VERSION ""

NS_ :

BS_:

BU_: MCU IPU MCU_B BMS ECC VCU EVCC MCU_F HDCU LBMS VCU5_0 VCU_BMS GW EOP Tester IDC

BO_ 384 EOP_1: 64 EOP
 SG_ EOP_1_CRC : 7|16@0+ (1,0) [0|65535] ""  MCU,VCU
 SG_ EOP_1_Counter : 23|8@0+ (1,0) [0|255] ""  MCU,VCU
 SG_ EOP_SpdAct : 29|12@0+ (1,0) [0|4000] "rpm"  MCU,VCU
 SG_ EOP_IdcAct : 55|8@0+ (0.1,0) [0|25] "A"  MCU,VCU
 SG_ EOP_IphAct : 33|10@0+ (0.1,0) [0|50] "A"  MCU,VCU
 SG_ EOP_UdcAct : 63|8@0+ (0.1,0) [0|25] "V"  MCU,VCU
 SG_ EOP_Status : 71|3@0+ (1,0) [0|4] ""  MCU,VCU
 SG_ EOP_duty : 79|7@0+ (1,0) [0|100] "%"  MCU,VCU
 SG_ EOP_ErrLevel : 68|3@0+ (1,0) [0|7] ""  MCU,VCU

BO_ 2015 Fun_Diag_Rx: 64 Tester
 SG_ Fun_Diag_Request : 7|512@0+ (1,0) [0|0] ""  MCU

BO_ 1790 NIDU_UDS_Diag_Tx: 64 MCU
 SG_ NIDU_UDS_Diag_Response : 7|64@0+ (1,0) [0|0] ""  Tester

BO_ 1662 NIDU_UDS_Diag_Rx: 64 Tester
 SG_ NIDU_UDS_Diag_Request : 7|64@0+ (1,0) [0|0] ""  MCU

BO_ 2028 NIDU_OBD_Diag_Tx: 64 MCU
 SG_ NIDU_OBD_Diag_Response : 7|64@0+ (1,0) [0|0] ""  Tester

BO_ 2020 NIDU_OBD_Diag_Rx: 64 Tester
 SG_ NIDU_OBD_Diag_Request : 7|64@0+ (1,0) [0|0] ""  MCU

BO_ 2683306023 DCU_1: 64 MCU
 SG_ DCU_1_CRC : 7|16@0+ (1,0) [0|65535] ""  VCU,GW,BMS
 SG_ DCU_1_Counter : 23|8@0+ (1,0) [0|255] ""  VCU,GW,BMS
 SG_ DCU_RotSpdAct : 31|16@0+ (1,-32767) [-32767|32766] "rpm"  VCU,GW
 SG_ DCU_IdcAct : 47|11@0+ (1,-1023) [-1023|1024] "A"  VCU,GW,BMS
 SG_ DCU_UdcAct : 52|10@0+ (1,0) [0|1023] "V"  VCU,GW,BMS
 SG_ DCU_ErrorLv3St : 58|1@0+ (1,0) [0|1] ""  VCU
 SG_ DCU_CCUEOPPowerSup : 57|2@0+ (1,0) [0|3] ""  VCU
 SG_ DCU_ModeSt : 79|4@0+ (1,0) [0|15] ""  VCU,BMS
 SG_ DCU_TorqMax : 75|10@0+ (1,0) [0|1023] "Nm"  VCU,GW
 SG_ DCU_TorqMin : 95|10@0+ (1,-1023) [-1023|0] "Nm"  VCU,GW
 SG_ DCU_SelfTorqMax : 101|10@0+ (1,0) [0|1023] "Nm"  VCU,GW
 SG_ DCU_SelfTorqMin : 106|10@0+ (1,-1023) [-1023|0] "Nm"  VCU,GW
 SG_ DCU_DstActive : 112|1@0+ (1,0) [0|1] ""  VCU,GW
 SG_ DCU_GateDrvSt : 127|2@0+ (1,0) [0|3] ""  VCU
 SG_ DCU_DiagErrCode : 125|6@0+ (1,0) [0|63] ""  VCU
 SG_ DCU_DMCInternalTorqSet : 134|11@0+ (1,-1023) [-1023|1024] "Nm"  Tester
 SG_ DCU_DMCInternalInit : 135|1@0+ (1,0) [0|1] ""  Tester
 SG_ DCU_DMCInternalInputQF : 107|1@0+ (1,0) [0|1] ""  Tester
 SG_ DCU_DMCOperationStToBCS : 139|3@0+ (1,0) [0|7] ""  VCU
 SG_ DCU_DMCoutputTorqToBCS : 136|16@0+ (1,-30000) [-30000|30000] "Nm"  VCU
 SG_ DCU_DMCVariantInfoToBCS : 175|6@0+ (1,0) [0|63] ""  VCU
 SG_ DCU_DMCVersionInfoToBCS : 167|8@0+ (1,0) [0|255] ""  VCU
 SG_ DCU_TorqAct : 169|13@0+ (0.2,-819) [-819|819] "Nm"  VCU
 SG_ DCU_EOP_SpdSet : 188|12@0+ (1,0) [0|4000] "rpm"  VCU
 SG_ DCU_Fault2 : 299|30@0+ (1,0) [0|1073741823] ""  VCU
 SG_ DCU_Fault3 : 265|30@0+ (1,0) [0|1073741823] ""  VCU
 SG_ DCU_Fault6 : 247|30@0+ (1,0) [0|1073741823] ""  VCU
 SG_ DCU_TrefFinal : 333|11@0+ (1,-1000) [-1000|1047] ""  VCU
 SG_ DCU_Iq : 338|15@0+ (0.1,-1500) [-1500|1776.7] ""  VCU
 SG_ DCU_Id : 355|15@0+ (0.1,-1500) [-1500|1776.7] ""  VCU
 SG_ DCU_iCurqRef : 372|15@0+ (0.1,-1500) [-1500|1776.7] ""  VCU
 SG_ DCU_iCurdRef : 389|15@0+ (0.1,-1500) [-1500|1776.7] ""  VCU
 SG_ DCU_1_FreshnessValue : 455|16@0+ (1,0) [0|255] ""  Tester
 SG_ DCU_1_MAC_Check : 471|48@0+ (1,0) [0|255] ""  Tester

BO_ 2683306024 DCU_2: 64 MCU
 SG_ DCU_Fault1 : 473|30@0+ (1,0) [0|1073741823] ""  VCU,GW
 SG_ DCU_2_CRC : 7|16@0+ (1,0) [0|65535] ""  VCU,GW
 SG_ DCU_2_Counter : 23|8@0+ (1,0) [0|255] ""  VCU,GW
 SG_ DCU_BoostChgPwrMax : 31|7@0+ (1,0) [0|120] "kW"  VCU,GW
 SG_ DCU_AHF_ActPwr : 24|10@0+ (20,0) [0|20460] "W"  VCU,GW
 SG_ DCU_RemoteDiagCode : 56|2@0+ (1,0) [0|3] ""  GW
 SG_ DCU_TypeSt : 70|4@0+ (1,0) [0|15] ""  VCU
 SG_ DCU_bDiagReq : 66|1@0+ (1,0) [0|1] ""  GW
 SG_ DCU_bReadyHV : 65|1@0+ (1,0) [0|1] ""  GW
 SG_ DCU_OffsetCalInd : 64|1@0+ (1,0) [0|1] ""  VCU
 SG_ DCU_DisChgPwrMax : 79|7@0+ (1,0) [0|120] "kW"  VCU
 SG_ DCU_InvtTemp : 72|8@0+ (1,-40) [-40|215] "degC"  VCU
 SG_ DCU_VoltageT30 : 80|6@0+ (0.5,0) [0|31.5] "V"  GW
 SG_ DCU_SysTempOvrInd : 90|1@0+ (1,0) [0|1] ""  GW
 SG_ DCU_RotTemp : 89|9@0+ (1,-40) [-40|471] "degC"  VCU
 SG_ DCU_CooltReq : 96|6@0+ (0.25,0) [0|15.5] "L/min"  VCU
 SG_ DCU_FaultLampInd : 106|1@0+ (1,0) [0|1] ""  VCU,GW
 SG_ DCU_StatTemp : 105|9@0+ (1,-40) [-40|470] "degC"  VCU
 SG_ DCU_TempCoolant : 112|8@0+ (1,-40) [-40|215] "degC"  VCU,GW
 SG_ DCU_ErrNoticeOperationFlag : 120|1@0+ (1,0) [0|1] ""  VCU,GW
 SG_ DCU_ErrNotice : 135|3@0+ (1,0) [0|7] ""  VCU,GW
 SG_ DCU_Err2NoticeFlag : 132|1@0+ (1,0) [0|1] ""  VCU,GW
 SG_ DCU_Fault5 : 138|30@0+ (1,0) [0|1073741823] ""  VCU,GW
 SG_ DCU_TEL_MotorNumOrder : 194|3@0+ (1,0) [0|7] ""  VCU,GW
 SG_ DCU_TEL_ECUTempOvrErr : 195|1@0+ (1,0) [0|1] ""  VCU,GW
 SG_ DCU_TEL_MotTempOvrErr : 196|1@0+ (1,0) [0|1] ""  VCU,GW
 SG_ DCU_TEL_MotorNumTotal : 199|3@0+ (1,0) [0|7] ""  VCU,GW
 SG_ DCU_TEL_InvtTemp : 207|8@0+ (1,-40) [-40|215] "deg"  VCU,GW
 SG_ DCU_TEL_RotSpdAct : 215|16@0+ (1,-20000) [-20000|45535] "rpm"  VCU,GW
 SG_ DCU_TEL_TorqAct : 231|16@0+ (0.1,-2000) [-2000|4553.5] "Nm"  VCU,GW
 SG_ DCU_TEL_StatTemp : 247|8@0+ (1,-40) [-40|215] "deg"  VCU,GW
 SG_ DCU_TEL_ModeSt : 293|3@0+ (1,0) [0|7] ""  VCU,GW
 SG_ DCU_TEL_CurrActAmend : 255|16@0+ (0.1,-1000) [-1000|1000] "A"  VCU,GW
 SG_ DCU_TEL_UdcAct : 181|14@0+ (0.1,0) [0|1000] "V"  VCU,GW
 SG_ DCU_TEL_BattCurr : 271|16@0+ (0.1,-1000) [-1000|1000] "A"  VCU,GW
 SG_ DCU_BoostCurrMax : 55|8@0+ (1,0) [0|255] "A"  VCU
 SG_ DCU_BuckCurrMax : 131|8@0+ (1,0) [0|255] "A"  VCU
 SG_ DCU_K2RlyAdhmode : 139|1@0+ (1,0) [0|1] ""  VCU,BMS
 SG_ DCU_IgnitionSt : 439|1@0+ (1,0) [0|1] ""  VCU
 SG_ DCU_TEL_OverSpdErr : 171|1@0+ (1,0) [0|1] ""  VCU
 SG_ DCU_TEL_OverCurrErr : 172|1@0+ (1,0) [0|1] ""  VCU
 SG_ Reserved1 : 440|1@0+ (1,0) [0|0] ""  VCU
 SG_ DCU_Fault4 : 455|30@0+ (1,0) [0|1073741823] ""  VCU

BO_ 408 BMC_1: 64 BMS
 SG_ BMC_1_CRC : 7|16@0+ (1,0) [0|65535] ""  MCU
 SG_ BMC_1_Counter : 23|8@0+ (1,0) [0|255] ""  MCU
 SG_ BMC_BattVolt : 54|10@0+ (1,0) [0|1000] "V"  MCU
 SG_ BMC_DCUBattSt : 56|1@0+ (1,0) [0|1] ""  MCU
 SG_ BMC_PwrDwnReq : 71|1@0+ (1,0) [0|1] ""  MCU
 SG_ BMC_BoostChgModeReq : 68|2@0+ (1,0) [0|3] ""  MCU

BO_ 2683306021 DCU_DEBUG_1: 32 MCU
 SG_ DCU_BSWVersion_Debug : 112|32@0+ (1,0) [0|4294967295] ""  Tester
 SG_ DCU_OffsetCalSt : 114|2@0+ (1,0) [0|3] ""  Tester
 SG_ DCU_OffsetAngleCal : 15|16@0+ (1,0) [0|65535] ""  Tester
 SG_ DCU_EOP_OilTempAct : 7|8@0+ (1,-40) [-40|180] "degC"  Tester
 SG_ DCU_Debug_1Bit_1 : 95|1@0+ (1,0) [0|1] "-"  Tester
 SG_ DCU_Ignition : 94|1@0+ (1,0) [0|1] ""  Tester
 SG_ DCU_OffsetAngle_Debug : 91|12@0+ (1,0) [0|4095] "-"  Tester
 SG_ DCU_StoreDataSt : 93|2@0+ (1,0) [0|3] ""  Tester
 SG_ DCU_SendDataSt : 115|1@0+ (1,0) [0|1] ""  Tester
 SG_ DCU_BootSV_Debug : 111|12@0+ (1,0) [0|4095] "-"  Tester
 SG_ DCU_Hwversion_Debug : 31|16@0+ (1,0) [0|65535] "-"  Tester
 SG_ DCU_Swversion_Debug : 47|16@0+ (1,0) [0|65535] "-"  Tester
 SG_ DCU_SwVerExt_Debug : 63|32@0+ (1,0) [0|4294967295] "-"  Tester

BO_ 2683306010 DCU_DEBUG_2: 32 MCU
 SG_ DCU_CapTemp_Debug : 23|8@0+ (1,-40) [-40|215] "degC"  Tester
 SG_ DCU_CtlBoardTemp_Debug : 15|8@0+ (1,-40) [-40|215] "degC"  Tester
 SG_ DCU_PWMFreq_Debug : 63|12@0+ (10,0) [0|40950] "Hz"  Tester
 SG_ DCU_IgbtNtcTempMax : 7|8@0+ (1,-40) [-40|215] "degC"  Tester
 SG_ DCU_Debug_1Bit_2 : 67|1@0+ (1,0) [0|1] "-"  Tester
 SG_ DCU_Debug_1Bit_3 : 66|1@0+ (1,0) [0|1] ""  Tester
 SG_ DCU_Debug_16Bit_2 : 31|16@0+ (1,0) [0|65535] ""  Tester
 SG_ DCU_Debug_16Bit_3 : 47|16@0+ (1,0) [0|65535] ""  Tester

BO_ 2683305995 DCU_DEBUG_3: 64 MCU
 SG_ DCU_FusaFaultInfo8_Debug : 461|32@0+ (1,0) [0|4294967295] ""  Tester
 SG_ DCU_FusaFaultInfo7_Debug : 429|32@0+ (1,0) [0|4294967295] ""  Tester
 SG_ DCU_TempCoolant : 421|8@0+ (1,-40) [-40|215] "degC"  Tester
 SG_ DCU_FusaTorqAct_Debug : 402|13@0+ (0.2,-819) [-819|819] ""  Tester
 SG_ DCU_FusaRotSpdAct_Debug : 386|16@0+ (1,-32767) [-32767|32766] ""  Tester
 SG_ DCU_FusaErrCode_Debug : 376|6@0+ (1,0) [0|63] ""  Tester
 SG_ DCU_FusastPWMEna_Debug : 377|1@0+ (1,0) [0|1] ""  Tester
 SG_ DCU_FusaQDisChargeReq_Debug : 378|1@0+ (1,0) [0|0] ""  Tester
 SG_ DCU_FusaModeSt_Debug : 382|4@0+ (1,0) [0|15] ""  Tester
 SG_ DCU_FusastSafePathReq_Debug : 369|3@0+ (1,0) [0|7] ""  Tester
 SG_ DCU_DataFaultHandle : 373|4@0+ (1,0) [0|15] ""  Tester
 SG_ DCU_stTorqLmtTsc : 240|22@0+ (1,0) [0|4194303] "-"  Tester
 SG_ DCU_TrqAntiJerk : 7|8@0+ (1,-127) [-127|128] "Nm"  Tester
 SG_ DCU_TrefFinal_Debug : 266|11@0+ (1,-1000) [-1000|1047] "Nm"  Tester
 SG_ DCU_Iq_Debug : 287|15@0+ (0.1,-1500) [-1500|1776.7] "A"  Tester
 SG_ DCU_Id_Debug : 288|15@0+ (0.1,-1500) [-1500|1776.7] "A"  Tester
 SG_ DCU_Debug_1Bit_4 : 239|1@0+ (1,0) [0|1] ""  Tester
 SG_ DCU_Debug_8Bit_4 : 15|8@0+ (1,0) [0|255] "-"  Tester
 SG_ DCU_Debug_16Bit_4 : 23|16@0+ (1,0) [0|65535] "-"  Tester
 SG_ DCU_Fault6_Debug : 39|32@0+ (1,0) [0|65535] ""  Tester
 SG_ DCU_Fault5_Debug : 71|32@0+ (1,0) [0|65535] "-"  Tester
 SG_ DCU_Fault4_Debug : 103|32@0+ (1,0) [0|65535] "-"  Tester
 SG_ DCU_Fault3_Debug : 135|32@0+ (1,0) [0|1048575] "-"  Tester
 SG_ DCU_Fault2_Debug : 167|32@0+ (1,0) [0|1048575] "-"  Tester
 SG_ DCU_Fault1_Debug : 199|32@0+ (1,0) [0|1048575] "-"  Tester
 SG_ DCU_TjMax : 231|8@0+ (1,-40) [-40|215] "degC"  Tester
 SG_ DCU_VoltUtilRatio : 238|7@0+ (0.01,0) [0|1.27] ""  Tester
 SG_ DCU_TorqueRatio : 247|7@0+ (0.01,0) [0|1.27] ""  Tester
 SG_ DCU_iCurqRef_Debug : 305|15@0+ (0.1,-1500) [-1500|1776.7] "A"  Tester
 SG_ DCU_iCurdRef_Debug : 322|15@0+ (0.1,-1500) [-1500|1776.7] "A"  Tester
 SG_ DCU_uVoltqRef : 339|15@0+ (0.1,-1500) [-1500|1776.7] "V"  Tester
 SG_ DCU_uVoltdRef : 356|15@0+ (0.1,-1500) [-1500|1776.7] "V"  Tester

BO_ 2683305999 DCU_DEBUG_6: 32 MCU
 SG_ DCU_Debug_IdcEst : 59|15@0+ (0.1,-1500) [-1500|1776.7] "A"  Tester
 SG_ DCU_Debug_TorqEstByPower : 42|15@0+ (0.1,-1500) [-1500|1776.7] "Nm"  Tester
 SG_ DCU_Debug_TorqEstByTable : 25|15@0+ (0.1,-1500) [-1500|1776.7] "Nm"  Tester
 SG_ DCU_Debug_Iq : 8|15@0+ (0.1,-1500) [-1500|1776.7] "A"  Tester
 SG_ DCU_Debug_Id : 7|15@0+ (0.1,-1500) [-1500|1776.7] "A"  Tester

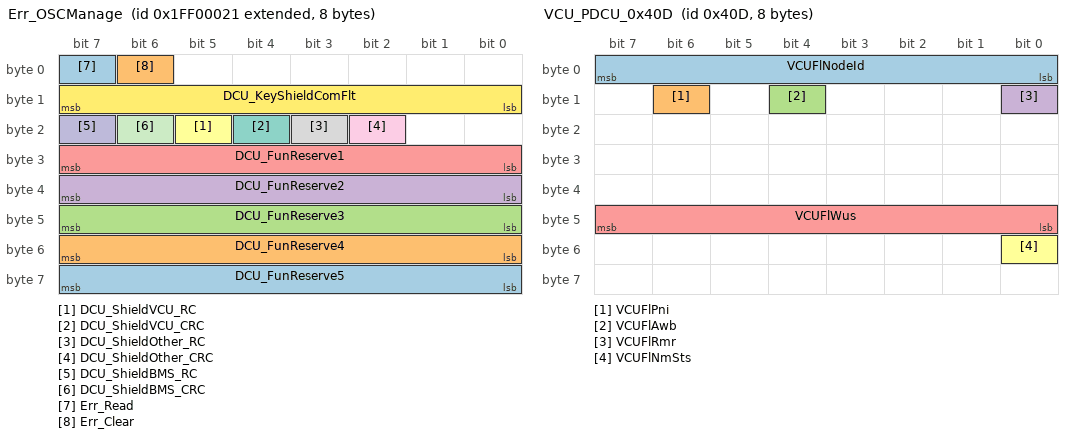
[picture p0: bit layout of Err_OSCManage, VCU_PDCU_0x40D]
BO_ 2683306017 Err_OSCManage: 8 Tester
 SG_ DCU_FunReserve5 : 63|8@0+ (1,0) [0|255] "-"  Tester
 SG_ DCU_FunReserve4 : 55|8@0+ (1,0) [0|255] "-"  Tester
 SG_ DCU_FunReserve3 : 47|8@0+ (1,0) [0|255] "-"  Tester
 SG_ DCU_FunReserve2 : 39|8@0+ (1,0) [0|255] "-"  Tester
 SG_ DCU_FunReserve1 : 31|8@0+ (1,0) [0|255] "-"  Tester
 SG_ DCU_ShieldVCU_RC : 21|1@0+ (1,0) [0|1] "-"  Tester
 SG_ DCU_ShieldVCU_CRC : 20|1@0+ (1,0) [0|1] "-"  Tester
 SG_ DCU_ShieldOther_RC : 19|1@0+ (1,0) [0|1] "-"  Tester
 SG_ DCU_ShieldOther_CRC : 18|1@0+ (1,0) [0|1] "-"  Tester
 SG_ DCU_ShieldBMS_RC : 23|1@0+ (1,0) [0|1] "-"  Tester
 SG_ DCU_ShieldBMS_CRC : 22|1@0+ (1,0) [0|1] "-"  Tester
 SG_ DCU_KeyShieldComFlt : 15|8@0+ (1,0) [0|255] "-"  Tester
 SG_ Err_Read : 7|1@0+ (1,0) [0|1] ""  MCU
 SG_ Err_Clear : 6|1@0+ (1,0) [0|0] ""  MCU

BO_ 2634022913 XCP_Frame_Tx: 8 MCU
 SG_ XCP_Data_Tx : 7|64@0+ (1,0) [0|0] ""  Tester

BO_ 2634022912 XCP_Frame_Rx: 8 Tester
 SG_ XCP_Data_Rx : 7|64@0+ (1,0) [0|0] ""  MCU

BO_ 2683306022 DCU_BigData: 64 MCU
 SG_ DCU_BigNO1_1Bit2 m1 : 504|1@0+ (1,0) [0|1] "-"  Tester
 SG_ DCU_BigNO1_1Bit1 m1 : 505|1@0+ (1,0) [0|1] "-"  Tester
 SG_ DCU_stL2TorqRep m1 : 488|1@0+ (1,0) [0|1] "-"  Tester
 SG_ DCU_stL2SpdRep m1 : 503|1@0+ (1,0) [0|1] "-"  Tester
 SG_ DCU_stL2DCVoltRep m1 : 502|1@0+ (1,0) [0|1] "-"  Tester
 SG_ DCU_BigNO1_8Bit1 m1 : 501|8@0+ (1,0) [0|255] "-"  Tester
 SG_ DCU_BigNO1_4Bit1 m1 : 509|4@0+ (1,0) [0|15] "-"  Tester
 SG_ DCU_stL2SignalRep m2 : 460|2@0+ (1,0) [0|3] ""  Tester
 SG_ DCU_stL2ShutOff m2 : 463|3@0+ (1,0) [0|7] ""  Tester
 SG_ DCU_stFbTopASC m2 : 458|1@0+ (1,0) [0|1] "-"  Tester
 SG_ DCU_stFbFSEnb m2 : 456|1@0+ (1,0) [0|1] "-"  Tester
 SG_ DCU_stFbBottomASC m2 : 457|1@0+ (1,0) [0|1] "-"  Tester
 SG_ DCU_McaWT_Duty m2 : 487|8@0+ (1,0) [0|255] ""  Tester
 SG_ DCU_McaVT_Duty m2 : 479|8@0+ (1,0) [0|255] ""  Tester
 SG_ DCU_McaUT_Duty m2 : 471|8@0+ (1,0) [0|255] ""  Tester
 SG_ DCU_ResInCosVal m2 : 503|8@0+ (80,-10200) [-10200|10200] ""  Tester
 SG_ DCU_FbVB_Duty m2 : 447|8@0+ (1,0) [0|255] ""  Tester
 SG_ DCU_TopDrvICInitflg m1 : 492|1@0+ (1,0) [0|1] "-"  Tester
 SG_ DCU_IsLmtL2 m1 : 432|10@0+ (1,0) [0|1023] ""  Tester
 SG_ DCU_iPhaCurWOfs m1 : 460|10@0+ (4,0) [0|4092] ""  Tester
 SG_ DCU_iPhaCurVOfs m1 : 466|10@0+ (4,0) [0|4092] ""  Tester
 SG_ DCU_iPhaCurUOfs m1 : 454|10@0+ (4,0) [0|4092] ""  Tester
 SG_ DCU_CapTempEst m1 : 472|8@0+ (1,-40) [-40|214] "degC"  Tester
 SG_ DCU_BomDrvICInitflg m1 : 491|1@0+ (1,0) [0|1] "-"  Tester
 SG_ DCU_uDCVoltL2 m1 : 427|11@0+ (1,0) [0|2047] ""  Tester
 SG_ DCU_FusastL2SPCflg m1 : 489|1@0+ (1,0) [0|1] ""  Tester
 SG_ DCU_FusastL3SPCflg m1 : 490|1@0+ (1,0) [0|1] ""  Tester
 SG_ DCU_FusaInModeSt m1 : 480|4@0+ (1,0) [0|15] ""  Tester
 SG_ DCU_uDrvLVBackupVolt m2 : 511|8@0+ (1,0) [0|255] ""  Tester
 SG_ DCU_Data1No M : 7|8@0+ (1,0) [0|205] ""  Tester
 SG_ DCU_Hwversion m1 : 15|16@0+ (1,0) [0|65535] ""  Tester
 SG_ DCU_Swversion m1 : 31|16@0+ (1,0) [0|65535] ""  Tester
 SG_ DCU_SwVerExt m1 : 47|32@0+ (1,0) [0|4294967295] ""  Tester
 SG_ DCU_OffsetAngle m1 : 79|12@0+ (1,0) [0|4095] ""  Tester
 SG_ DCU_BootSV m1 : 83|12@0+ (1,0) [0|4095] ""  Tester
 SG_ DCU_BSWVersion m1 : 103|32@0+ (1,0) [0|4294967295] ""  Tester
 SG_ DCU_HWConfig m1 : 135|32@0+ (1,0) [0|4294967295] ""  Tester
 SG_ DCU_SWConfig m1 : 167|32@0+ (1,0) [0|4294967295] ""  Tester
 SG_ DCU_MCAConfig m1 : 199|32@0+ (1,0) [0|4294967295] ""  Tester
 SG_ DCU_FHConfig m1 : 231|32@0+ (1,0) [0|4294967295] ""  Tester
 SG_ DCU_InvtPhaUTemp m1 : 263|8@0+ (1,-40) [-40|214] "degC"  Tester
 SG_ DCU_InvtPhaVTemp m1 : 271|8@0+ (1,-40) [-40|214] "degC"  Tester
 SG_ DCU_InvtPhaWTemp m1 : 279|8@0+ (1,-40) [-40|214] "degC"  Tester
 SG_ DCU_Stat1Temp m1 : 287|8@0+ (1,-40) [-40|214] "degC"  Tester
 SG_ DCU_Stat2Temp m1 : 295|8@0+ (1,-40) [-40|214] "degC"  Tester
 SG_ DCU_CtrlBoardTemp m1 : 303|8@0+ (1,-40) [-40|214] "degC"  Tester
 SG_ DCU_DrvBoardTemp m1 : 311|8@0+ (1,-40) [-40|214] "degC"  Tester
 SG_ DCU_CapTemp m1 : 319|8@0+ (1,-40) [-40|214] "degC"  Tester
 SG_ DCU_FusastSafePathReq m1 : 327|3@0+ (1,0) [0|7] ""  Tester
 SG_ DCU_FusaModeSt m1 : 324|4@0+ (1,0) [0|15] ""  Tester
 SG_ DCU_FusaQDisChargeReq m1 : 320|1@0+ (1,0) [0|1] ""  Tester
 SG_ DCU_FusastPWMEna m1 : 335|1@0+ (1,0) [0|1] ""  Tester
 SG_ DCU_FusaErrCode m1 : 334|6@0+ (1,0) [0|63] ""  Tester
 SG_ DCU_FusaRotSpdAct m1 : 328|16@0+ (1,-32767) [-32767|32766] ""  Tester
 SG_ DCU_FusaTorqAct m1 : 344|13@0+ (0.2,-819) [-819|819] ""  Tester
 SG_ DCU_FusaFaultInfo7 m1 : 363|32@0+ (1,0) [0|4294967295] ""  Tester
 SG_ DCU_FusaFaultInfo8 m1 : 395|32@0+ (1,0) [0|4294967295] ""  Tester
 SG_ DCU_FaultData_RC m2 : 15|8@0+ (1,0) [0|255] ""  Tester
 SG_ DCU_stHandleOff m2 : 23|1@0+ (1,0) [0|1] ""  Tester
 SG_ DCU_stPWMEna m2 : 22|1@0+ (1,0) [0|1] ""  Tester
 SG_ DCU_stMode m2 : 21|4@0+ (1,0) [0|15] ""  Tester
 SG_ DCU_FailCode m2 : 17|10@0+ (1,0) [0|1023] ""  Tester
 SG_ DCU_stASCProt m2 : 39|16@0+ (1,0) [0|65535] ""  Tester
 SG_ DCU_agRotorPosn m2 : 55|12@0+ (1,0) [0|4095] ""  Tester
 SG_ DCU_RelativeTime m2 : 193|18@0+ (1,0) [0|262143] "s"  Tester
 SG_ DCU_stFaultFlag100us m2 : 223|16@0+ (1,0) [0|65535] ""  Tester
 SG_ DCU_PWMFreq m2 : 239|16@0+ (1,0) [0|65535] "Hz"  Tester
 SG_ DCU_uDcVolt m2 : 255|10@0+ (1,0) [0|1023] "V"  Tester
 SG_ DCU_uLowVolt m2 : 261|8@0+ (0.1,0) [0|25.5] "V"  Tester
 SG_ DCU_iCurdFinalRef m2 : 59|12@0+ (1,-2048) [-2048|2047] "A"  Tester
 SG_ DCU_iCurqFinalRef m2 : 79|12@0+ (1,-2048) [-2048|2047] "A"  Tester
 SG_ DCU_iCurdFb m2 : 83|12@0+ (1,-2048) [-2048|2047] "A"  Tester
 SG_ DCU_iCurqFb m2 : 103|12@0+ (1,-2048) [-2048|2047] "A"  Tester
 SG_ DCU_iPhaCurU m2 : 107|12@0+ (1,-2048) [-2048|2047] "A"  Tester
 SG_ DCU_iPhaCurV m2 : 127|12@0+ (1,-2048) [-2048|2047] "A"  Tester
 SG_ DCU_iPhaCurW m2 : 131|12@0+ (1,-2048) [-2048|2047] "A"  Tester
 SG_ DCU_uVoltdFinalRef m2 : 151|12@0+ (1,-2048) [-2048|2047] "V"  Tester
 SG_ DCU_uVoltqFinalRef m2 : 155|12@0+ (1,-2048) [-2048|2047] "V"  Tester
 SG_ DCU_iDcCur m2 : 175|12@0+ (1,-2048) [-2048|2047] "A"  Tester
 SG_ DCU_ResFaultFlag m2 : 269|16@0+ (1,0) [0|65535] ""  Tester
 SG_ DCU_stTsc m2 : 285|16@0+ (1,0) [0|65535] ""  Tester
 SG_ DCU_OperatingCycle m2 : 179|18@0+ (1,0) [0|262143] ""  Tester
 SG_ DCU_Year m2 : 317|8@0+ (1,2000) [2000|2255] "Y"  Tester
 SG_ DCU_Month m2 : 325|4@0+ (1,0) [1|12] "M"  Tester
 SG_ DCU_Day m2 : 321|5@0+ (1,0) [1|31] "D"  Tester
 SG_ DCU_Hour m2 : 332|5@0+ (1,0) [0|23] "h"  Tester
 SG_ DCU_Minute m2 : 343|6@0+ (1,0) [0|59] "m"  Tester
 SG_ DCU_Second m2 : 337|6@0+ (1,0) [0|59] "s"  Tester
 SG_ DCU_stIgnition m2 : 355|1@0+ (1,0) [0|1] ""  Tester
 SG_ DCU_OverCurrCount m2 : 354|2@0+ (1,0) [0|3] ""  Tester
 SG_ DCU_stFS0B m2 : 352|1@0+ (1,0) [0|1] ""  Tester
 SG_ DCU_stDrvCtrlMode m2 : 359|4@0+ (1,0) [0|15] ""  Tester
 SG_ DCU_FbUT_Duty m2 : 415|8@0+ (1,0) [0|255] ""  Tester
 SG_ DCU_ResInSinVal m2 : 495|8@0+ (80,-10200) [-10200|10200] ""  Tester
 SG_ DCU_stIGBTFault m2 : 301|16@0+ (1,0) [0|65535] ""  Tester
 SG_ DCU_stBigDataTrigger m2 : 347|4@0+ (1,0) [0|15] ""  Tester
 SG_ DCU_RegUT_Duty m2 : 383|8@0+ (1,0) [0|255] ""  Tester
 SG_ DCU_RegVT_Duty m2 : 391|8@0+ (1,0) [0|255] ""  Tester
 SG_ DCU_RegWT_Duty m2 : 399|8@0+ (1,0) [0|255] ""  Tester
 SG_ DCU_tiTspwmExeTime m2 : 407|8@0+ (2,0) [0|510] ""  Tester
 SG_ DCU_FbVT_Duty m2 : 423|8@0+ (1,0) [0|255] ""  Tester
 SG_ DCU_FbWT_Duty m2 : 431|8@0+ (1,0) [0|255] ""  Tester
 SG_ DCU_FbUB_Duty m2 : 439|8@0+ (1,0) [0|255] ""  Tester
 SG_ DCU_FbWB_Duty m2 : 455|8@0+ (1,0) [0|255] ""  Tester
 SG_ DCU_stSBCFault m2 : 367|16@0+ (1,0) [0|65535] ""  Tester

BO_ 2683306093 IPS_Debug_3: 64 Tester
 SG_ IPS_FUSE_PASSWORD : 7|8@0+ (1,0) [0|255] ""  MCU
 SG_ IPS_FUSE_ENABLE5 : 47|8@0+ (1,0) [0|255] ""  MCU
 SG_ IPS_FUSE_ENABLE4 : 39|8@0+ (1,0) [0|255] ""  MCU
 SG_ IPS_FUSE_ENABLE3 : 31|8@0+ (1,0) [0|255] ""  MCU
 SG_ IPS_FUSE_ENABLE2 : 23|8@0+ (1,0) [0|255] ""  MCU
 SG_ IPS_FUSE_ENABLE1 : 15|8@0+ (1,0) [0|255] ""  MCU
 SG_ IPS_FUSE_ENABLE : 48|1@0+ (1,0) [0|1] ""  MCU

BO_ 2683306000 IPS_Debug_1: 64 Tester
 SG_ IPS_Password : 7|8@0+ (1,0) [0|255] "-"  MCU
 SG_ IPS_TEL_DCDCFaultLampInd2 : 8|1@0+ (1,0) [0|1] "-"  MCU
 SG_ IPS_TEL_DCDCTempOvrErr2 : 9|1@0+ (1,0) [0|1] "-"  MCU
 SG_ IPS_Disable_CC : 12|3@0+ (1,0) [0|7] ""  MCU
 SG_ IPS_Disable_CP : 15|3@0+ (1,0) [0|7] "-"  MCU
 SG_ IPS_Disable_RCChecksum : 16|1@0+ (1,0) [0|1] "-"  MCU
 SG_ IPS_DCDCSet : 17|1@0+ (1,0) [0|1] "-"  MCU
 SG_ IPS_OBCSet : 18|1@0+ (1,0) [0|1] ""  MCU
 SG_ IPS_OBCHvVoltLimSet : 19|1@0+ (1,0) [0|1] ""  MCU
 SG_ IPS_Disable_DCDCSelfChck : 20|1@0+ (1,0) [0|1] ""  MCU
 SG_ IPS_DCDCLvVoltSet : 31|10@0+ (0.1,0) [0|102.3] "V"  MCU
 SG_ IPS_OBCChgVoltReqManCal : 37|10@0+ (1,0) [0|1023] "V"  MCU
 SG_ IPS_OBCChgCurrReqManCal : 43|10@0+ (0.1,0) [0|102.3] "A"  MCU
 SG_ IPS_OBCDchgDcCurrLim : 49|10@0+ (0.1,0) [0|102.3] "A"  MCU

BO_ 2683306012 IPS_Debug_2: 64 MCU
 SG_ IPS_FUSA_Core1_DC_DisableFb : 77|1@0+ (1,0) [0|1] ""  Tester
 SG_ IPS_FUSA_OBCTemp3ADFb : 445|12@0+ (1,0) [0|4095] ""  Tester
 SG_ IPS_FUSA_OBCTemp2ADFb : 449|12@0+ (1,0) [0|4095] ""  Tester
 SG_ IPS_FUSA_OBCTemp1ADFb : 469|12@0+ (1,0) [0|4095] ""  Tester
 SG_ IPS_FUSA_LVCCVoltValueFb : 473|8@0+ (0.1,0) [0|25.5] "V"  Tester
 SG_ IPS_FUSA_LV40VVoltValueFb : 199|10@0+ (0.1,0) [0|102.3] ""  Tester
 SG_ IPS_FUSA_DCDCTemp2ADFb : 501|12@0+ (1,0) [0|4095] ""  Tester
 SG_ IPS_FUSA_DCDCTemp1ADFb : 481|12@0+ (1,0) [0|4095] ""  Tester
 SG_ IPS_FUSA_DCDCLvVsVoltValueFb : 421|9@0+ (0.1,0) [0|51.1] "V"  Tester
 SG_ IPS_FUSA_DCDCLvVsVoltADFb : 425|12@0+ (1,0) [0|4095] ""  Tester
 SG_ IPS_FUSA_DCDCLvVdVoltValueFb : 401|9@0+ (0.1,0) [0|51.1] "V"  Tester
 SG_ IPS_FUSA_DCDCLvVdVoltADFb : 397|12@0+ (1,0) [0|4095] ""  Tester
 SG_ IPS_FUSA_DCDCLvCur2ValueFb : 391|10@0+ (1,-511) [-511|512] "A"  Tester
 SG_ IPS_FUSA_DCDCLvCur2ADFb : 317|12@0+ (1,0) [0|4095] ""  Tester
 SG_ IPS_FUSA_DCDCLvCur1ValueFb : 297|10@0+ (1,-511) [-511|512] "A"  Tester
 SG_ IPS_FUSA_DCDCLvCur1ADFb : 293|12@0+ (1,0) [0|4095] ""  Tester
 SG_ IPS_FUSA_Core1_OBCSt : 98|3@0+ (1,0) [0|7] ""  Tester
 SG_ IPS_FUSA_Core1_MCUSBC_Byte6 : 383|8@0+ (1,0) [0|255] ""  Tester
 SG_ IPS_FUSA_Core1_MCUSBC_Byte5 : 375|8@0+ (1,0) [0|255] ""  Tester
 SG_ IPS_FUSA_Core1_MCUSBC_Byte4 : 367|8@0+ (1,0) [0|255] ""  Tester
 SG_ IPS_FUSA_Core1_MCUSBC_Byte3 : 359|8@0+ (1,0) [0|255] ""  Tester
 SG_ IPS_FUSA_Core1_MCUSBC_Byte2 : 351|8@0+ (1,0) [0|255] ""  Tester
 SG_ IPS_FUSA_Core1_MCUSBC_Byte1 : 343|8@0+ (1,0) [0|255] ""  Tester
 SG_ IPS_FUSA_Core1_MCUSBC_Byte0 : 335|8@0+ (1,0) [0|255] ""  Tester
 SG_ IPS_FUSA_Core1_LC_DisableFb : 76|1@0+ (1,0) [0|1] ""  Tester
 SG_ IPS_FUSA_Core1_LC_Ctrl_Req : 56|1@0+ (1,0) [0|1] ""  Tester
 SG_ IPS_FUSA_Core1_HIVLDCSt : 242|3@0+ (1,0) [0|7] ""  Tester
 SG_ IPS_FUSA_Core1_HIVLACSt : 74|3@0+ (1,0) [0|7] ""  Tester
 SG_ IPS_FUSA_Core1_DCSt : 205|3@0+ (1,0) [0|7] ""  Tester
 SG_ IPS_FUSA_Core1_DC_Ctrl_Req : 57|1@0+ (1,0) [0|1] ""  Tester
 SG_ IPS_FUSA_Core1_CCSt : 202|3@0+ (1,0) [0|7] ""  Tester
 SG_ IPS_FUSA_CC2ResValueFb : 287|10@0+ (10,0) [0|10230] "|?"  Tester
 SG_ IPS_DcdcVersion : 279|8@0+ (1,0) [0|255] ""  Tester
 SG_ IPS_LlcVersion : 271|8@0+ (1,0) [0|255] ""  Tester
 SG_ IPS_PfcVersion : 263|8@0+ (1,0) [0|255] ""  Tester
 SG_ IPS_ocm_AswVersion : 255|8@0+ (1,0) [0|255] ""  Tester
 SG_ IPS_DiagDtcSetSt : 8|1@0+ (1,0) [0|1] ""  Tester
 SG_ IPS_DiagClrErr : 9|1@0+ (1,0) [0|1] ""  Tester
 SG_ IPS_pwrObcChgCap : 7|14@0+ (0.01,0) [0|163.83] "KW"  Tester
 SG_ IPS_PfcPwrModeSt : 27|4@0+ (1,0) [0|15] ""  Tester
 SG_ IPS_tPfcTemp : 23|12@0+ (0.1,-50) [-50|359.5] "degC"  Tester
 SG_ IPS_LLcPwrModeSt : 43|4@0+ (1,0) [0|15] ""  Tester
 SG_ IPS_fCpFrq : 39|12@0+ (1,0) [0|4095] "Hz"  Tester
 SG_ IPS_DcdcPwrModeSt : 61|4@0+ (1,0) [0|15] ""  Tester
 SG_ IPS_reAcIsoRes : 55|10@0+ (1,0) [0|1023] "KOhm"  Tester
 SG_ IPS_smd_uDcdcLvVoltSet : 71|10@0+ (0.1,0) [0|102.3] "V"  Tester
 SG_ IPS_fmd_DcdcFaultStopEn : 92|1@0+ (1,0) [0|1] ""  Tester
 SG_ IPS_fmo_ObcFaultStopEn : 93|1@0+ (1,0) [0|1] ""  Tester
 SG_ IPS_smo_dDchgCpDucyc : 87|10@0+ (0.1,0) [0|100] "%"  Tester
 SG_ IPS_smo_IsoTestEn : 101|3@0+ (1,0) [0|7] ""  Tester
 SG_ IPS_fmd_FsDcdcPwrOffEn : 102|1@0+ (1,0) [0|1] ""  Tester
 SG_ IPS_smd_FsDcdcOvpSelfChckSt : 103|1@0+ (1,0) [0|1] ""  Tester
 SG_ IPS_smo_iObcDcCurrLim : 117|4@0+ (1,0) [0|15] ""  Tester
 SG_ IPS_smo_ObcModeSet : 111|10@0+ (0.1,0) [0|102.3] "A"  Tester
 SG_ IPS_smo_uObcDcVoltSet : 113|10@0+ (1,0) [0|1023] "V"  Tester
 SG_ IPS_RelaySts : 139|4@0+ (1,0) [0|15] ""  Tester
 SG_ IPS_DcdcRadTemp : 135|12@0+ (0.1,-50) [-50|359.5] "degC"  Tester
 SG_ IPS_PfcVbulk : 151|14@0+ (0.1,0) [0|1638.3] "V"  Tester
 SG_ IPS_iObcHvCurr : 153|10@0+ (0.1,0) [0|102.3] "A"  Tester
 SG_ IPS_fmo_ObcFaultReset : 171|1@0+ (1,0) [0|1] ""  Tester
 SG_ IPS_fmd_DcdcFaultReset : 172|1@0+ (1,0) [0|1] ""  Tester
 SG_ IPS_smo_Cp9vTiOut : 173|1@0+ (1,0) [0|1] ""  Tester
 SG_ IPS_smo_Cp12vTiOut : 174|1@0+ (1,0) [0|1] ""  Tester
 SG_ IPS_spd_NmReq : 91|4@0+ (1,0) [0|15] ""  Tester
 SG_ IPS_smd_iDcdcLvCurrLim : 170|9@0+ (1,0) [0|511] "A"  Tester
 SG_ IPS_spo_iObcCcCpAcCurrLim : 177|10@0+ (0.1,0) [0|102.3] "A"  Tester
 SG_ IPS_DcdcSRSts : 215|4@0+ (1,0) [0|15] ""  Tester
 SG_ IPS_LlcWorkFreq : 211|12@0+ (0.1,0) [0|409.5] ""  Tester
 SG_ IPS_DcdcBuckDuty : 231|10@0+ (0.1,0) [0|100] "%"  Tester
 SG_ IPS_uFsDcdcLvVolt : 237|10@0+ (0.1,0) [0|102.3] "V"  Tester

BO_ 2683306025 IPS_1: 64 MCU
 SG_ IPS_1_CRC : 7|16@0+ (1,0) [0|65535] ""  VCU,GW,BMS
 SG_ IPS_1_Counter : 23|8@0+ (1,0) [0|255] ""  VCU,GW,BMS
 SG_ IPS_DCDCDiagErrCode : 31|8@0+ (1,0) [0|255] ""  VCU,GW
 SG_ IPS_DCDCModeSt : 39|3@0+ (1,0) [0|7] ""  VCU,GW
 SG_ IPS_KL15State : 36|1@0+ (1,0) [0|1] ""  Tester
 SG_ IPS_DCDCVoltLvAct : 35|10@0+ (0.1,0) [0|102.3] "V"  VCU,GW
 SG_ IPS_DCDCCurrHvAct : 41|9@0+ (0.1,0) [0|51.1] "A"  GW,VCU,MCU_B
 SG_ IPS_DCDCCurrLvAct : 63|9@0+ (1,0) [0|511] "A"  GW,VCU
 SG_ IPS_SBCSafetyOutputSt : 75|1@0+ (1,0) [0|1] ""  VCU,GW
 SG_ IPS_DCDCVoltHvAct : 70|10@0+ (1,0) [0|1023] "V"  VCU,GW,MCU_B
 SG_ IPS_OBCDiagErrCode : 151|8@0+ (1,0) [0|255] ""  VCU,GW
 SG_ IPS_OBCCC_St : 159|3@0+ (1,0) [0|7] ""  GW,VCU,MCU_B,BMS
 SG_ IPS_OBCCC_Res : 156|10@0+ (10,0) [0|10230] "Ohm"  VCU,GW
 SG_ IPS_OBCDschDisable : 162|1@0+ (1,0) [0|1] ""  VCU,GW
 SG_ IPS_OBCModeSt : 175|4@0+ (1,0) [0|15] ""  VCU,GW
 SG_ IPS_DchgOverload : 161|1@0+ (1,0) [0|1] ""  VCU,GW
 SG_ IPS_OBCHvDcCurrAct : 171|11@0+ (0.1,-102.4) [-102.4|102.3] "A"  VCU,GW,BMS
 SG_ IPS_OBCHvDcVoltAct : 176|10@0+ (1,0) [0|1023] "V"  VCU,GW,BMS
 SG_ IPS_OBCCC_Cap : 198|3@0+ (1,0) [0|7] ""  GW,VCU,BMS
 SG_ IPS_OBCCpS2St : 200|1@0+ (1,0) [0|1] ""  VCU,GW
 SG_ IPS_OBCCpFreqSt : 160|1@0+ (1,0) [0|1] ""  VCU,GW
 SG_ IPS_OBCCPSt : 195|1@0+ (1,0) [0|1] ""  VCU,GW
 SG_ IPS_OBCCp_DutyCycle : 194|10@0+ (0.1,0) [0|100] ""  VCU,GW
 SG_ IPS_OBCCPVolt : 215|8@0+ (0.1,0) [0|12.7] "V"  VCU,GW
 SG_ IPS_OBCUacActL1 : 223|9@0+ (1,0) [0|511] "V"  VCU,GW
 SG_ IPS_OBCUacActL2 : 295|9@0+ (1,0) [0|511] "V"  VCU,GW
 SG_ IPS_OBCUacActL3 : 238|9@0+ (1,0) [0|511] "V"  VCU,GW
 SG_ IPS_OBCCurrActL1 : 254|9@0+ (0.1,0) [0|51.1] "A"  VCU,GW
 SG_ IPS_OBCCurrActL2 : 261|9@0+ (0.1,0) [0|51.1] "A"  VCU,GW
 SG_ IPS_OBCCurrActL3 : 268|9@0+ (0.1,0) [0|51.1] "A"  VCU,GW
 SG_ IPS_smo_ObcModeSt : 275|7@0+ (1,0) [0|127] ""  VCU
 SG_ IPS_smd_DcdcModeSt : 300|6@0+ (1,0) [0|63] ""  VCU
 SG_ IPS_WakeOriginSignal2 : 326|16@0+ (1,0) [0|65535] ""  VCU
 SG_ IPS_WakeOriginSignal1 : 310|16@0+ (1,0) [0|65535] ""  VCU
 SG_ IPS_OBCV2CSt : 242|3@0+ (1,0) [0|7] ""  VCU,GW
 SG_ IPS_V2CMicSwitSt : 245|3@0+ (1,0) [0|7] ""  VCU,GW
 SG_ Reserved1 : 447|8@0+ (1,0) [0|255] ""  VCU
 SG_ IPS_1_FreshnessValue : 455|16@0+ (1,0) [0|255] ""  Tester
 SG_ IPS_1_MAC_Check : 471|48@0+ (1,0) [0|255] ""  Tester

BO_ 2683306032 IPS_2: 64 MCU
 SG_ IPS_2_CRC : 7|16@0+ (1,0) [0|65535] ""  VCU,GW,MCU_B
 SG_ IPS_2_Counter : 23|8@0+ (1,0) [0|255] ""  VCU,GW,MCU_B
 SG_ IPS_SwVersion : 31|16@0+ (1,0) [0|65535] ""  VCU
 SG_ IPS_HwSt : 47|4@0+ (1,0) [0|15] ""  VCU,GW
 SG_ IPS_RemoteDiagCode : 43|2@0+ (1,0) [0|3] ""  GW,VCU
 SG_ IPS_TEL_DCDCFaultLampInd : 41|1@0+ (1,0) [0|1] ""  GW,VCU
 SG_ IPS_TEL_DCDCTempOvrErr : 40|1@0+ (1,0) [0|1] ""  GW,VCU
 SG_ IPS_TEL_DCDCModeSt : 55|2@0+ (1,0) [0|3] ""  GW,VCU
 SG_ IPS_TempAct : 63|8@0+ (1,-40) [-40|215] "degC"  VCU,GW,MCU_B
 SG_ IPS_DCDCFaultLampInd : 53|1@0+ (1,0) [0|1] ""  GW,VCU
 SG_ IPS_DCDCKL30Volt : 68|9@0+ (0.1,0) [0|51.1] ""  VCU
 SG_ IPS_DCDCFlowReq : 52|4@0+ (1,0) [0|15] "L/min"  VCU,GW
 SG_ IPS_HVDCHVilSt : 71|2@0+ (1,0) [0|3] ""  VCU,GW
 SG_ IPS_OBCChgPwrMax : 135|10@0+ (0.05,0) [0|51.15] "kW"  GW,VCU,BMS
 SG_ IPS_OBCFlowReq : 141|4@0+ (1,0) [0|15] "L/min"  VCU,GW
 SG_ IPS_OBCFaultLampInd : 137|1@0+ (1,0) [0|1] ""  GW,VCU
 SG_ IPS_ACHvilSt : 151|2@0+ (1,0) [0|3] ""  VCU,GW
 SG_ IPS_DCDCState1 : 87|8@0+ (1,0) [0|255] ""  VCU
 SG_ IPS_DCDCState2 : 95|8@0+ (1,0) [0|255] ""  VCU
 SG_ IPS_DCDCState3 : 103|8@0+ (1,0) [0|255] ""  VCU
 SG_ IPS_DCDCState4 : 111|8@0+ (1,0) [0|255] ""  VCU
 SG_ IPS_DCDCState5 : 119|8@0+ (1,0) [0|255] ""  VCU
 SG_ IPS_DCDCState6 : 127|8@0+ (1,0) [0|255] ""  VCU
 SG_ IPS_OBCState1 : 159|8@0+ (1,0) [0|255] ""  VCU
 SG_ IPS_OBCState2 : 167|8@0+ (1,0) [0|255] ""  VCU
 SG_ IPS_OBCState3 : 175|8@0+ (1,0) [0|255] ""  VCU
 SG_ IPS_OBCState4 : 183|8@0+ (1,0) [0|255] ""  VCU
 SG_ IPS_OBCState5 : 191|8@0+ (1,0) [0|255] ""  VCU
 SG_ IPS_ChgCurResp : 149|5@0+ (1,0) [0|31] ""  VCU,GW,BMS,IDC
 SG_ IPS_ChgCurRespAvail : 144|1@0+ (1,0) [0|1] ""  VCU,IDC
 SG_ IPS_DCDCFaultLampIndOperationFla : 199|1@0+ (1,0) [0|1] ""  VCU
 SG_ IPS_DCDCFaultLampIndFlag : 198|1@0+ (1,0) [0|1] ""  VCU
 SG_ IPS_OBCFaultLampIndOperationFlag : 197|1@0+ (1,0) [0|1] ""  VCU
 SG_ IPS_OBCState6 : 279|8@0+ (1,0) [0|255] ""  VCU
 SG_ IPS_OBCState7 : 207|8@0+ (1,0) [0|255] ""  VCU
 SG_ IPS_OBCState8 : 215|8@0+ (1,0) [0|255] ""  VCU
 SG_ IPS_OBCState9 : 223|8@0+ (1,0) [0|255] ""  VCU
 SG_ IPS_OBCState10 : 231|8@0+ (1,0) [0|255] ""  VCU
 SG_ IPS_OBCState11 : 239|8@0+ (1,0) [0|255] ""  VCU
 SG_ IPS_DCDCState7 : 247|8@0+ (1,0) [0|255] ""  VCU
 SG_ IPS_DCDCState8 : 255|8@0+ (1,0) [0|255] ""  VCU
 SG_ IPS_DCDCState9 : 263|8@0+ (1,0) [0|255] ""  VCU
 SG_ IPS_DCDCState10 : 271|8@0+ (1,0) [0|255] ""  VCU
 SG_ IPS_OBCAcIso_Res : 285|6@0+ (20,0) [0|1260] "Kohm"  VCU
 SG_ IPS_OBCState12 : 319|8@0+ (1,0) [0|255] ""  VCU
 SG_ IPS_OBCState13 : 327|8@0+ (1,0) [0|255] ""  VCU
 SG_ IPS_OBCState14 : 335|8@0+ (1,0) [0|255] ""  VCU
 SG_ IPS_DCDCState11 : 343|8@0+ (1,0) [0|255] ""  VCU
 SG_ IPS_DCDCState12 : 351|8@0+ (1,0) [0|255] ""  VCU
 SG_ IPS_DCDCState13 : 359|8@0+ (1,0) [0|255] ""  VCU
 SG_ IPS_OBCV2CRlySt : 299|3@0+ (1,0) [0|7] ""  VCU
 SG_ IPS_OBCV2CCurr : 292|9@0+ (0.1,0) [0|51.1] "A"  VCU,GW
 SG_ IPS_OBCV2LRlySt : 296|3@0+ (1,0) [0|7] ""  VCU,GW
 SG_ IPS_2_FreshnessValue : 455|16@0+ (1,0) [0|255] ""  Tester
 SG_ IPS_2_MAC_Check : 471|48@0+ (1,0) [0|255] ""  Tester

BO_ 1037 VCU_PDCU_0x40D: 8 VCU
 SG_ VCUFlNodeId : 7|8@0+ (1,0) [0|127] ""  IPU,BMS,MCU_F,LBMS,GW,MCU
 SG_ VCUFlPni : 14|1@0+ (1,0) [0|1] ""  IPU,BMS,MCU_F,LBMS,GW,MCU
 SG_ VCUFlAwb : 12|1@0+ (1,0) [0|1] ""  IPU,BMS,MCU_F,LBMS,GW,MCU
 SG_ VCUFlRmr : 8|1@0+ (1,0) [0|1] ""  IPU,BMS,MCU_F,LBMS,GW,MCU
 SG_ VCUFlWus : 47|8@0+ (1,0) [0|255] ""  IPU,BMS,MCU_F,LBMS,GW,MCU
 SG_ VCUFlNmSts : 48|1@0+ (1,0) [0|1] ""  IPU,BMS,MCU_F,LBMS,GW,MCU

BO_ 297 EPS_0x129: 32 GW
 SG_ EpsFltSts : 20|2@0+ (1,0) [0|3] ""  MCU
 SG_ EPSSteerWhlBackStsFb : 33|2@0+ (1,0) [0|3] ""  MCU

BO_ 390 PBM_0x186: 32 GW
 SG_ AbsFltLamp : 20|1@0+ (1,0) [0|1] ""  MCU
 SG_ EspTcsVdcFltLamp : 21|1@0+ (1,0) [0|1] ""  MCU
 SG_ EspTcsVdcActvLamp : 22|1@0+ (1,0) [0|1] ""  MCU
 SG_ HhcAvl : 39|1@0+ (1,0) [0|1] ""  MCU
 SG_ VdcActv : 42|1@0+ (1,0) [0|1] ""  MCU
 SG_ TcsActv : 43|1@0+ (1,0) [0|1] ""  MCU
 SG_ AbsActv : 44|1@0+ (1,0) [0|1] ""  MCU
 SG_ PBM_Fault_IND : 60|2@0+ (1,0) [0|2] ""  MCU
 SG_ EztAvl : 80|1@0+ (1,0) [0|1] ""  MCU
 SG_ EztStb : 81|1@0+ (1,0) [0|1] ""  MCU
 SG_ EztActv : 95|1@0+ (1,0) [0|1] ""  MCU

BO_ 405 AVAP_ADC_ICC_0x195: 48 GW
 SG_ ApaSts : 147|4@0+ (1,0) [0|15] ""  MCU
 SG_ RpaSts : 151|4@0+ (1,0) [0|15] ""  MCU

BO_ 422 PBM_0x1A6: 32 GW
 SG_ PbmBrakePedalApplid : 41|1@0+ (1,0) [0|1] ""  MCU
 SG_ PbmBrakePedalApplidVld : 43|2@0+ (1,0) [0|3] ""  MCU
 SG_ WhlBrkTotTorq : 55|16@0+ (2,0) [0|8188] "Nm"  MCU
 SG_ VALID_BOOSTER_CYLINDER_PRESSURE : 87|2@0+ (1,0) [0|3] ""  MCU
 SG_ PBM_MASTER_CYLINDER_PRESSURE : 83|12@0+ (0.1,0) [0|255] "bar"  MCU
 SG_ BOOSTER_CYLINDER_PRESSURE : 103|12@0+ (0.1,0) [0|255] "bar"  MCU
 SG_ PBM_OUTPUT_ROD_DRIVER : 107|12@0+ (0.015625,-5) [-5|47] "mm"  MCU
 SG_ PBM_OUTPUT_ROD_DRIVER_STATE : 121|2@0+ (1,0) [0|3] ""  MCU

BO_ 444 EPS_0x1BC: 16 GW
 SG_ EPS_CrtSts : 68|1@0+ (1,0) [0|1] ""  MCU

BO_ 523 PBM_0x20B: 16 GW
 SG_ NBS_20B_CheckSum : 7|8@0+ (1,0) [0|255] ""  MCU
 SG_ NBS_20B_AliveCounter : 11|4@0+ (1,0) [0|14] ""  MCU
 SG_ NBS_EBR_AVL_FLG : 19|2@0+ (1,0) [0|3] ""  MCU
 SG_ NBS_EBR_ACT_FLG : 21|2@0+ (1,0) [0|3] ""  MCU
 SG_ PBMLfcState : 23|2@0+ (1,0) [0|3] ""  MCU
 SG_ NBS_EBR_Tor_ACT : 31|16@0+ (1,0) [0|65535] "Nm"  MCU
 SG_ PBMRemDriEnaFlg : 46|1@0+ (1,0) [0|1] ""  MCU

BO_ 605 HDCU_VCU_0x25D: 8 VCU
 SG_ McuBrakeTorMax : 23|16@0+ (0.1,-400) [-400|400] "Nm"  MCU
 SG_ McuDriveTorMax : 39|16@0+ (0.1,-400) [-400|400] "Nm"  MCU

BO_ 607 VCU_PDCU_0x25F: 16 VCU
 SG_ McuAntislipEnaCmd : 42|1@0+ (1,0) [0|1] ""  MCU
 SG_ McuDriStyleFactor : 62|7@0+ (0.01,0) [0|1] ""  MCU
 SG_ McuLpEnterAntislipEnaCmd : 63|1@0+ (1,0) [0|1] ""  MCU
 SG_ MotorType : 108|3@0+ (1,0) [0|7] ""  MCU

BO_ 1532 PBM_0x5FC: 32 GW
 SG_ WCBStcsVariant : 39|16@0+ (1,0) [0|65535] ""  MCU

BO_ 892 BDCU_0x37C: 8 GW
 SG_ BDCU_KeyPressSts : 18|1@0+ (1,0) [0|1] ""  MCU

BO_ 915 AVAP_ADC_ICC_0x393: 64 GW
 SG_ ApaPasRdrDstFrntLe : 135|8@0+ (2,0) [0|500] "cm"  MCU
 SG_ ApaPasRdrDstFrntLeMin : 143|8@0+ (2,0) [0|500] "cm"  MCU
 SG_ ApaPasRdrDstFrntRiMin : 151|8@0+ (2,0) [0|500] "cm"  MCU
 SG_ ApaPasRdrDstFrntRi : 159|8@0+ (2,0) [0|500] "cm"  MCU
 SG_ ApaPasRdrDstReLe : 167|8@0+ (2,0) [0|500] "cm"  MCU
 SG_ ApaPasRdrDstReLeMin : 175|8@0+ (2,0) [0|500] "cm"  MCU
 SG_ ApaPasRdrDstrReRiMin : 183|8@0+ (2,0) [0|500] "cm"  MCU
 SG_ ApaPasRdrDstrReRi : 191|8@0+ (2,0) [0|500] "cm"  MCU
 SG_ ApaPasRdrDstrLeFrnt : 199|8@0+ (2,0) [0|500] "cm"  MCU
 SG_ ApaPasRdrDstrLeRe : 207|8@0+ (2,0) [0|500] "cm"  MCU
 SG_ ApaPasRdrDstrRiFrnt : 215|8@0+ (2,0) [0|500] "cm"  MCU
 SG_ ApaPasRdrDstRiRe : 223|8@0+ (2,0) [0|500] "cm"  MCU

BO_ 916 PAS_ADC_ICC_0x394: 8 GW
 SG_ PasSysSts : 3|4@0+ (1,0) [0|15] ""  MCU

BO_ 504 PKC_0x1F8: 8 GW
 SG_ PKC_RemDrvgReq : 55|4@0+ (1,0) [0|15] ""  MCU

BO_ 653 MPC_ADC_0x28D: 48 GW
 SG_ FRS_ObjFront1_HeadingAg : 5|9@0+ (1,-180) [-180|179] "deg"  MCU
 SG_ FRS_ObjFront2_HeadingAg : 12|9@0+ (1,-180) [-180|179] "deg"  MCU
 SG_ MPCObj1VX : 19|12@0+ (0.0625,-128) [-128|127.9375] "m/s"  MCU
 SG_ FRS_ObjFront3_HeadingAg : 39|9@0+ (1,-180) [-180|179] "deg"  MCU
 SG_ FRS_ObjFront4_HeadingAg : 46|9@0+ (1,-180) [-180|179] "deg"  MCU
 SG_ FRS_ObjFront5_HeadingAg : 53|9@0+ (1,-180) [-180|179] "deg"  MCU
 SG_ FRS_ObjFront1_Dx : 79|8@0+ (1,0) [0|255] "m"  MCU
 SG_ FRS_ObjFront1_Dy : 87|8@0+ (0.1,-12.7) [-12.7|12.8] "m"  MCU
 SG_ FRS_ObjFront1_Type : 90|3@0+ (1,0) [0|7] ""  MCU
 SG_ FRS_ObjFront1_Color : 93|3@0+ (1,0) [0|7] ""  MCU
 SG_ FRS_ObjFront2_Dx : 103|8@0+ (1,0) [0|255] "m"  MCU
 SG_ FRS_ObjFront2_Dy : 111|8@0+ (0.1,-12.7) [-12.7|12.8] "m"  MCU
 SG_ FRS_ObjFront2_Type : 114|3@0+ (1,0) [0|7] ""  MCU
 SG_ FRS_ObjFront2_Color : 117|3@0+ (1,0) [0|7] ""  MCU
 SG_ MPCObj2VX : 131|12@0+ (0.0625,-128) [-128|127.9375] "m/s"  MCU
 SG_ FRS_ObjFront3_Dx : 151|8@0+ (1,0) [0|255] "m"  MCU
 SG_ FRS_ObjFront3_Dy : 159|8@0+ (0.1,-12.7) [-12.7|12.8] "m"  MCU
 SG_ FRS_ObjFront3_Type : 162|3@0+ (1,0) [0|7] ""  MCU
 SG_ FRS_ObjFront3_Color : 165|3@0+ (1,0) [0|7] ""  MCU
 SG_ FRS_ObjFront6_HeadingAg : 172|9@0+ (1,-180) [-180|179] "deg"  MCU
 SG_ MPCObj3VX : 179|12@0+ (0.0625,-128) [-128|127.9375] "m/s"  MCU
 SG_ FRS_ObjFront4_Dx : 199|8@0+ (1,0) [0|255] "m"  MCU
 SG_ FRS_ObjFront4_Dy : 207|8@0+ (0.1,-12.7) [-12.7|12.8] "m"  MCU
 SG_ FRS_ObjFront4_Type : 210|3@0+ (1,0) [0|7] ""  MCU
 SG_ FRS_ObjFront4_Color : 213|3@0+ (1,0) [0|7] ""  MCU
 SG_ MPCObj4VX : 227|12@0+ (0.0625,-128) [-128|127.9375] "m/s"  MCU
 SG_ FRS_ObjFront5_Dx : 247|8@0+ (1,0) [0|255] "m"  MCU
 SG_ FRS_ObjFront5_Dy : 255|8@0+ (0.1,-12.7) [-12.7|12.8] "m"  MCU
 SG_ FRS_ObjFront5_Type : 258|3@0+ (1,0) [0|7] ""  MCU
 SG_ FRS_ObjFront5_Color : 261|3@0+ (1,0) [0|7] ""  MCU
 SG_ MPCOb5VX : 275|12@0+ (0.0625,-128) [-128|127.9375] "m/s"  MCU
 SG_ FRS_ObjFront6_Dx : 295|8@0+ (1,0) [0|255] "m"  MCU
 SG_ FRS_ObjFront6_Dy : 303|8@0+ (0.1,-12.7) [-12.7|12.8] "m"  MCU
 SG_ FRS_ObjFront6_Type : 306|3@0+ (1,0) [0|7] ""  MCU
 SG_ FRS_ObjFront6_Color : 309|3@0+ (1,0) [0|7] ""  MCU
 SG_ MPCAccFobjDrvAwayInfo : 310|1@0+ (1,0) [0|1] ""  MCU
 SG_ MPCObj6VX : 331|12@0+ (0.0625,-128) [-128|127.9375] "m/s"  MCU

BO_ 336 EPS_0x150: 16 GW
 SG_ SteerWhlAg : 23|16@0+ (0.1,-780) [-780|780] "°"  MCU
 SG_ SteerWhlAgVld : 34|2@0+ (1,0) [0|3] ""  MCU
 SG_ EPS_SteerWhlRotSpdDir : 77|2@0+ (1,0) [0|3] ""  MCU

BO_ 293 PBM_0x125: 64 GW
 SG_ TcsRednEngTqFlg_F : 24|1@0+ (1,0) [0|1] ""  MCU
 SG_ TcsRednEngTqFlg_R : 25|1@0+ (1,0) [0|1] ""  MCU
 SG_ EV_F_RegenTarTrqFlg : 26|1@0+ (1,0) [0|1] ""  MCU
 SG_ EV_R_RegenTarTrqFlg : 27|1@0+ (1,0) [0|1] ""  MCU
 SG_ DtcIncEngTqFlg_F : 40|1@0+ (1,0) [0|1] ""  MCU
 SG_ DtcIncEngTqFlg_R : 43|1@0+ (1,0) [0|1] ""  MCU
 SG_ EV_F_RegenTarTrq : 87|16@0+ (1,-32768) [-32768|32767] "N.m"  MCU
 SG_ EV_F_RegenTarTrqValid : 105|2@0+ (1,0) [0|3] ""  MCU
 SG_ EV_R_RegenTarTrq : 103|14@0+ (1,-6000) [-6000|6000] "N.m"  MCU
 SG_ VlcApaIncTqReq : 119|14@0+ (1,-6000) [-6000|6000] "N.m"  MCU
 SG_ EspCtrl3Chks : 135|8@0+ (1,0) [0|255] ""  MCU
 SG_ EspCtrl3Cntr : 139|4@0+ (1,0) [0|14] ""  MCU
 SG_ FrtMotMaxTarSpd : 150|15@0+ (1,0) [0|32767] "rpm"  MCU
 SG_ FrtdTCSCtrlModeReq : 162|3@0+ (1,0) [0|7] ""  MCU
 SG_ GearShiftInhb : 175|1@0+ (1,0) [0|1] ""  MCU
 SG_ WhTorqueEst_FL : 174|15@0+ (1,0) [0|32767] "N.m"  MCU
 SG_ N_FrntAxleDTCTrqReq : 247|14@0+ (1,-6000) [-6000|10000] "Nm"  MCU
 SG_ N_ReAxleFastReductionTrqReq : 279|14@0+ (1,-6000) [-6000|10000] "Nm"  MCU
 SG_ N_ReAxleSlowReductionTrqReq : 295|14@0+ (1,-6000) [-6000|10000] "Nm"  MCU
 SG_ N_ReAxleDTCTrqReq : 311|14@0+ (1,-6000) [-6000|10000] "Nm"  MCU
 SG_ Esp125FV : 327|16@0+ (1,0) [0|65535] ""  MCU
 SG_ Esp125MAC : 343|48@0+ (1,0) [0|281474976710655] ""  MCU
 SG_ WhTorqueEst_FR : 406|15@0+ (1,0) [0|32767] "N.m"  MCU
 SG_ WhTorqueEst_LR : 422|15@0+ (1,0) [0|32767] "N.m"  MCU

CM_ SG_ 384 EOP_1_CRC "E2E Profile 5 CRC,Refer to AUTOASR E2E Profile 5";
CM_ SG_ 384 EOP_1_Counter "E2E Profile 5 Counter,Refer to AUTOASR E2E Profile 5";
CM_ SG_ 384 EOP_SpdAct "Actual speed of oil pump";
CM_ SG_ 384 EOP_IdcAct "oil pump DC current";
CM_ SG_ 384 EOP_IphAct "oil pump phase current";
CM_ SG_ 384 EOP_UdcAct "actual voltage of oil pump";
CM_ SG_ 384 EOP_Status "EOP Status";
CM_ SG_ 384 EOP_duty "duty cycle of oil pump";
CM_ SG_ 384 EOP_ErrLevel "to inform DCU that the error level of the EOP";
CM_ BO_ 2015 "矩阵中诊断报文的DLC仅用于适配DBC文件的生成，ECU实际开发采用的DLC长度应满足UDS技术要求。矩阵中诊断报文的DLC仅用于适配DBC文件的生成，ECU实际开发采用的DLC长度应满足UDS技术要求。";
CM_ SG_ 2015 Fun_Diag_Request "Diagnostic function request";
CM_ SG_ 1790 NIDU_UDS_Diag_Response "NIDU diagnostic response For UDS";
CM_ SG_ 1662 NIDU_UDS_Diag_Request "NIDU diagnostic request For UDS";
CM_ SG_ 2028 NIDU_OBD_Diag_Response "NIDU diagnostic response For OBD";
CM_ SG_ 2020 NIDU_OBD_Diag_Request "NIDU diagnostic request For OBD";
CM_ SG_ 2683306023 DCU_1_CRC "E2E Profile 5 CRC,Refer to AUTOASR E2E Profile 5";
CM_ SG_ 2683306023 DCU_1_Counter "E2E Profile 5 Counter,Refer to AUTOASR E2E Profile 5";
CM_ SG_ 2683306023 DCU_RotSpdAct "actual rotation speed of drvie motor";
CM_ SG_ 2683306023 DCU_IdcAct "actual current at HV of DCU";
CM_ SG_ 2683306023 DCU_UdcAct "actual voltage at HV of DCU";
CM_ SG_ 2683306023 DCU_CCUEOPPowerSup "DCU request CCU give EOP power supply";
CM_ SG_ 2683306023 DCU_ModeSt "mode status of drive motor";
CM_ SG_ 2683306023 DCU_TorqMax "maximum positive Torque allowed (motor)";
CM_ SG_ 2683306023 DCU_TorqMin "maximum negative torque allowed (generator)";
CM_ SG_ 2683306023 DCU_SelfTorqMax "Actual value of maximum positive Torque without Idc max limit";
CM_ SG_ 2683306023 DCU_SelfTorqMin "Actual value maximum negative torque? without Idc mini limit";
CM_ SG_ 2683306023 DCU_DstActive "Surge Damping state active";
CM_ SG_ 2683306023 DCU_GateDrvSt "state of gate driver";
CM_ SG_ 2683306023 DCU_DiagErrCode "DCU diagnostics error code";
CM_ SG_ 2683306023 DCU_DMCInternalTorqSet "DMC torque targetControl output of DMC used as torque target for further processing in the power electronicsThis signal must be implemented in 4Quadrant coordinates";
CM_ SG_ 2683306023 DCU_DMCInternalInit "Init check for DMC SW part during DMC initialize phase set to 1 once DMC init successfully then set to 0";
CM_ SG_ 2683306023 DCU_DMCInternalInputQF "Qualify for all input signals form MCU to DMCIf any input signal invalid during calculation phase (Including all possilbility like signals invalid value  message error MCU status) once InputQF=false  If valid then InputQF=true";
CM_ SG_ 2683306023 DCU_DMCOperationStToBCS "Indicates the status of the DMC.";
CM_ SG_ 2683306023 DCU_DMCoutputTorqToBCS "DMC torque target.Control output of DMC used as torque target for further processing in the ESP/IPB for lamp usage and target torqueadjustment during dynamic mode.This signal must be implemented in 1Quadrant coordinates";
CM_ SG_ 2683306023 DCU_DMCVariantInfoToBCS "DMC VariantInfo including variant info, mainly used for handshake check";
CM_ SG_ 2683306023 DCU_DMCVersionInfoToBCS "DMC VersionInfo including variant info, mainly used for handshake check";
CM_ SG_ 2683306023 DCU_TorqAct "actual torque of drive motor";
CM_ SG_ 2683306023 DCU_EOP_SpdSet "requestable oil pump speed";
CM_ SG_ 2683306024 DCU_2_CRC "E2E Profile 5 CRC,Refer to AUTOASR E2E Profile 5";
CM_ SG_ 2683306024 DCU_2_Counter "E2E Profile 5 Counter,Refer to AUTOASR E2E Profile 5";
CM_ SG_ 2683306024 DCU_BoostChgPwrMax "Available Boost charging power about DCU";
CM_ SG_ 2683306024 DCU_AHF_ActPwr "DCU send calculated AHF powerto VCU";
CM_ SG_ 2683306024 DCU_RemoteDiagCode "The flag that ECU need to be remote diagnosed";
CM_ SG_ 2683306024 DCU_TypeSt "DCU type state for configuration";
CM_ SG_ 2683306024 DCU_bDiagReq "Diag request for e-machine Inverter Calibration";
CM_ SG_ 2683306024 DCU_bReadyHV "HV voltage operational";
CM_ SG_ 2683306024 DCU_OffsetCalInd "indication of óffset calibration successfull flag";
CM_ SG_ 2683306024 DCU_DisChgPwrMax "Available discharging power about DCU";
CM_ SG_ 2683306024 DCU_InvtTemp "Current temperature of inverter";
CM_ SG_ 2683306024 DCU_VoltageT30 "Current UT30 Voltage at inverter";
CM_ SG_ 2683306024 DCU_SysTempOvrInd "Indicator of overheat warning lamp, which is lighten if temperature of drive motor system is too high.";
CM_ SG_ 2683306024 DCU_RotTemp "Current temperature of rotor";
CM_ SG_ 2683306024 DCU_CooltReq "Requested DCU coolant massflow";
CM_ SG_ 2683306024 DCU_FaultLampInd "Warning indicator to lighten fault lamp (Malfunction Indication Lamp,MIL)";
CM_ SG_ 2683306024 DCU_StatTemp "Current temperature of stator";
CM_ SG_ 2683306024 DCU_TempCoolant "temperature of inverter cooling water";
CM_ SG_ 2683306024 DCU_ErrNoticeOperationFlag "Operation flag for DCU error notice";
CM_ SG_ 2683306024 DCU_ErrNotice "DCU error notice";
CM_ SG_ 2683306024 DCU_Err2NoticeFlag "Lever2 Error for DCU Popup?flag";
CM_ SG_ 2683306024 DCU_TEL_MotorNumOrder "The order number of motors in the vehicle (this value cannot be larger than the total number)";
CM_ SG_ 2683306024 DCU_TEL_ECUTempOvrErr "The  temperature  of ECU is too high";
CM_ SG_ 2683306024 DCU_TEL_MotTempOvrErr "The  temperature  of Motor is too high";
CM_ SG_ 2683306024 DCU_TEL_MotorNumTotal "The total number of motors in the vehicle";
CM_ SG_ 2683306024 DCU_TEL_InvtTemp "Current temperature of inverter";
CM_ SG_ 2683306024 DCU_TEL_RotSpdAct "actual rotation speed of drvie motor";
CM_ SG_ 2683306024 DCU_TEL_TorqAct "actual torque of drive motor";
CM_ SG_ 2683306024 DCU_TEL_StatTemp "Current temperature of stator";
CM_ SG_ 2683306024 DCU_TEL_ModeSt "Mode state for TEL ONLY";
CM_ SG_ 2683306024 DCU_TEL_CurrActAmend "actual current at HV of DCU（by amend）";
CM_ SG_ 2683306024 DCU_TEL_UdcAct "actual voltage at HV of DCU";
CM_ SG_ 2683306024 DCU_TEL_BattCurr "actual current of battery(BMS_BattCurr)";
CM_ SG_ 2683306024 DCU_BoostCurrMax "Available Boost max current  about DCU";
CM_ SG_ 2683306024 DCU_BuckCurrMax "Available Buck max current  about DCU";
CM_ SG_ 2683306024 DCU_K2RlyAdhmode "K2 Relay adhesion detection mode";
CM_ SG_ 2683306024 DCU_IgnitionSt "State of DCU Ignition";
CM_ SG_ 2683306024 DCU_TEL_OverSpdErr "The speed of motor is too high";
CM_ SG_ 2683306024 DCU_TEL_OverCurrErr "The current of motor is too high";
CM_ SG_ 408 BMC_1_CRC "E2E Profile 5 CRC,Refer to AUTOASR E2E Profile 5";
CM_ SG_ 408 BMC_1_Counter "E2E Profile 5 Counter,Refer to AUTOASR E2E Profile 5";
CM_ SG_ 408 BMC_BattVolt "actual voltage of battery pack (inside of main relay)";
CM_ SG_ 408 BMC_DCUBattSt "working state of battery system for DCU";
CM_ SG_ 408 BMC_PwrDwnReq "Emergency power-off warning. when the HV battery needs an emergency power-off, this signal is used to notify each HV node. The received node should reduce their power? to 0? as soon as possible.";
CM_ SG_ 408 BMC_BoostChgModeReq "Mode request of the boost Charge";
CM_ SG_ 2683306025 IPS_1_CRC "E2E Profile 5 CRC,Refer to AUTOASR E2E Profile 5";
CM_ SG_ 2683306025 IPS_1_Counter "E2E Profile 5 Counter,Refer to AUTOASR E2E Profile 5";
CM_ SG_ 2683306025 IPS_DCDCDiagErrCode "DCDC diagnostics error code";
CM_ SG_ 2683306025 IPS_DCDCModeSt "mode status of DCDC";
CM_ SG_ 2683306025 IPS_KL15State "IPS or DCDC Enable state";
CM_ SG_ 2683306025 IPS_DCDCVoltLvAct "actual LV voltage at DCDC";
CM_ SG_ 2683306025 IPS_DCDCCurrHvAct "HV Current? of DCDC";
CM_ SG_ 2683306025 IPS_DCDCCurrLvAct "LV Current? of DCDC";
CM_ SG_ 2683306025 IPS_SBCSafetyOutputSt "SBC Safety Output State";
CM_ SG_ 2683306025 IPS_DCDCVoltHvAct "actual HV voltage at DCDC";
CM_ SG_ 2683306025 IPS_OBCDiagErrCode "OBC diagnostics error code";
CM_ SG_ 2683306025 IPS_OBCCC_St "Status of slow charging cable connection (CC) including type of connected cable (charging/V2V, or V2L)";
CM_ SG_ 2683306025 IPS_OBCCC_Res "CC Resistance value in Ohm";
CM_ SG_ 2683306025 IPS_OBCDschDisable "Status of control pilot signal (CP) for discharging";
CM_ SG_ 2683306025 IPS_OBCModeSt "OBC mode state";
CM_ SG_ 2683306025 IPS_DchgOverload "Discharge Overload";
CM_ SG_ 2683306025 IPS_OBCHvDcCurrAct "OBC HVDC actual current (Positive current+：Charging mode output current from IPS to HVBAT, Negative current-: DisCharging mode input current from HVBAT)";
CM_ SG_ 2683306025 IPS_OBCHvDcVoltAct "OBC HVDC voltage";
CM_ SG_ 2683306025 IPS_OBCCC_Cap "AC charging capability of the charging cable detected by OBC";
CM_ SG_ 2683306025 IPS_OBCCpS2St "S2 swtich state";
CM_ SG_ 2683306025 IPS_OBCCpFreqSt "CP frequency is in the GB range";
CM_ SG_ 2683306025 IPS_OBCCPSt "Status of control pilot signal (CP) for charging";
CM_ SG_ 2683306025 IPS_OBCCp_DutyCycle "CP Duty";
CM_ SG_ 2683306025 IPS_OBCCPVolt "CP high level";
CM_ SG_ 2683306025 IPS_OBCUacActL1 "L1 phase voltage";
CM_ SG_ 2683306025 IPS_OBCUacActL2 "L2 phase voltage";
CM_ SG_ 2683306025 IPS_OBCUacActL3 "L3 phase voltage";
CM_ SG_ 2683306025 IPS_OBCCurrActL1 "L1 phase current";
CM_ SG_ 2683306025 IPS_OBCCurrActL2 "L2 phase current";
CM_ SG_ 2683306025 IPS_OBCCurrActL3 "L3 phase current";
CM_ SG_ 2683306025 IPS_smo_ObcModeSt "OBC basic StateMation";
CM_ SG_ 2683306025 IPS_smd_DcdcModeSt "DCDC basic StateMation";
CM_ SG_ 2683306025 IPS_WakeOriginSignal2 "Wake up OriginSignal2";
CM_ SG_ 2683306025 IPS_WakeOriginSignal1 "Wake up OriginSignal1";
CM_ SG_ 2683306025 IPS_OBCV2CSt "OBC V2C mode status";
CM_ SG_ 2683306025 IPS_V2CMicSwitSt "Micro switch state of V2C";
CM_ SG_ 2683306025 Reserved1 "Reserved";
CM_ SG_ 2683306032 IPS_2_CRC "E2E Profile 5 CRC,Refer to AUTOASR E2E Profile 5";
CM_ SG_ 2683306032 IPS_2_Counter "E2E Profile 5 Counter,Refer to AUTOASR E2E Profile 5";
CM_ SG_ 2683306032 IPS_SwVersion "software version of IPS OR DCDC, according to GAC Definition (see Diagnostic Tables)";
CM_ SG_ 2683306032 IPS_HwSt "tell it is that IPS or DCDC(because they are same ID)";
CM_ SG_ 2683306032 IPS_RemoteDiagCode "The flag that ECU need to be remote diagnosed";
CM_ SG_ 2683306032 IPS_TEL_DCDCFaultLampInd "Warning indicator to lighten fault lamp (Malfunction Indication Lamp, MIL), FOR TEL";
CM_ SG_ 2683306032 IPS_TEL_DCDCTempOvrErr "over temperature, DCDC not able to work, FOR TEL";
CM_ SG_ 2683306032 IPS_TEL_DCDCModeSt "mode status of DCDC for TEL";
CM_ SG_ 2683306032 IPS_TempAct " internal temperature of IPS or DCDC( if it's DCDC)";
CM_ SG_ 2683306032 IPS_DCDCKL30Volt "IPS or DCDC LV power supply voltage";
CM_ SG_ 2683306032 IPS_DCDCFlowReq "The DCDC required coolant flow speed? (L/min)";
CM_ SG_ 2683306032 IPS_HVDCHVilSt "IPS send DC side HVIL status measued by itself";
CM_ SG_ 2683306032 IPS_OBCChgPwrMax "Available OBC charging power depending on provided current and voltage from charging station, limitations from cable OBC efficiency and OBC derating.";
CM_ SG_ 2683306032 IPS_OBCFlowReq "The OBC required coolant flow speed? (L/min)";
CM_ SG_ 2683306032 IPS_ACHvilSt "IPS send AC side HVIL status measued by itself";
CM_ SG_ 2683306032 IPS_DCDCState1 "DCDC state information 1";
CM_ SG_ 2683306032 IPS_DCDCState2 "DCDC state information 2";
CM_ SG_ 2683306032 IPS_DCDCState3 "DCDC state information 3";
CM_ SG_ 2683306032 IPS_DCDCState4 "DCDC state information 4";
CM_ SG_ 2683306032 IPS_DCDCState5 "DCDC state information 5";
CM_ SG_ 2683306032 IPS_DCDCState6 "DCDC state information 6";
CM_ SG_ 2683306032 IPS_OBCState1 "OBC state information 1";
CM_ SG_ 2683306032 IPS_OBCState2 "OBC state information 2";
CM_ SG_ 2683306032 IPS_OBCState3 "OBC state information 3";
CM_ SG_ 2683306032 IPS_OBCState4 "OBC state information 4";
CM_ SG_ 2683306032 IPS_OBCState5 "OBC state information 5";
CM_ SG_ 2683306032 IPS_ChgCurResp "Charge current response of IPS for display";
CM_ SG_ 2683306032 IPS_ChgCurRespAvail "To indicate if Charge current of HV IPS is available";
CM_ SG_ 2683306032 IPS_DCDCFaultLampIndOperationFla "Operation flag for IPS_DCDCFaultLampInd";
CM_ SG_ 2683306032 IPS_DCDCFaultLampIndFlag "Popup?flag?for??DCDC?error?notice";
CM_ SG_ 2683306032 IPS_OBCFaultLampIndOperationFlag "Operation flag for  IPS_OBCFaultLampInd";
CM_ SG_ 2683306032 IPS_OBCState6 "OBC state information 6";
CM_ SG_ 2683306032 IPS_OBCState7 "OBC state information 7";
CM_ SG_ 2683306032 IPS_OBCState8 "OBC state information 8";
CM_ SG_ 2683306032 IPS_OBCState9 "OBC state information 9";
CM_ SG_ 2683306032 IPS_OBCState10 "OBC state information 10";
CM_ SG_ 2683306032 IPS_OBCState11 "OBC state information 11";
CM_ SG_ 2683306032 IPS_DCDCState7 "DCDC state information 7";
CM_ SG_ 2683306032 IPS_DCDCState8 "DCDC state information 8";
CM_ SG_ 2683306032 IPS_DCDCState9 "DCDC state information 9";
CM_ SG_ 2683306032 IPS_DCDCState10 "DCDC state information 10";
CM_ SG_ 2683306032 IPS_OBCAcIso_Res "Ac Line Iso Resistance Value";
CM_ SG_ 2683306032 IPS_OBCState12 "OBC state information 12";
CM_ SG_ 2683306032 IPS_OBCState13 "OBC state information 13";
CM_ SG_ 2683306032 IPS_OBCState14 "OBC state information 14";
CM_ SG_ 2683306032 IPS_DCDCState11 "DCDC state information 11";
CM_ SG_ 2683306032 IPS_DCDCState12 "DCDC state information 12";
CM_ SG_ 2683306032 IPS_DCDCState13 "DCDC state information 13";
CM_ SG_ 2683306032 IPS_OBCV2CRlySt "Actual state of OBC V2C relay";
CM_ SG_ 2683306032 IPS_OBCV2CCurr "OBC V2C  current";
CM_ SG_ 2683306032 IPS_OBCV2LRlySt "Actual state of OBC V2L relay";
CM_ BO_ 1037 "NMsignal";
CM_ SG_ 1037 VCUFlNodeId "Node Id=0D";
CM_ SG_ 1037 VCUFlPni "Partial Network Information Bit";
CM_ SG_ 1037 VCUFlAwb "Active Wakeup Bit";
CM_ SG_ 1037 VCUFlRmr "Repeat Message Request Bit";
CM_ SG_ 1037 VCUFlWus "Wake Up Source of VCU";
CM_ SG_ 1037 VCUFlNmSts "VCU Nework Management State";
CM_ SG_ 297 EpsFltSts "EPS故障灯状态";
CM_ SG_ 297 EPSSteerWhlBackStsFb "回正状态反馈";
CM_ BO_ 390 "功能状态位（仪表点灯）相关";
CM_ SG_ 390 AbsFltLamp "ABS故障灯";
CM_ SG_ 390 EspTcsVdcFltLamp "ESP/TCS/VDC故障灯";
CM_ SG_ 390 EspTcsVdcActvLamp "TCS/VDC工作指示灯";
CM_ SG_ 390 HhcAvl "HHC功能可用状态";
CM_ SG_ 390 VdcActv "VDC功能激活状态";
CM_ SG_ 390 TcsActv "TCS功能激活状态";
CM_ SG_ 390 AbsActv "ABS功能激活状态";
CM_ SG_ 390 PBM_Fault_IND "制动系统故障显示（PBM故障状态）";
CM_ SG_ 390 EztAvl "EZT功能可用状态";
CM_ SG_ 390 EztStb "EZT功能待机状态（低速智能辅助转向功能）";
CM_ SG_ 390 EztActv "EZT功能激活状态";
CM_ BO_ 405 "CBUS和IBUS都发送，GW只收CBUS";
CM_ SG_ 405 ApaSts "APA功能状态";
CM_ SG_ 405 RpaSts "RPA功能状态";
CM_ BO_ 422 "增压缸等+踏板（自身传感器）相关";
CM_ SG_ 422 PbmBrakePedalApplid "制动踏板是否踩下状态位";
CM_ SG_ 422 PbmBrakePedalApplidVld "制动踏板是否踩下状态位有效性";
CM_ SG_ 422 WhlBrkTotTorq "轮边制动力矩和";
CM_ SG_ 422 VALID_BOOSTER_CYLINDER_PRESSURE "PBM增压缸压力有效性";
CM_ SG_ 422 PBM_MASTER_CYLINDER_PRESSURE "PBM主缸压力";
CM_ SG_ 422 BOOSTER_CYLINDER_PRESSURE "PBM增压缸压力";
CM_ SG_ 422 PBM_OUTPUT_ROD_DRIVER "驾驶员推杆行程";
CM_ SG_ 422 PBM_OUTPUT_ROD_DRIVER_STATE "驾驶员推杆行程状态位";
CM_ SG_ 444 EPS_CrtSts "EPS 当前状态";
CM_ SG_ 523 NBS_20B_CheckSum "PBM报文校验和（Profile：1ADataID 0x005F）";
CM_ SG_ 523 NBS_20B_AliveCounter "PBM报文计数器";
CM_ SG_ 523 NBS_EBR_AVL_FLG "针对NBS电制动补偿系统是否可用标志位";
CM_ SG_ 523 NBS_EBR_ACT_FLG "NBS外部制动激活标志位";
CM_ SG_ 523 PBMLfcState "PBM_LFC功能状态";
CM_ SG_ 523 NBS_EBR_Tor_ACT "NBS实际执行的外部制动力";
CM_ SG_ 523 PBMRemDriEnaFlg "PBM遥控驾驶使能标志位";
CM_ SG_ 605 McuBrakeTorMax "整车允许驱动电机最大发电转矩";
CM_ SG_ 605 McuDriveTorMax "整车允许驱动电机最大电动转矩";
CM_ SG_ 607 McuAntislipEnaCmd "防溜车功能使能命令";
CM_ SG_ 607 McuDriStyleFactor "驾驶风格因子";
CM_ SG_ 607 McuLpEnterAntislipEnaCmd "低转速阈值进入防溜坡使能命令";
CM_ SG_ 607 MotorType "电机类型";
CM_ BO_ 1532 "版本号&故障码信息相关";
CM_ SG_ 1532 WCBStcsVariant "TCS软件版本号";
CM_ SG_ 892 BDCU_KeyPressSts "智能钥匙按键状态";
CM_ BO_ 915 "CBUS和IBUS都发送，GW只收CBUS";
CM_ SG_ 915 ApaPasRdrDstFrntLe "前方左边长距离雷达探测障碍物距离值";
CM_ SG_ 915 ApaPasRdrDstFrntLeMin "前方左中长距离雷达探测障碍物距离值";
CM_ SG_ 915 ApaPasRdrDstFrntRiMin "前方右中长距离雷达探测障碍物距离值";
CM_ SG_ 915 ApaPasRdrDstFrntRi "前方右边长距离雷达探测障碍物距离值";
CM_ SG_ 915 ApaPasRdrDstReLe "后方左边长距离雷达探测障碍物距离值";
CM_ SG_ 915 ApaPasRdrDstReLeMin "后方左中长距离雷达探测障碍物距离值";
CM_ SG_ 915 ApaPasRdrDstrReRiMin "后方右中长距离雷达探测障碍物距离值";
CM_ SG_ 915 ApaPasRdrDstrReRi "后方右边长距离雷达探测障碍物距离值";
CM_ SG_ 915 ApaPasRdrDstrLeFrnt "左侧前方长距离雷达探测障碍物距离值";
CM_ SG_ 915 ApaPasRdrDstrLeRe "左侧后方长距离雷达探测障碍物距离值";
CM_ SG_ 915 ApaPasRdrDstrRiFrnt "右侧前方长距离雷达探测障碍物距离值";
CM_ SG_ 915 ApaPasRdrDstRiRe "右侧后方长距离雷达探测障碍物距离值";
CM_ BO_ 916 "高配AVAP在ADASBUS发，GW转发给BDCU，BDCU转发至BodyBUS1；低配PAS发，BDCU接收转发给GW，GW再路由至其他网段。
舱泊一体配置由ICC（ACANFD）发送
C66TB-MO5中，CBUS和IBUS都发送，GW只收CBUS";
CM_ SG_ 916 PasSysSts "泊车雷达系统状态";
CM_ SG_ 504 PKC_RemDrvgReq "遥控驾驶请求";
CM_ BO_ 653 "CBUS和IBUS都发送，GW只收CBUS";
CM_ SG_ 653 FRS_ObjFront1_HeadingAg "目标1航向角";
CM_ SG_ 653 FRS_ObjFront2_HeadingAg "目标2航向角";
CM_ SG_ 653 MPCObj1VX "X向相对速度";
CM_ SG_ 653 FRS_ObjFront3_HeadingAg "目标3航向角";
CM_ SG_ 653 FRS_ObjFront4_HeadingAg "目标4航向角";
CM_ SG_ 653 FRS_ObjFront5_HeadingAg "目标5航向角";
CM_ SG_ 653 FRS_ObjFront1_Dx "目标1 Dx";
CM_ SG_ 653 FRS_ObjFront1_Dy "目标1 Dy";
CM_ SG_ 653 FRS_ObjFront1_Type "目标1类型";
CM_ SG_ 653 FRS_ObjFront1_Color "目标1颜色";
CM_ SG_ 653 FRS_ObjFront2_Dx "目标2 Dx";
CM_ SG_ 653 FRS_ObjFront2_Dy "目标2 Dy";
CM_ SG_ 653 FRS_ObjFront2_Type "目标2类型";
CM_ SG_ 653 FRS_ObjFront2_Color "目标2颜色";
CM_ SG_ 653 MPCObj2VX "X向相对速度";
CM_ SG_ 653 FRS_ObjFront3_Dx "目标3 Dx";
CM_ SG_ 653 FRS_ObjFront3_Dy "目标3 Dy";
CM_ SG_ 653 FRS_ObjFront3_Type "目标3类型";
CM_ SG_ 653 FRS_ObjFront3_Color "目标3颜色";
CM_ SG_ 653 FRS_ObjFront6_HeadingAg "目标6航向角";
CM_ SG_ 653 MPCObj3VX "X向相对速度";
CM_ SG_ 653 FRS_ObjFront4_Dx "目标4 Dx";
CM_ SG_ 653 FRS_ObjFront4_Dy "目标4 Dy";
CM_ SG_ 653 FRS_ObjFront4_Type "目标4类型";
CM_ SG_ 653 FRS_ObjFront4_Color "目标4颜色";
CM_ SG_ 653 MPCObj4VX "X向相对速度";
CM_ SG_ 653 FRS_ObjFront5_Dx "目标5 Dx";
CM_ SG_ 653 FRS_ObjFront5_Dy "目标5 Dy";
CM_ SG_ 653 FRS_ObjFront5_Type "目标5类型";
CM_ SG_ 653 FRS_ObjFront5_Color "目标5颜色";
CM_ SG_ 653 MPCOb5VX "X向相对速度";
CM_ SG_ 653 FRS_ObjFront6_Dx "目标6 Dx";
CM_ SG_ 653 FRS_ObjFront6_Dy "目标6 Dy";
CM_ SG_ 653 FRS_ObjFront6_Type "目标6类型";
CM_ SG_ 653 FRS_ObjFront6_Color "目标6颜色";
CM_ SG_ 653 MPCAccFobjDrvAwayInfo "前车驶离提示";
CM_ SG_ 653 MPCObj6VX "X向相对速度";
CM_ SG_ 336 SteerWhlAg "方向盘转角信号(逆时针为正，顺时针为负)";
CM_ SG_ 336 SteerWhlAgVld "方向盘转角信号有效位";
CM_ SG_ 336 EPS_SteerWhlRotSpdDir "方向盘转速方向（左+、右-）";
CM_ BO_ 293 "基础功能及智驾扭矩相关";
CM_ SG_ 293 TcsRednEngTqFlg_F "前动力总成TCS发送的降扭请求标志位（轮端）。";
CM_ SG_ 293 TcsRednEngTqFlg_R "后动力总成TCS发送的降扭请求标志位（轮端）。";
CM_ SG_ 293 EV_F_RegenTarTrqFlg "前动力总成目标制动再生扭矩请求标志位";
CM_ SG_ 293 EV_R_RegenTarTrqFlg "后动力总成目标制动再生扭矩请求标志位";
CM_ SG_ 293 DtcIncEngTqFlg_F "前动力总成增扭矩请求标志位，DTC是否介入（轮端）。";
CM_ SG_ 293 DtcIncEngTqFlg_R "后动力总成增扭矩请求标志位，DTC是否介入（轮端）。";
CM_ SG_ 293 EV_F_RegenTarTrq "前动力总成目标制动再生扭矩";
CM_ SG_ 293 EV_F_RegenTarTrqValid "前动力总成目标制动再生扭矩请求有效";
CM_ SG_ 293 EV_R_RegenTarTrq "后动力总成目标制动再生扭矩";
CM_ SG_ 293 VlcApaIncTqReq "VLC APA增扭矩请求值（轮端）";
CM_ SG_ 293 EspCtrl3Chks "PBM报文校验和(Profile:1A;DataID:0x000C)";
CM_ SG_ 293 EspCtrl3Cntr "PBM报文计数器";
CM_ SG_ 293 FrtMotMaxTarSpd "前轴目标控制转速";
CM_ SG_ 293 FrtdTCSCtrlModeReq "前轴dTCS控制模式";
CM_ SG_ 293 GearShiftInhb "在TCS作用时某些工况会发禁止换挡。";
CM_ SG_ 293 WhTorqueEst_FL "TCS左前轮估算制动力矩";
CM_ SG_ 293 N_FrntAxleDTCTrqReq "前轴升扭矩请求（折算到轮端）";
CM_ SG_ 293 N_ReAxleFastReductionTrqReq "后轴快扭降扭干预（折算到轮端）";
CM_ SG_ 293 N_ReAxleSlowReductionTrqReq "后轴慢扭降扭干预（折算到轮端）";
CM_ SG_ 293 N_ReAxleDTCTrqReq "后轴升扭矩请求（折算到轮端）";
CM_ SG_ 293 Esp125FV "SecOC，预留";
CM_ SG_ 293 Esp125MAC "SecOC，预留";
CM_ SG_ 293 WhTorqueEst_FR "TCS右前轮估算制动力矩";
CM_ SG_ 293 WhTorqueEst_LR "TCS左后轮估算制动力矩";
BA_DEF_ BO_  "GenMsgSendType" ENUM  "cyclic","Event","IfActive","POE","PA","FixedPeriodic","Event","EnabledPeriodic","NotUsed","NotUsed","EventPeriodic","NotUsed","NotUsed","NoMsgSendType";
BA_DEF_ SG_  "EventCommandSignal" ENUM  "No","Yes";
BA_DEF_ SG_  "GatewayedSignals" ENUM  "No","Yes";
BA_DEF_ SG_  "GenSigInactiveValue" HEX 0 0;
BA_DEF_ SG_  "GenSigInvalidValue" HEX 0 0;
BA_DEF_ SG_  "GenSigSendType" ENUM  "Trigger","Passive","Cyclic","OnWrite","OnWriteWithRepetition","OnChange","OnChangeWithRepetition","IfActive","IfActiveWithRepetition","NoSigSendType";
BA_DEF_ SG_  "GenSigTimeoutValue" HEX 0 0;
BA_DEF_ SG_  "Remark" STRING ;
BA_DEF_ BO_  "NmMessage" ENUM  "No","Yes";
BA_DEF_ BO_  "DiagState" ENUM  "No","Yes";
BA_DEF_ BO_  "DiagResponse" ENUM  "No","Yes";
BA_DEF_ BO_  "GenMsgCycleTime" INT 0 0;
BA_DEF_ SG_  "GenSigStartValue" INT 0 0;
BA_DEF_ BO_  "GenMsgCycleTimeFast" INT 0 0;
BA_DEF_ BO_  "GenMsgNrOfRepetition" INT 0 0;
BA_DEF_  "DBName" STRING ;
BA_DEF_ BO_  "CANFD_BRS" ENUM  "0","1";
BA_DEF_ BO_  "VFrameFormat" ENUM  "StandardCAN","ExtendedCAN","reserved","reserved","reserved","reserved","reserved","reserved","reserved","reserved","reserved","reserved","reserved","reserved","StandardCAN_FD","ExtendedCAN_FD";
BA_DEF_  "BusBaudateData" INT 0 10000;
BA_DEF_  "BusBaudateOther" INT 0 10000;
BA_DEF_ BO_  "GenMsgILSupport" ENUM  "No","Yes";
BA_DEF_  "NmBaseAddress" HEX 1024 1087;
BA_DEF_  "BusType" STRING ;
BA_DEF_ SG_  "sigDespEng" STRING ;
BA_DEF_ SG_  "sigSecLevel" STRING ;
BA_DEF_ SG_  "sigConfig" STRING ;
BA_DEF_ SG_  "sigExplanation" STRING ;
BA_DEF_ SG_  "SystemSignalLongSymbol" STRING ;
BA_DEF_DEF_  "GenMsgSendType" "cyclic";
BA_DEF_DEF_  "EventCommandSignal" "";
BA_DEF_DEF_  "GatewayedSignals" "";
BA_DEF_DEF_  "GenSigInactiveValue" 0;
BA_DEF_DEF_  "GenSigInvalidValue" 0;
BA_DEF_DEF_  "GenSigSendType" "";
BA_DEF_DEF_  "GenSigTimeoutValue" 0;
BA_DEF_DEF_  "Remark" "";
BA_DEF_DEF_  "NmMessage" "No";
BA_DEF_DEF_  "DiagState" "No";
BA_DEF_DEF_  "DiagResponse" "No";
BA_DEF_DEF_  "GenMsgCycleTime" 0;
BA_DEF_DEF_  "GenSigStartValue" 0;
BA_DEF_DEF_  "GenMsgCycleTimeFast" 0;
BA_DEF_DEF_  "GenMsgNrOfRepetition" 0;
BA_DEF_DEF_  "DBName" "";
BA_DEF_DEF_  "CANFD_BRS" "1";
BA_DEF_DEF_  "VFrameFormat" "StandardCAN";
BA_DEF_DEF_  "BusBaudateData" 2;
BA_DEF_DEF_  "BusBaudateOther" 500;
BA_DEF_DEF_  "GenMsgILSupport" "Yes";
BA_DEF_DEF_  "NmBaseAddress" 1024;
BA_DEF_DEF_  "BusType" "CAN FD";
BA_DEF_DEF_  "sigDespEng" "";
BA_DEF_DEF_  "sigSecLevel" "QM";
BA_DEF_DEF_  "sigConfig" "";
BA_DEF_DEF_  "sigExplanation" "";
BA_DEF_DEF_  "SystemSignalLongSymbol" "";
BA_ "DBName" "NIDUCCU_CANFD2";
BA_ "GenMsgCycleTime" BO_ 384 100;
BA_ "VFrameFormat" BO_ 384 14;
BA_ "GenMsgSendType" BO_ 2015 1;
BA_ "DiagResponse" BO_ 2015 1;
BA_ "DiagState" BO_ 2015 1;
BA_ "VFrameFormat" BO_ 2015 14;
BA_ "GenMsgSendType" BO_ 1790 1;
BA_ "VFrameFormat" BO_ 1790 14;
BA_ "GenMsgSendType" BO_ 1662 1;
BA_ "VFrameFormat" BO_ 1662 14;
BA_ "GenMsgSendType" BO_ 2028 1;
BA_ "VFrameFormat" BO_ 2028 14;
BA_ "GenMsgSendType" BO_ 2020 1;
BA_ "VFrameFormat" BO_ 2020 14;
BA_ "GenMsgCycleTime" BO_ 2683306023 10;
BA_ "VFrameFormat" BO_ 2683306023 15;
BA_ "GenMsgCycleTime" BO_ 2683306024 100;
BA_ "VFrameFormat" BO_ 2683306024 15;
BA_ "GenMsgCycleTime" BO_ 408 10;
BA_ "VFrameFormat" BO_ 408 14;
BA_ "GenMsgCycleTime" BO_ 2683306021 1000;
BA_ "VFrameFormat" BO_ 2683306021 15;
BA_ "GenMsgCycleTime" BO_ 2683306010 100;
BA_ "VFrameFormat" BO_ 2683306010 15;
BA_ "GenMsgCycleTime" BO_ 2683305995 10;
BA_ "VFrameFormat" BO_ 2683305995 15;
BA_ "GenMsgCycleTime" BO_ 2683305999 10;
BA_ "VFrameFormat" BO_ 2683305999 15;
BA_ "GenMsgCycleTime" BO_ 2683306017 100;
BA_ "VFrameFormat" BO_ 2683306017 15;
BA_ "GenMsgSendType" BO_ 2634022913 1;
BA_ "VFrameFormat" BO_ 2634022913 1;
BA_ "GenMsgSendType" BO_ 2634022912 1;
BA_ "VFrameFormat" BO_ 2634022912 1;
BA_ "GenMsgCycleTime" BO_ 2683306022 1000;
BA_ "GenMsgCycleTimeFast" BO_ 2683306022 40;
BA_ "GenMsgSendType" BO_ 2683306022 4;
BA_ "VFrameFormat" BO_ 2683306022 15;
BA_ "GenMsgCycleTime" BO_ 2683306093 200;
BA_ "VFrameFormat" BO_ 2683306093 15;
BA_ "GenMsgCycleTime" BO_ 2683306000 200;
BA_ "VFrameFormat" BO_ 2683306000 15;
BA_ "GenMsgCycleTime" BO_ 2683306012 200;
BA_ "VFrameFormat" BO_ 2683306012 15;
BA_ "GenMsgCycleTime" BO_ 2683306025 20;
BA_ "VFrameFormat" BO_ 2683306025 15;
BA_ "GenMsgCycleTime" BO_ 2683306032 100;
BA_ "VFrameFormat" BO_ 2683306032 15;
BA_ "CANFD_BRS" BO_ 1037 0;
BA_ "GenMsgCycleTime" BO_ 1037 500;
BA_ "NmMessage" BO_ 1037 1;
BA_ "GenMsgCycleTime" BO_ 297 10;
BA_ "VFrameFormat" BO_ 297 14;
BA_ "GenMsgCycleTime" BO_ 390 20;
BA_ "VFrameFormat" BO_ 390 14;
BA_ "GenMsgCycleTime" BO_ 405 20;
BA_ "VFrameFormat" BO_ 405 14;
BA_ "GenMsgCycleTime" BO_ 422 20;
BA_ "VFrameFormat" BO_ 422 14;
BA_ "GenMsgCycleTime" BO_ 444 20;
BA_ "VFrameFormat" BO_ 444 14;
BA_ "GenMsgCycleTime" BO_ 523 20;
BA_ "VFrameFormat" BO_ 523 14;
BA_ "GenMsgCycleTime" BO_ 605 100;
BA_ "VFrameFormat" BO_ 605 14;
BA_ "GenMsgCycleTime" BO_ 607 100;
BA_ "VFrameFormat" BO_ 607 14;
BA_ "GenMsgCycleTime" BO_ 1532 1000;
BA_ "VFrameFormat" BO_ 1532 14;
BA_ "GenMsgCycleTime" BO_ 892 100;
BA_ "VFrameFormat" BO_ 892 14;
BA_ "GenMsgCycleTime" BO_ 915 100;
BA_ "VFrameFormat" BO_ 915 14;
BA_ "GenMsgCycleTime" BO_ 916 100;
BA_ "VFrameFormat" BO_ 916 14;
BA_ "GenMsgCycleTime" BO_ 504 20;
BA_ "VFrameFormat" BO_ 504 14;
BA_ "GenMsgCycleTime" BO_ 653 50;
BA_ "VFrameFormat" BO_ 653 14;
BA_ "GenMsgCycleTime" BO_ 336 10;
BA_ "VFrameFormat" BO_ 336 14;
BA_ "GenMsgCycleTime" BO_ 293 10;
BA_ "VFrameFormat" BO_ 293 14;
BA_ "EventCommandSignal" SG_ 384 EOP_1_CRC 0;
BA_ "GatewayedSignals" SG_ 384 EOP_1_CRC 0;
BA_ "GenSigSendType" SG_ 384 EOP_1_CRC 1;
BA_ "EventCommandSignal" SG_ 384 EOP_1_Counter 0;
BA_ "GatewayedSignals" SG_ 384 EOP_1_Counter 0;
BA_ "GenSigSendType" SG_ 384 EOP_1_Counter 1;
BA_ "EventCommandSignal" SG_ 384 EOP_SpdAct 0;
BA_ "GatewayedSignals" SG_ 384 EOP_SpdAct 0;
BA_ "GenSigSendType" SG_ 384 EOP_SpdAct 1;
BA_ "EventCommandSignal" SG_ 384 EOP_IdcAct 0;
BA_ "GatewayedSignals" SG_ 384 EOP_IdcAct 0;
BA_ "GenSigSendType" SG_ 384 EOP_IdcAct 1;
BA_ "EventCommandSignal" SG_ 384 EOP_IphAct 0;
BA_ "GatewayedSignals" SG_ 384 EOP_IphAct 0;
BA_ "GenSigSendType" SG_ 384 EOP_IphAct 1;
BA_ "EventCommandSignal" SG_ 384 EOP_UdcAct 0;
BA_ "GatewayedSignals" SG_ 384 EOP_UdcAct 0;
BA_ "GenSigSendType" SG_ 384 EOP_UdcAct 1;
BA_ "EventCommandSignal" SG_ 384 EOP_Status 0;
BA_ "GatewayedSignals" SG_ 384 EOP_Status 0;
BA_ "GenSigSendType" SG_ 384 EOP_Status 1;
BA_ "EventCommandSignal" SG_ 384 EOP_duty 0;
BA_ "GatewayedSignals" SG_ 384 EOP_duty 0;
BA_ "GenSigSendType" SG_ 384 EOP_duty 1;
BA_ "EventCommandSignal" SG_ 384 EOP_ErrLevel 0;
BA_ "GatewayedSignals" SG_ 384 EOP_ErrLevel 0;
BA_ "GenSigSendType" SG_ 384 EOP_ErrLevel 1;
BA_ "EventCommandSignal" SG_ 1790 NIDU_UDS_Diag_Response 1;
BA_ "GatewayedSignals" SG_ 1790 NIDU_UDS_Diag_Response 0;
BA_ "GenSigSendType" SG_ 1790 NIDU_UDS_Diag_Response 0;
BA_ "EventCommandSignal" SG_ 1662 NIDU_UDS_Diag_Request 1;
BA_ "GatewayedSignals" SG_ 1662 NIDU_UDS_Diag_Request 0;
BA_ "GenSigSendType" SG_ 1662 NIDU_UDS_Diag_Request 0;
BA_ "EventCommandSignal" SG_ 2028 NIDU_OBD_Diag_Response 1;
BA_ "GatewayedSignals" SG_ 2028 NIDU_OBD_Diag_Response 0;
BA_ "GenSigSendType" SG_ 2028 NIDU_OBD_Diag_Response 0;
BA_ "EventCommandSignal" SG_ 2020 NIDU_OBD_Diag_Request 1;
BA_ "GatewayedSignals" SG_ 2020 NIDU_OBD_Diag_Request 0;
BA_ "GenSigSendType" SG_ 2020 NIDU_OBD_Diag_Request 0;
BA_ "GenSigSendType" SG_ 2683306023 DCU_1_CRC 1;
BA_ "GatewayedSignals" SG_ 2683306023 DCU_1_CRC 0;
BA_ "EventCommandSignal" SG_ 2683306023 DCU_1_CRC 0;
BA_ "GenSigSendType" SG_ 2683306023 DCU_1_Counter 1;
BA_ "GatewayedSignals" SG_ 2683306023 DCU_1_Counter 0;
BA_ "EventCommandSignal" SG_ 2683306023 DCU_1_Counter 0;
BA_ "GenSigStartValue" SG_ 2683306023 DCU_RotSpdAct 32767;
BA_ "GenSigSendType" SG_ 2683306023 DCU_RotSpdAct 1;
BA_ "GenSigInvalidValue" SG_ 2683306023 DCU_RotSpdAct 65535;
BA_ "GatewayedSignals" SG_ 2683306023 DCU_RotSpdAct 0;
BA_ "EventCommandSignal" SG_ 2683306023 DCU_RotSpdAct 0;
BA_ "GenSigStartValue" SG_ 2683306023 DCU_IdcAct 1023;
BA_ "GenSigSendType" SG_ 2683306023 DCU_IdcAct 1;
BA_ "GatewayedSignals" SG_ 2683306023 DCU_IdcAct 0;
BA_ "EventCommandSignal" SG_ 2683306023 DCU_IdcAct 0;
BA_ "GenSigSendType" SG_ 2683306023 DCU_UdcAct 1;
BA_ "GatewayedSignals" SG_ 2683306023 DCU_UdcAct 0;
BA_ "EventCommandSignal" SG_ 2683306023 DCU_UdcAct 0;
BA_ "GenSigSendType" SG_ 2683306023 DCU_ErrorLv3St 1;
BA_ "GatewayedSignals" SG_ 2683306023 DCU_ErrorLv3St 0;
BA_ "EventCommandSignal" SG_ 2683306023 DCU_ErrorLv3St 0;
BA_ "GenSigStartValue" SG_ 2683306023 DCU_CCUEOPPowerSup 1;
BA_ "GenSigSendType" SG_ 2683306023 DCU_CCUEOPPowerSup 1;
BA_ "GatewayedSignals" SG_ 2683306023 DCU_CCUEOPPowerSup 0;
BA_ "EventCommandSignal" SG_ 2683306023 DCU_CCUEOPPowerSup 0;
BA_ "GenSigStartValue" SG_ 2683306023 DCU_ModeSt 1;
BA_ "GenSigSendType" SG_ 2683306023 DCU_ModeSt 1;
BA_ "GatewayedSignals" SG_ 2683306023 DCU_ModeSt 0;
BA_ "EventCommandSignal" SG_ 2683306023 DCU_ModeSt 0;
BA_ "GenSigSendType" SG_ 2683306023 DCU_TorqMax 1;
BA_ "GatewayedSignals" SG_ 2683306023 DCU_TorqMax 0;
BA_ "EventCommandSignal" SG_ 2683306023 DCU_TorqMax 0;
BA_ "GenSigStartValue" SG_ 2683306023 DCU_TorqMin 1023;
BA_ "GenSigSendType" SG_ 2683306023 DCU_TorqMin 1;
BA_ "GatewayedSignals" SG_ 2683306023 DCU_TorqMin 0;
BA_ "EventCommandSignal" SG_ 2683306023 DCU_TorqMin 0;
BA_ "GenSigSendType" SG_ 2683306023 DCU_SelfTorqMax 1;
BA_ "GatewayedSignals" SG_ 2683306023 DCU_SelfTorqMax 0;
BA_ "EventCommandSignal" SG_ 2683306023 DCU_SelfTorqMax 0;
BA_ "GenSigStartValue" SG_ 2683306023 DCU_SelfTorqMin 1023;
BA_ "GenSigSendType" SG_ 2683306023 DCU_SelfTorqMin 1;
BA_ "GatewayedSignals" SG_ 2683306023 DCU_SelfTorqMin 0;
BA_ "EventCommandSignal" SG_ 2683306023 DCU_SelfTorqMin 0;
BA_ "GenSigSendType" SG_ 2683306023 DCU_DstActive 1;
BA_ "GatewayedSignals" SG_ 2683306023 DCU_DstActive 0;
BA_ "EventCommandSignal" SG_ 2683306023 DCU_DstActive 0;
BA_ "GenSigSendType" SG_ 2683306023 DCU_GateDrvSt 1;
BA_ "GatewayedSignals" SG_ 2683306023 DCU_GateDrvSt 0;
BA_ "EventCommandSignal" SG_ 2683306023 DCU_GateDrvSt 0;
BA_ "GenSigSendType" SG_ 2683306023 DCU_DiagErrCode 1;
BA_ "GatewayedSignals" SG_ 2683306023 DCU_DiagErrCode 0;
BA_ "EventCommandSignal" SG_ 2683306023 DCU_DiagErrCode 0;
BA_ "GenSigStartValue" SG_ 2683306023 DCU_DMCInternalTorqSet 1023;
BA_ "GenSigSendType" SG_ 2683306023 DCU_DMCInternalTorqSet 1;
BA_ "GatewayedSignals" SG_ 2683306023 DCU_DMCInternalTorqSet 0;
BA_ "EventCommandSignal" SG_ 2683306023 DCU_DMCInternalTorqSet 0;
BA_ "GenSigStartValue" SG_ 2683306023 DCU_DMCInternalInit 1;
BA_ "GenSigSendType" SG_ 2683306023 DCU_DMCInternalInit 1;
BA_ "GatewayedSignals" SG_ 2683306023 DCU_DMCInternalInit 0;
BA_ "EventCommandSignal" SG_ 2683306023 DCU_DMCInternalInit 0;
BA_ "GenSigSendType" SG_ 2683306023 DCU_DMCInternalInputQF 1;
BA_ "GatewayedSignals" SG_ 2683306023 DCU_DMCInternalInputQF 0;
BA_ "EventCommandSignal" SG_ 2683306023 DCU_DMCInternalInputQF 0;
BA_ "GenSigStartValue" SG_ 2683306023 DCU_DMCOperationStToBCS 2;
BA_ "GenSigSendType" SG_ 2683306023 DCU_DMCOperationStToBCS 1;
BA_ "GatewayedSignals" SG_ 2683306023 DCU_DMCOperationStToBCS 0;
BA_ "EventCommandSignal" SG_ 2683306023 DCU_DMCOperationStToBCS 0;
BA_ "GenSigStartValue" SG_ 2683306023 DCU_DMCoutputTorqToBCS 50000;
BA_ "GenSigSendType" SG_ 2683306023 DCU_DMCoutputTorqToBCS 1;
BA_ "GatewayedSignals" SG_ 2683306023 DCU_DMCoutputTorqToBCS 0;
BA_ "EventCommandSignal" SG_ 2683306023 DCU_DMCoutputTorqToBCS 0;
BA_ "GenSigSendType" SG_ 2683306023 DCU_DMCVariantInfoToBCS 1;
BA_ "GatewayedSignals" SG_ 2683306023 DCU_DMCVariantInfoToBCS 0;
BA_ "EventCommandSignal" SG_ 2683306023 DCU_DMCVariantInfoToBCS 0;
BA_ "GenSigSendType" SG_ 2683306023 DCU_DMCVersionInfoToBCS 1;
BA_ "GatewayedSignals" SG_ 2683306023 DCU_DMCVersionInfoToBCS 0;
BA_ "EventCommandSignal" SG_ 2683306023 DCU_DMCVersionInfoToBCS 0;
BA_ "GenSigStartValue" SG_ 2683306023 DCU_TorqAct 4095;
BA_ "GenSigSendType" SG_ 2683306023 DCU_TorqAct 1;
BA_ "GatewayedSignals" SG_ 2683306023 DCU_TorqAct 0;
BA_ "EventCommandSignal" SG_ 2683306023 DCU_TorqAct 0;
BA_ "GenSigSendType" SG_ 2683306023 DCU_EOP_SpdSet 1;
BA_ "GatewayedSignals" SG_ 2683306023 DCU_EOP_SpdSet 0;
BA_ "EventCommandSignal" SG_ 2683306023 DCU_EOP_SpdSet 0;
BA_ "GenSigSendType" SG_ 2683306023 DCU_Fault2 1;
BA_ "GatewayedSignals" SG_ 2683306023 DCU_Fault2 0;
BA_ "EventCommandSignal" SG_ 2683306023 DCU_Fault2 0;
BA_ "GenSigSendType" SG_ 2683306023 DCU_Fault3 1;
BA_ "GatewayedSignals" SG_ 2683306023 DCU_Fault3 0;
BA_ "EventCommandSignal" SG_ 2683306023 DCU_Fault3 0;
BA_ "GenSigSendType" SG_ 2683306023 DCU_Fault6 1;
BA_ "GatewayedSignals" SG_ 2683306023 DCU_Fault6 0;
BA_ "EventCommandSignal" SG_ 2683306023 DCU_Fault6 0;
BA_ "GenSigStartValue" SG_ 2683306023 DCU_TrefFinal 2000;
BA_ "GenSigSendType" SG_ 2683306023 DCU_TrefFinal 1;
BA_ "GatewayedSignals" SG_ 2683306023 DCU_TrefFinal 0;
BA_ "EventCommandSignal" SG_ 2683306023 DCU_TrefFinal 0;
BA_ "GenSigSendType" SG_ 2683306023 DCU_Iq 1;
BA_ "GatewayedSignals" SG_ 2683306023 DCU_Iq 0;
BA_ "EventCommandSignal" SG_ 2683306023 DCU_Iq 0;
BA_ "GenSigSendType" SG_ 2683306023 DCU_Id 1;
BA_ "GatewayedSignals" SG_ 2683306023 DCU_Id 0;
BA_ "EventCommandSignal" SG_ 2683306023 DCU_Id 0;
BA_ "GenSigSendType" SG_ 2683306023 DCU_iCurqRef 1;
BA_ "GatewayedSignals" SG_ 2683306023 DCU_iCurqRef 0;
BA_ "EventCommandSignal" SG_ 2683306023 DCU_iCurqRef 0;
BA_ "GenSigSendType" SG_ 2683306023 DCU_iCurdRef 1;
BA_ "GatewayedSignals" SG_ 2683306023 DCU_iCurdRef 0;
BA_ "EventCommandSignal" SG_ 2683306023 DCU_iCurdRef 0;
BA_ "GenSigSendType" SG_ 2683306023 DCU_1_FreshnessValue 1;
BA_ "GatewayedSignals" SG_ 2683306023 DCU_1_FreshnessValue 0;
BA_ "EventCommandSignal" SG_ 2683306023 DCU_1_FreshnessValue 0;
BA_ "GenSigSendType" SG_ 2683306023 DCU_1_MAC_Check 1;
BA_ "GatewayedSignals" SG_ 2683306023 DCU_1_MAC_Check 0;
BA_ "EventCommandSignal" SG_ 2683306023 DCU_1_MAC_Check 0;
BA_ "GenSigSendType" SG_ 2683306024 DCU_Fault1 1;
BA_ "GatewayedSignals" SG_ 2683306024 DCU_Fault1 0;
BA_ "EventCommandSignal" SG_ 2683306024 DCU_Fault1 0;
BA_ "GenSigSendType" SG_ 2683306024 DCU_2_CRC 1;
BA_ "GatewayedSignals" SG_ 2683306024 DCU_2_CRC 0;
BA_ "EventCommandSignal" SG_ 2683306024 DCU_2_CRC 0;
BA_ "GenSigSendType" SG_ 2683306024 DCU_2_Counter 1;
BA_ "GatewayedSignals" SG_ 2683306024 DCU_2_Counter 0;
BA_ "EventCommandSignal" SG_ 2683306024 DCU_2_Counter 0;
BA_ "GenSigSendType" SG_ 2683306024 DCU_BoostChgPwrMax 1;
BA_ "GatewayedSignals" SG_ 2683306024 DCU_BoostChgPwrMax 0;
BA_ "EventCommandSignal" SG_ 2683306024 DCU_BoostChgPwrMax 0;
BA_ "GenSigSendType" SG_ 2683306024 DCU_AHF_ActPwr 1;
BA_ "GatewayedSignals" SG_ 2683306024 DCU_AHF_ActPwr 0;
BA_ "EventCommandSignal" SG_ 2683306024 DCU_AHF_ActPwr 0;
BA_ "GenSigSendType" SG_ 2683306024 DCU_RemoteDiagCode 1;
BA_ "GatewayedSignals" SG_ 2683306024 DCU_RemoteDiagCode 0;
BA_ "EventCommandSignal" SG_ 2683306024 DCU_RemoteDiagCode 0;
BA_ "GenSigSendType" SG_ 2683306024 DCU_TypeSt 1;
BA_ "GatewayedSignals" SG_ 2683306024 DCU_TypeSt 0;
BA_ "EventCommandSignal" SG_ 2683306024 DCU_TypeSt 0;
BA_ "GenSigSendType" SG_ 2683306024 DCU_bDiagReq 1;
BA_ "GatewayedSignals" SG_ 2683306024 DCU_bDiagReq 0;
BA_ "EventCommandSignal" SG_ 2683306024 DCU_bDiagReq 0;
BA_ "GenSigSendType" SG_ 2683306024 DCU_bReadyHV 1;
BA_ "GatewayedSignals" SG_ 2683306024 DCU_bReadyHV 0;
BA_ "EventCommandSignal" SG_ 2683306024 DCU_bReadyHV 0;
BA_ "GenSigSendType" SG_ 2683306024 DCU_OffsetCalInd 1;
BA_ "GatewayedSignals" SG_ 2683306024 DCU_OffsetCalInd 0;
BA_ "EventCommandSignal" SG_ 2683306024 DCU_OffsetCalInd 0;
BA_ "GenSigSendType" SG_ 2683306024 DCU_DisChgPwrMax 1;
BA_ "GatewayedSignals" SG_ 2683306024 DCU_DisChgPwrMax 0;
BA_ "EventCommandSignal" SG_ 2683306024 DCU_DisChgPwrMax 0;
BA_ "GenSigStartValue" SG_ 2683306024 DCU_InvtTemp 40;
BA_ "GenSigSendType" SG_ 2683306024 DCU_InvtTemp 1;
BA_ "GatewayedSignals" SG_ 2683306024 DCU_InvtTemp 0;
BA_ "EventCommandSignal" SG_ 2683306024 DCU_InvtTemp 0;
BA_ "GenSigSendType" SG_ 2683306024 DCU_VoltageT30 1;
BA_ "GatewayedSignals" SG_ 2683306024 DCU_VoltageT30 0;
BA_ "EventCommandSignal" SG_ 2683306024 DCU_VoltageT30 0;
BA_ "GenSigSendType" SG_ 2683306024 DCU_SysTempOvrInd 1;
BA_ "GatewayedSignals" SG_ 2683306024 DCU_SysTempOvrInd 0;
BA_ "EventCommandSignal" SG_ 2683306024 DCU_SysTempOvrInd 0;
BA_ "GenSigStartValue" SG_ 2683306024 DCU_RotTemp 40;
BA_ "GenSigSendType" SG_ 2683306024 DCU_RotTemp 1;
BA_ "GatewayedSignals" SG_ 2683306024 DCU_RotTemp 0;
BA_ "EventCommandSignal" SG_ 2683306024 DCU_RotTemp 0;
BA_ "GenSigSendType" SG_ 2683306024 DCU_CooltReq 1;
BA_ "GatewayedSignals" SG_ 2683306024 DCU_CooltReq 0;
BA_ "EventCommandSignal" SG_ 2683306024 DCU_CooltReq 0;
BA_ "GenSigSendType" SG_ 2683306024 DCU_FaultLampInd 1;
BA_ "GatewayedSignals" SG_ 2683306024 DCU_FaultLampInd 0;
BA_ "EventCommandSignal" SG_ 2683306024 DCU_FaultLampInd 0;
BA_ "GenSigStartValue" SG_ 2683306024 DCU_StatTemp 40;
BA_ "GenSigSendType" SG_ 2683306024 DCU_StatTemp 1;
BA_ "GenSigInvalidValue" SG_ 2683306024 DCU_StatTemp 511;
BA_ "GatewayedSignals" SG_ 2683306024 DCU_StatTemp 0;
BA_ "EventCommandSignal" SG_ 2683306024 DCU_StatTemp 0;
BA_ "GenSigStartValue" SG_ 2683306024 DCU_TempCoolant 40;
BA_ "GenSigSendType" SG_ 2683306024 DCU_TempCoolant 1;
BA_ "GatewayedSignals" SG_ 2683306024 DCU_TempCoolant 0;
BA_ "EventCommandSignal" SG_ 2683306024 DCU_TempCoolant 0;
BA_ "GenSigSendType" SG_ 2683306024 DCU_ErrNoticeOperationFlag 1;
BA_ "GatewayedSignals" SG_ 2683306024 DCU_ErrNoticeOperationFlag 0;
BA_ "EventCommandSignal" SG_ 2683306024 DCU_ErrNoticeOperationFlag 0;
BA_ "GenSigSendType" SG_ 2683306024 DCU_ErrNotice 1;
BA_ "GatewayedSignals" SG_ 2683306024 DCU_ErrNotice 0;
BA_ "EventCommandSignal" SG_ 2683306024 DCU_ErrNotice 0;
BA_ "GenSigSendType" SG_ 2683306024 DCU_Err2NoticeFlag 1;
BA_ "GatewayedSignals" SG_ 2683306024 DCU_Err2NoticeFlag 0;
BA_ "EventCommandSignal" SG_ 2683306024 DCU_Err2NoticeFlag 0;
BA_ "GenSigSendType" SG_ 2683306024 DCU_Fault5 1;
BA_ "GatewayedSignals" SG_ 2683306024 DCU_Fault5 0;
BA_ "EventCommandSignal" SG_ 2683306024 DCU_Fault5 0;
BA_ "GenSigSendType" SG_ 2683306024 DCU_TEL_MotorNumOrder 1;
BA_ "GatewayedSignals" SG_ 2683306024 DCU_TEL_MotorNumOrder 0;
BA_ "EventCommandSignal" SG_ 2683306024 DCU_TEL_MotorNumOrder 0;
BA_ "GenSigSendType" SG_ 2683306024 DCU_TEL_ECUTempOvrErr 1;
BA_ "GatewayedSignals" SG_ 2683306024 DCU_TEL_ECUTempOvrErr 0;
BA_ "EventCommandSignal" SG_ 2683306024 DCU_TEL_ECUTempOvrErr 0;
BA_ "GenSigSendType" SG_ 2683306024 DCU_TEL_MotTempOvrErr 1;
BA_ "GatewayedSignals" SG_ 2683306024 DCU_TEL_MotTempOvrErr 0;
BA_ "EventCommandSignal" SG_ 2683306024 DCU_TEL_MotTempOvrErr 0;
BA_ "GenSigSendType" SG_ 2683306024 DCU_TEL_MotorNumTotal 1;
BA_ "GatewayedSignals" SG_ 2683306024 DCU_TEL_MotorNumTotal 0;
BA_ "EventCommandSignal" SG_ 2683306024 DCU_TEL_MotorNumTotal 0;
BA_ "GenSigStartValue" SG_ 2683306024 DCU_TEL_InvtTemp 40;
BA_ "GenSigSendType" SG_ 2683306024 DCU_TEL_InvtTemp 1;
BA_ "GenSigInvalidValue" SG_ 2683306024 DCU_TEL_InvtTemp 255;
BA_ "GatewayedSignals" SG_ 2683306024 DCU_TEL_InvtTemp 0;
BA_ "EventCommandSignal" SG_ 2683306024 DCU_TEL_InvtTemp 0;
BA_ "GenSigSendType" SG_ 2683306024 DCU_TEL_RotSpdAct 1;
BA_ "GenSigInvalidValue" SG_ 2683306024 DCU_TEL_RotSpdAct 65535;
BA_ "GatewayedSignals" SG_ 2683306024 DCU_TEL_RotSpdAct 0;
BA_ "EventCommandSignal" SG_ 2683306024 DCU_TEL_RotSpdAct 0;
BA_ "GenSigSendType" SG_ 2683306024 DCU_TEL_TorqAct 1;
BA_ "GenSigInvalidValue" SG_ 2683306024 DCU_TEL_TorqAct 65535;
BA_ "GatewayedSignals" SG_ 2683306024 DCU_TEL_TorqAct 0;
BA_ "EventCommandSignal" SG_ 2683306024 DCU_TEL_TorqAct 0;
BA_ "GenSigStartValue" SG_ 2683306024 DCU_TEL_StatTemp 40;
BA_ "GenSigSendType" SG_ 2683306024 DCU_TEL_StatTemp 1;
BA_ "GenSigInvalidValue" SG_ 2683306024 DCU_TEL_StatTemp 255;
BA_ "GatewayedSignals" SG_ 2683306024 DCU_TEL_StatTemp 0;
BA_ "EventCommandSignal" SG_ 2683306024 DCU_TEL_StatTemp 0;
BA_ "GenSigSendType" SG_ 2683306024 DCU_TEL_ModeSt 1;
BA_ "GatewayedSignals" SG_ 2683306024 DCU_TEL_ModeSt 0;
BA_ "EventCommandSignal" SG_ 2683306024 DCU_TEL_ModeSt 0;
BA_ "GenSigSendType" SG_ 2683306024 DCU_TEL_CurrActAmend 1;
BA_ "GatewayedSignals" SG_ 2683306024 DCU_TEL_CurrActAmend 0;
BA_ "EventCommandSignal" SG_ 2683306024 DCU_TEL_CurrActAmend 0;
BA_ "GenSigSendType" SG_ 2683306024 DCU_TEL_UdcAct 1;
BA_ "GatewayedSignals" SG_ 2683306024 DCU_TEL_UdcAct 0;
BA_ "EventCommandSignal" SG_ 2683306024 DCU_TEL_UdcAct 0;
BA_ "GenSigSendType" SG_ 2683306024 DCU_TEL_BattCurr 1;
BA_ "GatewayedSignals" SG_ 2683306024 DCU_TEL_BattCurr 0;
BA_ "EventCommandSignal" SG_ 2683306024 DCU_TEL_BattCurr 0;
BA_ "GenSigSendType" SG_ 2683306024 DCU_BoostCurrMax 1;
BA_ "GatewayedSignals" SG_ 2683306024 DCU_BoostCurrMax 0;
BA_ "EventCommandSignal" SG_ 2683306024 DCU_BoostCurrMax 0;
BA_ "GenSigSendType" SG_ 2683306024 DCU_BuckCurrMax 1;
BA_ "GatewayedSignals" SG_ 2683306024 DCU_BuckCurrMax 0;
BA_ "EventCommandSignal" SG_ 2683306024 DCU_BuckCurrMax 0;
BA_ "GenSigSendType" SG_ 2683306024 DCU_K2RlyAdhmode 1;
BA_ "GatewayedSignals" SG_ 2683306024 DCU_K2RlyAdhmode 0;
BA_ "EventCommandSignal" SG_ 2683306024 DCU_K2RlyAdhmode 0;
BA_ "GenSigSendType" SG_ 2683306024 DCU_IgnitionSt 1;
BA_ "GatewayedSignals" SG_ 2683306024 DCU_IgnitionSt 0;
BA_ "EventCommandSignal" SG_ 2683306024 DCU_IgnitionSt 0;
BA_ "GenSigSendType" SG_ 2683306024 DCU_TEL_OverSpdErr 1;
BA_ "GatewayedSignals" SG_ 2683306024 DCU_TEL_OverSpdErr 0;
BA_ "EventCommandSignal" SG_ 2683306024 DCU_TEL_OverSpdErr 0;
BA_ "GenSigSendType" SG_ 2683306024 DCU_TEL_OverCurrErr 1;
BA_ "GatewayedSignals" SG_ 2683306024 DCU_TEL_OverCurrErr 0;
BA_ "EventCommandSignal" SG_ 2683306024 DCU_TEL_OverCurrErr 0;
BA_ "GenSigSendType" SG_ 2683306024 Reserved1 1;
BA_ "GatewayedSignals" SG_ 2683306024 Reserved1 0;
BA_ "EventCommandSignal" SG_ 2683306024 Reserved1 0;
BA_ "GenSigSendType" SG_ 2683306024 DCU_Fault4 1;
BA_ "GatewayedSignals" SG_ 2683306024 DCU_Fault4 0;
BA_ "EventCommandSignal" SG_ 2683306024 DCU_Fault4 0;
BA_ "EventCommandSignal" SG_ 408 BMC_1_CRC 0;
BA_ "GatewayedSignals" SG_ 408 BMC_1_CRC 0;
BA_ "GenSigSendType" SG_ 408 BMC_1_CRC 1;
BA_ "EventCommandSignal" SG_ 408 BMC_1_Counter 0;
BA_ "GatewayedSignals" SG_ 408 BMC_1_Counter 0;
BA_ "GenSigSendType" SG_ 408 BMC_1_Counter 1;
BA_ "EventCommandSignal" SG_ 408 BMC_BattVolt 0;
BA_ "GatewayedSignals" SG_ 408 BMC_BattVolt 0;
BA_ "GenSigSendType" SG_ 408 BMC_BattVolt 1;
BA_ "EventCommandSignal" SG_ 408 BMC_DCUBattSt 0;
BA_ "GatewayedSignals" SG_ 408 BMC_DCUBattSt 0;
BA_ "GenSigSendType" SG_ 408 BMC_DCUBattSt 1;
BA_ "EventCommandSignal" SG_ 408 BMC_PwrDwnReq 0;
BA_ "GatewayedSignals" SG_ 408 BMC_PwrDwnReq 0;
BA_ "GenSigSendType" SG_ 408 BMC_PwrDwnReq 1;
BA_ "EventCommandSignal" SG_ 408 BMC_BoostChgModeReq 0;
BA_ "GatewayedSignals" SG_ 408 BMC_BoostChgModeReq 0;
BA_ "GenSigSendType" SG_ 408 BMC_BoostChgModeReq 1;
BA_ "EventCommandSignal" SG_ 2683306022 DCU_stL2SignalRep 1;
BA_ "GatewayedSignals" SG_ 2683306022 DCU_stL2SignalRep 0;
BA_ "GenSigSendType" SG_ 2683306022 DCU_stL2SignalRep 0;
BA_ "EventCommandSignal" SG_ 2683306022 DCU_stL2ShutOff 1;
BA_ "GatewayedSignals" SG_ 2683306022 DCU_stL2ShutOff 0;
BA_ "GenSigSendType" SG_ 2683306022 DCU_stL2ShutOff 0;
BA_ "GenSigSendType" SG_ 2683306022 DCU_McaWT_Duty 0;
BA_ "GatewayedSignals" SG_ 2683306022 DCU_McaWT_Duty 0;
BA_ "EventCommandSignal" SG_ 2683306022 DCU_McaWT_Duty 1;
BA_ "GenSigSendType" SG_ 2683306022 DCU_McaVT_Duty 0;
BA_ "GatewayedSignals" SG_ 2683306022 DCU_McaVT_Duty 0;
BA_ "EventCommandSignal" SG_ 2683306022 DCU_McaVT_Duty 1;
BA_ "GenSigSendType" SG_ 2683306022 DCU_McaUT_Duty 0;
BA_ "GatewayedSignals" SG_ 2683306022 DCU_McaUT_Duty 0;
BA_ "EventCommandSignal" SG_ 2683306022 DCU_McaUT_Duty 1;
BA_ "GenSigSendType" SG_ 2683306022 DCU_ResInCosVal 0;
BA_ "GatewayedSignals" SG_ 2683306022 DCU_ResInCosVal 0;
BA_ "EventCommandSignal" SG_ 2683306022 DCU_ResInCosVal 1;
BA_ "EventCommandSignal" SG_ 2683306022 DCU_FbVB_Duty 1;
BA_ "GatewayedSignals" SG_ 2683306022 DCU_FbVB_Duty 0;
BA_ "GenSigSendType" SG_ 2683306022 DCU_FbVB_Duty 0;
BA_ "EventCommandSignal" SG_ 2683306022 DCU_IsLmtL2 1;
BA_ "GatewayedSignals" SG_ 2683306022 DCU_IsLmtL2 0;
BA_ "GenSigSendType" SG_ 2683306022 DCU_IsLmtL2 0;
BA_ "EventCommandSignal" SG_ 2683306022 DCU_iPhaCurWOfs 1;
BA_ "GatewayedSignals" SG_ 2683306022 DCU_iPhaCurWOfs 0;
BA_ "GenSigSendType" SG_ 2683306022 DCU_iPhaCurWOfs 0;
BA_ "EventCommandSignal" SG_ 2683306022 DCU_iPhaCurVOfs 1;
BA_ "GatewayedSignals" SG_ 2683306022 DCU_iPhaCurVOfs 0;
BA_ "GenSigSendType" SG_ 2683306022 DCU_iPhaCurVOfs 0;
BA_ "EventCommandSignal" SG_ 2683306022 DCU_iPhaCurUOfs 1;
BA_ "GatewayedSignals" SG_ 2683306022 DCU_iPhaCurUOfs 0;
BA_ "GenSigSendType" SG_ 2683306022 DCU_iPhaCurUOfs 0;
BA_ "EventCommandSignal" SG_ 2683306022 DCU_CapTempEst 0;
BA_ "GatewayedSignals" SG_ 2683306022 DCU_CapTempEst 0;
BA_ "GenSigInvalidValue" SG_ 2683306022 DCU_CapTempEst 255;
BA_ "GenSigSendType" SG_ 2683306022 DCU_CapTempEst 1;
BA_ "EventCommandSignal" SG_ 2683306022 DCU_FusaInModeSt 0;
BA_ "GatewayedSignals" SG_ 2683306022 DCU_FusaInModeSt 0;
BA_ "GenSigSendType" SG_ 2683306022 DCU_FusaInModeSt 1;
BA_ "GenSigSendType" SG_ 2683306022 DCU_uDrvLVBackupVolt 0;
BA_ "GatewayedSignals" SG_ 2683306022 DCU_uDrvLVBackupVolt 0;
BA_ "EventCommandSignal" SG_ 2683306022 DCU_uDrvLVBackupVolt 1;
BA_ "EventCommandSignal" SG_ 2683306022 DCU_Data1No 0;
BA_ "GatewayedSignals" SG_ 2683306022 DCU_Data1No 0;
BA_ "GenSigSendType" SG_ 2683306022 DCU_Data1No 1;
BA_ "GenSigStartValue" SG_ 2683306022 DCU_Data1No 1;
BA_ "EventCommandSignal" SG_ 2683306022 DCU_Hwversion 1;
BA_ "GatewayedSignals" SG_ 2683306022 DCU_Hwversion 0;
BA_ "GenSigSendType" SG_ 2683306022 DCU_Hwversion 0;
BA_ "EventCommandSignal" SG_ 2683306022 DCU_Swversion 1;
BA_ "GatewayedSignals" SG_ 2683306022 DCU_Swversion 0;
BA_ "GenSigSendType" SG_ 2683306022 DCU_Swversion 0;
BA_ "EventCommandSignal" SG_ 2683306022 DCU_SwVerExt 1;
BA_ "GatewayedSignals" SG_ 2683306022 DCU_SwVerExt 0;
BA_ "GenSigSendType" SG_ 2683306022 DCU_SwVerExt 0;
BA_ "EventCommandSignal" SG_ 2683306022 DCU_OffsetAngle 1;
BA_ "GatewayedSignals" SG_ 2683306022 DCU_OffsetAngle 0;
BA_ "GenSigSendType" SG_ 2683306022 DCU_OffsetAngle 0;
BA_ "EventCommandSignal" SG_ 2683306022 DCU_BootSV 1;
BA_ "GatewayedSignals" SG_ 2683306022 DCU_BootSV 0;
BA_ "GenSigSendType" SG_ 2683306022 DCU_BootSV 0;
BA_ "EventCommandSignal" SG_ 2683306022 DCU_BSWVersion 1;
BA_ "GatewayedSignals" SG_ 2683306022 DCU_BSWVersion 0;
BA_ "GenSigSendType" SG_ 2683306022 DCU_BSWVersion 0;
BA_ "EventCommandSignal" SG_ 2683306022 DCU_HWConfig 0;
BA_ "GatewayedSignals" SG_ 2683306022 DCU_HWConfig 0;
BA_ "GenSigSendType" SG_ 2683306022 DCU_HWConfig 1;
BA_ "EventCommandSignal" SG_ 2683306022 DCU_SWConfig 0;
BA_ "GatewayedSignals" SG_ 2683306022 DCU_SWConfig 0;
BA_ "GenSigSendType" SG_ 2683306022 DCU_SWConfig 1;
BA_ "EventCommandSignal" SG_ 2683306022 DCU_MCAConfig 0;
BA_ "GatewayedSignals" SG_ 2683306022 DCU_MCAConfig 0;
BA_ "GenSigSendType" SG_ 2683306022 DCU_MCAConfig 1;
BA_ "EventCommandSignal" SG_ 2683306022 DCU_FHConfig 0;
BA_ "GatewayedSignals" SG_ 2683306022 DCU_FHConfig 0;
BA_ "GenSigSendType" SG_ 2683306022 DCU_FHConfig 1;
BA_ "EventCommandSignal" SG_ 2683306022 DCU_InvtPhaUTemp 0;
BA_ "GatewayedSignals" SG_ 2683306022 DCU_InvtPhaUTemp 0;
BA_ "GenSigInvalidValue" SG_ 2683306022 DCU_InvtPhaUTemp 255;
BA_ "GenSigSendType" SG_ 2683306022 DCU_InvtPhaUTemp 1;
BA_ "EventCommandSignal" SG_ 2683306022 DCU_InvtPhaVTemp 0;
BA_ "GatewayedSignals" SG_ 2683306022 DCU_InvtPhaVTemp 0;
BA_ "GenSigInvalidValue" SG_ 2683306022 DCU_InvtPhaVTemp 255;
BA_ "GenSigSendType" SG_ 2683306022 DCU_InvtPhaVTemp 1;
BA_ "EventCommandSignal" SG_ 2683306022 DCU_InvtPhaWTemp 0;
BA_ "GatewayedSignals" SG_ 2683306022 DCU_InvtPhaWTemp 0;
BA_ "GenSigInvalidValue" SG_ 2683306022 DCU_InvtPhaWTemp 255;
BA_ "GenSigSendType" SG_ 2683306022 DCU_InvtPhaWTemp 1;
BA_ "EventCommandSignal" SG_ 2683306022 DCU_Stat1Temp 0;
BA_ "GatewayedSignals" SG_ 2683306022 DCU_Stat1Temp 0;
BA_ "GenSigInvalidValue" SG_ 2683306022 DCU_Stat1Temp 255;
BA_ "GenSigSendType" SG_ 2683306022 DCU_Stat1Temp 1;
BA_ "EventCommandSignal" SG_ 2683306022 DCU_Stat2Temp 0;
BA_ "GatewayedSignals" SG_ 2683306022 DCU_Stat2Temp 0;
BA_ "GenSigInvalidValue" SG_ 2683306022 DCU_Stat2Temp 255;
BA_ "GenSigSendType" SG_ 2683306022 DCU_Stat2Temp 1;
BA_ "EventCommandSignal" SG_ 2683306022 DCU_CtrlBoardTemp 0;
BA_ "GatewayedSignals" SG_ 2683306022 DCU_CtrlBoardTemp 0;
BA_ "GenSigInvalidValue" SG_ 2683306022 DCU_CtrlBoardTemp 255;
BA_ "GenSigSendType" SG_ 2683306022 DCU_CtrlBoardTemp 1;
BA_ "EventCommandSignal" SG_ 2683306022 DCU_DrvBoardTemp 0;
BA_ "GatewayedSignals" SG_ 2683306022 DCU_DrvBoardTemp 0;
BA_ "GenSigInvalidValue" SG_ 2683306022 DCU_DrvBoardTemp 255;
BA_ "GenSigSendType" SG_ 2683306022 DCU_DrvBoardTemp 1;
BA_ "EventCommandSignal" SG_ 2683306022 DCU_CapTemp 0;
BA_ "GatewayedSignals" SG_ 2683306022 DCU_CapTemp 0;
BA_ "GenSigInvalidValue" SG_ 2683306022 DCU_CapTemp 255;
BA_ "GenSigSendType" SG_ 2683306022 DCU_CapTemp 1;
BA_ "EventCommandSignal" SG_ 2683306022 DCU_FusastSafePathReq 0;
BA_ "GatewayedSignals" SG_ 2683306022 DCU_FusastSafePathReq 0;
BA_ "GenSigSendType" SG_ 2683306022 DCU_FusastSafePathReq 1;
BA_ "EventCommandSignal" SG_ 2683306022 DCU_FusaModeSt 0;
BA_ "GatewayedSignals" SG_ 2683306022 DCU_FusaModeSt 0;
BA_ "GenSigSendType" SG_ 2683306022 DCU_FusaModeSt 1;
BA_ "EventCommandSignal" SG_ 2683306022 DCU_FusaQDisChargeReq 0;
BA_ "GatewayedSignals" SG_ 2683306022 DCU_FusaQDisChargeReq 0;
BA_ "GenSigSendType" SG_ 2683306022 DCU_FusaQDisChargeReq 1;
BA_ "EventCommandSignal" SG_ 2683306022 DCU_FusastPWMEna 0;
BA_ "GatewayedSignals" SG_ 2683306022 DCU_FusastPWMEna 0;
BA_ "GenSigSendType" SG_ 2683306022 DCU_FusastPWMEna 1;
BA_ "EventCommandSignal" SG_ 2683306022 DCU_FusaErrCode 0;
BA_ "GatewayedSignals" SG_ 2683306022 DCU_FusaErrCode 0;
BA_ "GenSigSendType" SG_ 2683306022 DCU_FusaErrCode 1;
BA_ "EventCommandSignal" SG_ 2683306022 DCU_FusaRotSpdAct 0;
BA_ "GatewayedSignals" SG_ 2683306022 DCU_FusaRotSpdAct 0;
BA_ "GenSigSendType" SG_ 2683306022 DCU_FusaRotSpdAct 1;
BA_ "EventCommandSignal" SG_ 2683306022 DCU_FusaTorqAct 0;
BA_ "GatewayedSignals" SG_ 2683306022 DCU_FusaTorqAct 0;
BA_ "GenSigSendType" SG_ 2683306022 DCU_FusaTorqAct 1;
BA_ "EventCommandSignal" SG_ 2683306022 DCU_FusaFaultInfo7 0;
BA_ "GatewayedSignals" SG_ 2683306022 DCU_FusaFaultInfo7 0;
BA_ "GenSigSendType" SG_ 2683306022 DCU_FusaFaultInfo7 1;
BA_ "EventCommandSignal" SG_ 2683306022 DCU_FusaFaultInfo8 0;
BA_ "GatewayedSignals" SG_ 2683306022 DCU_FusaFaultInfo8 0;
BA_ "GenSigSendType" SG_ 2683306022 DCU_FusaFaultInfo8 1;
BA_ "EventCommandSignal" SG_ 2683306022 DCU_FaultData_RC 1;
BA_ "GatewayedSignals" SG_ 2683306022 DCU_FaultData_RC 0;
BA_ "GenSigSendType" SG_ 2683306022 DCU_FaultData_RC 0;
BA_ "EventCommandSignal" SG_ 2683306022 DCU_stHandleOff 1;
BA_ "GatewayedSignals" SG_ 2683306022 DCU_stHandleOff 0;
BA_ "GenSigSendType" SG_ 2683306022 DCU_stHandleOff 0;
BA_ "EventCommandSignal" SG_ 2683306022 DCU_stPWMEna 1;
BA_ "GatewayedSignals" SG_ 2683306022 DCU_stPWMEna 0;
BA_ "GenSigSendType" SG_ 2683306022 DCU_stPWMEna 0;
BA_ "EventCommandSignal" SG_ 2683306022 DCU_stMode 1;
BA_ "GatewayedSignals" SG_ 2683306022 DCU_stMode 0;
BA_ "GenSigSendType" SG_ 2683306022 DCU_stMode 0;
BA_ "GenSigStartValue" SG_ 2683306022 DCU_stMode 1;
BA_ "EventCommandSignal" SG_ 2683306022 DCU_FailCode 1;
BA_ "GatewayedSignals" SG_ 2683306022 DCU_FailCode 0;
BA_ "GenSigSendType" SG_ 2683306022 DCU_FailCode 0;
BA_ "EventCommandSignal" SG_ 2683306022 DCU_stASCProt 1;
BA_ "GatewayedSignals" SG_ 2683306022 DCU_stASCProt 0;
BA_ "GenSigSendType" SG_ 2683306022 DCU_stASCProt 0;
BA_ "EventCommandSignal" SG_ 2683306022 DCU_agRotorPosn 1;
BA_ "GatewayedSignals" SG_ 2683306022 DCU_agRotorPosn 0;
BA_ "GenSigSendType" SG_ 2683306022 DCU_agRotorPosn 0;
BA_ "EventCommandSignal" SG_ 2683306022 DCU_RelativeTime 1;
BA_ "GatewayedSignals" SG_ 2683306022 DCU_RelativeTime 0;
BA_ "GenSigSendType" SG_ 2683306022 DCU_RelativeTime 0;
BA_ "EventCommandSignal" SG_ 2683306022 DCU_stFaultFlag100us 1;
BA_ "GatewayedSignals" SG_ 2683306022 DCU_stFaultFlag100us 0;
BA_ "GenSigSendType" SG_ 2683306022 DCU_stFaultFlag100us 0;
BA_ "EventCommandSignal" SG_ 2683306022 DCU_PWMFreq 1;
BA_ "GatewayedSignals" SG_ 2683306022 DCU_PWMFreq 0;
BA_ "GenSigSendType" SG_ 2683306022 DCU_PWMFreq 0;
BA_ "GenSigStartValue" SG_ 2683306022 DCU_PWMFreq 10000;
BA_ "EventCommandSignal" SG_ 2683306022 DCU_uDcVolt 1;
BA_ "GatewayedSignals" SG_ 2683306022 DCU_uDcVolt 0;
BA_ "GenSigSendType" SG_ 2683306022 DCU_uDcVolt 0;
BA_ "EventCommandSignal" SG_ 2683306022 DCU_uLowVolt 1;
BA_ "GatewayedSignals" SG_ 2683306022 DCU_uLowVolt 0;
BA_ "GenSigSendType" SG_ 2683306022 DCU_uLowVolt 0;
BA_ "EventCommandSignal" SG_ 2683306022 DCU_iCurdFinalRef 1;
BA_ "GatewayedSignals" SG_ 2683306022 DCU_iCurdFinalRef 0;
BA_ "GenSigSendType" SG_ 2683306022 DCU_iCurdFinalRef 0;
BA_ "EventCommandSignal" SG_ 2683306022 DCU_iCurqFinalRef 1;
BA_ "GatewayedSignals" SG_ 2683306022 DCU_iCurqFinalRef 0;
BA_ "GenSigSendType" SG_ 2683306022 DCU_iCurqFinalRef 0;
BA_ "EventCommandSignal" SG_ 2683306022 DCU_iCurdFb 1;
BA_ "GatewayedSignals" SG_ 2683306022 DCU_iCurdFb 0;
BA_ "GenSigSendType" SG_ 2683306022 DCU_iCurdFb 0;
BA_ "EventCommandSignal" SG_ 2683306022 DCU_iCurqFb 1;
BA_ "GatewayedSignals" SG_ 2683306022 DCU_iCurqFb 0;
BA_ "GenSigSendType" SG_ 2683306022 DCU_iCurqFb 0;
BA_ "EventCommandSignal" SG_ 2683306022 DCU_iPhaCurU 1;
BA_ "GatewayedSignals" SG_ 2683306022 DCU_iPhaCurU 0;
BA_ "GenSigSendType" SG_ 2683306022 DCU_iPhaCurU 0;
BA_ "EventCommandSignal" SG_ 2683306022 DCU_iPhaCurV 1;
BA_ "GatewayedSignals" SG_ 2683306022 DCU_iPhaCurV 0;
BA_ "GenSigSendType" SG_ 2683306022 DCU_iPhaCurV 0;
BA_ "EventCommandSignal" SG_ 2683306022 DCU_iPhaCurW 1;
BA_ "GatewayedSignals" SG_ 2683306022 DCU_iPhaCurW 0;
BA_ "GenSigSendType" SG_ 2683306022 DCU_iPhaCurW 0;
BA_ "EventCommandSignal" SG_ 2683306022 DCU_uVoltdFinalRef 1;
BA_ "GatewayedSignals" SG_ 2683306022 DCU_uVoltdFinalRef 0;
BA_ "GenSigSendType" SG_ 2683306022 DCU_uVoltdFinalRef 0;
BA_ "EventCommandSignal" SG_ 2683306022 DCU_uVoltqFinalRef 1;
BA_ "GatewayedSignals" SG_ 2683306022 DCU_uVoltqFinalRef 0;
BA_ "GenSigSendType" SG_ 2683306022 DCU_uVoltqFinalRef 0;
BA_ "EventCommandSignal" SG_ 2683306022 DCU_iDcCur 1;
BA_ "GatewayedSignals" SG_ 2683306022 DCU_iDcCur 0;
BA_ "GenSigSendType" SG_ 2683306022 DCU_iDcCur 0;
BA_ "EventCommandSignal" SG_ 2683306022 DCU_ResFaultFlag 1;
BA_ "GatewayedSignals" SG_ 2683306022 DCU_ResFaultFlag 0;
BA_ "GenSigSendType" SG_ 2683306022 DCU_ResFaultFlag 0;
BA_ "EventCommandSignal" SG_ 2683306022 DCU_stTsc 1;
BA_ "GatewayedSignals" SG_ 2683306022 DCU_stTsc 0;
BA_ "GenSigSendType" SG_ 2683306022 DCU_stTsc 0;
BA_ "EventCommandSignal" SG_ 2683306022 DCU_OperatingCycle 1;
BA_ "GatewayedSignals" SG_ 2683306022 DCU_OperatingCycle 0;
BA_ "GenSigSendType" SG_ 2683306022 DCU_OperatingCycle 0;
BA_ "EventCommandSignal" SG_ 2683306022 DCU_Year 1;
BA_ "GatewayedSignals" SG_ 2683306022 DCU_Year 0;
BA_ "GenSigSendType" SG_ 2683306022 DCU_Year 0;
BA_ "GenSigStartValue" SG_ 2683306022 DCU_Year 15;
BA_ "EventCommandSignal" SG_ 2683306022 DCU_Month 1;
BA_ "GatewayedSignals" SG_ 2683306022 DCU_Month 0;
BA_ "GenSigSendType" SG_ 2683306022 DCU_Month 0;
BA_ "GenSigStartValue" SG_ 2683306022 DCU_Month 1;
BA_ "EventCommandSignal" SG_ 2683306022 DCU_Day 1;
BA_ "GatewayedSignals" SG_ 2683306022 DCU_Day 0;
BA_ "GenSigSendType" SG_ 2683306022 DCU_Day 0;
BA_ "GenSigStartValue" SG_ 2683306022 DCU_Day 1;
BA_ "EventCommandSignal" SG_ 2683306022 DCU_Hour 1;
BA_ "GatewayedSignals" SG_ 2683306022 DCU_Hour 0;
BA_ "GenSigSendType" SG_ 2683306022 DCU_Hour 0;
BA_ "EventCommandSignal" SG_ 2683306022 DCU_Minute 1;
BA_ "GatewayedSignals" SG_ 2683306022 DCU_Minute 0;
BA_ "GenSigSendType" SG_ 2683306022 DCU_Minute 0;
BA_ "EventCommandSignal" SG_ 2683306022 DCU_Second 1;
BA_ "GatewayedSignals" SG_ 2683306022 DCU_Second 0;
BA_ "GenSigSendType" SG_ 2683306022 DCU_Second 0;
BA_ "EventCommandSignal" SG_ 2683306022 DCU_stIgnition 1;
BA_ "GatewayedSignals" SG_ 2683306022 DCU_stIgnition 0;
BA_ "GenSigSendType" SG_ 2683306022 DCU_stIgnition 0;
BA_ "EventCommandSignal" SG_ 2683306022 DCU_OverCurrCount 1;
BA_ "GatewayedSignals" SG_ 2683306022 DCU_OverCurrCount 0;
BA_ "GenSigSendType" SG_ 2683306022 DCU_OverCurrCount 0;
BA_ "EventCommandSignal" SG_ 2683306022 DCU_stFS0B 1;
BA_ "GatewayedSignals" SG_ 2683306022 DCU_stFS0B 0;
BA_ "GenSigSendType" SG_ 2683306022 DCU_stFS0B 0;
BA_ "EventCommandSignal" SG_ 2683306022 DCU_stDrvCtrlMode 1;
BA_ "GatewayedSignals" SG_ 2683306022 DCU_stDrvCtrlMode 0;
BA_ "GenSigSendType" SG_ 2683306022 DCU_stDrvCtrlMode 0;
BA_ "EventCommandSignal" SG_ 2683306022 DCU_FbUT_Duty 1;
BA_ "GatewayedSignals" SG_ 2683306022 DCU_FbUT_Duty 0;
BA_ "GenSigSendType" SG_ 2683306022 DCU_FbUT_Duty 0;
BA_ "EventCommandSignal" SG_ 2683306022 DCU_ResInSinVal 1;
BA_ "GatewayedSignals" SG_ 2683306022 DCU_ResInSinVal 0;
BA_ "GenSigSendType" SG_ 2683306022 DCU_ResInSinVal 0;
BA_ "EventCommandSignal" SG_ 2683306022 DCU_stIGBTFault 1;
BA_ "GatewayedSignals" SG_ 2683306022 DCU_stIGBTFault 0;
BA_ "GenSigSendType" SG_ 2683306022 DCU_stIGBTFault 0;
BA_ "EventCommandSignal" SG_ 2683306022 DCU_stBigDataTrigger 1;
BA_ "GatewayedSignals" SG_ 2683306022 DCU_stBigDataTrigger 0;
BA_ "GenSigSendType" SG_ 2683306022 DCU_stBigDataTrigger 0;
BA_ "EventCommandSignal" SG_ 2683306022 DCU_RegUT_Duty 1;
BA_ "GatewayedSignals" SG_ 2683306022 DCU_RegUT_Duty 0;
BA_ "GenSigSendType" SG_ 2683306022 DCU_RegUT_Duty 0;
BA_ "EventCommandSignal" SG_ 2683306022 DCU_RegVT_Duty 1;
BA_ "GatewayedSignals" SG_ 2683306022 DCU_RegVT_Duty 0;
BA_ "GenSigSendType" SG_ 2683306022 DCU_RegVT_Duty 0;
BA_ "EventCommandSignal" SG_ 2683306022 DCU_RegWT_Duty 1;
BA_ "GatewayedSignals" SG_ 2683306022 DCU_RegWT_Duty 0;
BA_ "GenSigSendType" SG_ 2683306022 DCU_RegWT_Duty 0;
BA_ "EventCommandSignal" SG_ 2683306022 DCU_tiTspwmExeTime 1;
BA_ "GatewayedSignals" SG_ 2683306022 DCU_tiTspwmExeTime 0;
BA_ "GenSigSendType" SG_ 2683306022 DCU_tiTspwmExeTime 0;
BA_ "EventCommandSignal" SG_ 2683306022 DCU_FbVT_Duty 1;
BA_ "GatewayedSignals" SG_ 2683306022 DCU_FbVT_Duty 0;
BA_ "GenSigSendType" SG_ 2683306022 DCU_FbVT_Duty 0;
BA_ "EventCommandSignal" SG_ 2683306022 DCU_FbWT_Duty 1;
BA_ "GatewayedSignals" SG_ 2683306022 DCU_FbWT_Duty 0;
BA_ "GenSigSendType" SG_ 2683306022 DCU_FbWT_Duty 0;
BA_ "EventCommandSignal" SG_ 2683306022 DCU_FbUB_Duty 1;
BA_ "GatewayedSignals" SG_ 2683306022 DCU_FbUB_Duty 0;
BA_ "GenSigSendType" SG_ 2683306022 DCU_FbUB_Duty 0;
BA_ "EventCommandSignal" SG_ 2683306022 DCU_FbWB_Duty 1;
BA_ "GatewayedSignals" SG_ 2683306022 DCU_FbWB_Duty 0;
BA_ "GenSigSendType" SG_ 2683306022 DCU_FbWB_Duty 0;
BA_ "EventCommandSignal" SG_ 2683306022 DCU_stSBCFault 1;
BA_ "GatewayedSignals" SG_ 2683306022 DCU_stSBCFault 0;
BA_ "GenSigSendType" SG_ 2683306022 DCU_stSBCFault 0;
BA_ "GenSigStartValue" SG_ 2683306012 IPS_FUSA_DCDCLvCur2ValueFb 511;
BA_ "GenSigStartValue" SG_ 2683306012 IPS_FUSA_DCDCLvCur1ValueFb 511;
BA_ "GenSigSendType" SG_ 2683306025 IPS_1_CRC 1;
BA_ "GatewayedSignals" SG_ 2683306025 IPS_1_CRC 0;
BA_ "EventCommandSignal" SG_ 2683306025 IPS_1_CRC 0;
BA_ "GenSigSendType" SG_ 2683306025 IPS_1_Counter 1;
BA_ "GatewayedSignals" SG_ 2683306025 IPS_1_Counter 0;
BA_ "EventCommandSignal" SG_ 2683306025 IPS_1_Counter 0;
BA_ "GenSigSendType" SG_ 2683306025 IPS_DCDCDiagErrCode 1;
BA_ "GatewayedSignals" SG_ 2683306025 IPS_DCDCDiagErrCode 0;
BA_ "EventCommandSignal" SG_ 2683306025 IPS_DCDCDiagErrCode 0;
BA_ "GenSigSendType" SG_ 2683306025 IPS_DCDCModeSt 1;
BA_ "GatewayedSignals" SG_ 2683306025 IPS_DCDCModeSt 0;
BA_ "EventCommandSignal" SG_ 2683306025 IPS_DCDCModeSt 0;
BA_ "GenSigSendType" SG_ 2683306025 IPS_KL15State 1;
BA_ "GatewayedSignals" SG_ 2683306025 IPS_KL15State 0;
BA_ "EventCommandSignal" SG_ 2683306025 IPS_KL15State 0;
BA_ "GenSigSendType" SG_ 2683306025 IPS_DCDCVoltLvAct 1;
BA_ "GatewayedSignals" SG_ 2683306025 IPS_DCDCVoltLvAct 0;
BA_ "EventCommandSignal" SG_ 2683306025 IPS_DCDCVoltLvAct 0;
BA_ "GenSigSendType" SG_ 2683306025 IPS_DCDCCurrHvAct 1;
BA_ "GatewayedSignals" SG_ 2683306025 IPS_DCDCCurrHvAct 0;
BA_ "EventCommandSignal" SG_ 2683306025 IPS_DCDCCurrHvAct 0;
BA_ "GenSigSendType" SG_ 2683306025 IPS_DCDCCurrLvAct 1;
BA_ "GatewayedSignals" SG_ 2683306025 IPS_DCDCCurrLvAct 0;
BA_ "EventCommandSignal" SG_ 2683306025 IPS_DCDCCurrLvAct 0;
BA_ "GenSigSendType" SG_ 2683306025 IPS_SBCSafetyOutputSt 1;
BA_ "GatewayedSignals" SG_ 2683306025 IPS_SBCSafetyOutputSt 0;
BA_ "EventCommandSignal" SG_ 2683306025 IPS_SBCSafetyOutputSt 0;
BA_ "GenSigSendType" SG_ 2683306025 IPS_DCDCVoltHvAct 1;
BA_ "GatewayedSignals" SG_ 2683306025 IPS_DCDCVoltHvAct 0;
BA_ "EventCommandSignal" SG_ 2683306025 IPS_DCDCVoltHvAct 0;
BA_ "GenSigSendType" SG_ 2683306025 IPS_OBCDiagErrCode 1;
BA_ "GatewayedSignals" SG_ 2683306025 IPS_OBCDiagErrCode 0;
BA_ "EventCommandSignal" SG_ 2683306025 IPS_OBCDiagErrCode 0;
BA_ "GenSigSendType" SG_ 2683306025 IPS_OBCCC_St 1;
BA_ "GatewayedSignals" SG_ 2683306025 IPS_OBCCC_St 0;
BA_ "EventCommandSignal" SG_ 2683306025 IPS_OBCCC_St 0;
BA_ "GenSigSendType" SG_ 2683306025 IPS_OBCCC_Res 1;
BA_ "GatewayedSignals" SG_ 2683306025 IPS_OBCCC_Res 0;
BA_ "EventCommandSignal" SG_ 2683306025 IPS_OBCCC_Res 0;
BA_ "GenSigSendType" SG_ 2683306025 IPS_OBCDschDisable 1;
BA_ "GatewayedSignals" SG_ 2683306025 IPS_OBCDschDisable 0;
BA_ "EventCommandSignal" SG_ 2683306025 IPS_OBCDschDisable 0;
BA_ "GenSigSendType" SG_ 2683306025 IPS_OBCModeSt 1;
BA_ "GatewayedSignals" SG_ 2683306025 IPS_OBCModeSt 0;
BA_ "EventCommandSignal" SG_ 2683306025 IPS_OBCModeSt 0;
BA_ "GenSigSendType" SG_ 2683306025 IPS_DchgOverload 1;
BA_ "GatewayedSignals" SG_ 2683306025 IPS_DchgOverload 0;
BA_ "EventCommandSignal" SG_ 2683306025 IPS_DchgOverload 0;
BA_ "GenSigStartValue" SG_ 2683306025 IPS_OBCHvDcCurrAct 1024;
BA_ "GenSigSendType" SG_ 2683306025 IPS_OBCHvDcCurrAct 1;
BA_ "GatewayedSignals" SG_ 2683306025 IPS_OBCHvDcCurrAct 0;
BA_ "EventCommandSignal" SG_ 2683306025 IPS_OBCHvDcCurrAct 0;
BA_ "GenSigSendType" SG_ 2683306025 IPS_OBCHvDcVoltAct 1;
BA_ "GatewayedSignals" SG_ 2683306025 IPS_OBCHvDcVoltAct 0;
BA_ "EventCommandSignal" SG_ 2683306025 IPS_OBCHvDcVoltAct 0;
BA_ "GenSigSendType" SG_ 2683306025 IPS_OBCCC_Cap 1;
BA_ "GatewayedSignals" SG_ 2683306025 IPS_OBCCC_Cap 0;
BA_ "EventCommandSignal" SG_ 2683306025 IPS_OBCCC_Cap 0;
BA_ "GenSigSendType" SG_ 2683306025 IPS_OBCCpS2St 1;
BA_ "GatewayedSignals" SG_ 2683306025 IPS_OBCCpS2St 0;
BA_ "EventCommandSignal" SG_ 2683306025 IPS_OBCCpS2St 0;
BA_ "GenSigSendType" SG_ 2683306025 IPS_OBCCpFreqSt 1;
BA_ "GatewayedSignals" SG_ 2683306025 IPS_OBCCpFreqSt 0;
BA_ "EventCommandSignal" SG_ 2683306025 IPS_OBCCpFreqSt 0;
BA_ "GenSigSendType" SG_ 2683306025 IPS_OBCCPSt 1;
BA_ "GatewayedSignals" SG_ 2683306025 IPS_OBCCPSt 0;
BA_ "EventCommandSignal" SG_ 2683306025 IPS_OBCCPSt 0;
BA_ "GenSigSendType" SG_ 2683306025 IPS_OBCCp_DutyCycle 1;
BA_ "GatewayedSignals" SG_ 2683306025 IPS_OBCCp_DutyCycle 0;
BA_ "EventCommandSignal" SG_ 2683306025 IPS_OBCCp_DutyCycle 0;
BA_ "GenSigSendType" SG_ 2683306025 IPS_OBCCPVolt 1;
BA_ "GatewayedSignals" SG_ 2683306025 IPS_OBCCPVolt 0;
BA_ "EventCommandSignal" SG_ 2683306025 IPS_OBCCPVolt 0;
BA_ "GenSigSendType" SG_ 2683306025 IPS_OBCUacActL1 1;
BA_ "GatewayedSignals" SG_ 2683306025 IPS_OBCUacActL1 0;
BA_ "EventCommandSignal" SG_ 2683306025 IPS_OBCUacActL1 0;
BA_ "GenSigSendType" SG_ 2683306025 IPS_OBCUacActL2 1;
BA_ "GatewayedSignals" SG_ 2683306025 IPS_OBCUacActL2 0;
BA_ "EventCommandSignal" SG_ 2683306025 IPS_OBCUacActL2 0;
BA_ "GenSigSendType" SG_ 2683306025 IPS_OBCUacActL3 1;
BA_ "GatewayedSignals" SG_ 2683306025 IPS_OBCUacActL3 0;
BA_ "EventCommandSignal" SG_ 2683306025 IPS_OBCUacActL3 0;
BA_ "GenSigSendType" SG_ 2683306025 IPS_OBCCurrActL1 1;
BA_ "GatewayedSignals" SG_ 2683306025 IPS_OBCCurrActL1 0;
BA_ "EventCommandSignal" SG_ 2683306025 IPS_OBCCurrActL1 0;
BA_ "GenSigSendType" SG_ 2683306025 IPS_OBCCurrActL2 1;
BA_ "GatewayedSignals" SG_ 2683306025 IPS_OBCCurrActL2 0;
BA_ "EventCommandSignal" SG_ 2683306025 IPS_OBCCurrActL2 0;
BA_ "GenSigSendType" SG_ 2683306025 IPS_OBCCurrActL3 1;
BA_ "GatewayedSignals" SG_ 2683306025 IPS_OBCCurrActL3 0;
BA_ "EventCommandSignal" SG_ 2683306025 IPS_OBCCurrActL3 0;
BA_ "GenSigSendType" SG_ 2683306025 IPS_smo_ObcModeSt 1;
BA_ "GatewayedSignals" SG_ 2683306025 IPS_smo_ObcModeSt 0;
BA_ "EventCommandSignal" SG_ 2683306025 IPS_smo_ObcModeSt 0;
BA_ "GenSigSendType" SG_ 2683306025 IPS_smd_DcdcModeSt 1;
BA_ "GatewayedSignals" SG_ 2683306025 IPS_smd_DcdcModeSt 0;
BA_ "EventCommandSignal" SG_ 2683306025 IPS_smd_DcdcModeSt 0;
BA_ "GenSigSendType" SG_ 2683306025 IPS_WakeOriginSignal2 1;
BA_ "GatewayedSignals" SG_ 2683306025 IPS_WakeOriginSignal2 0;
BA_ "EventCommandSignal" SG_ 2683306025 IPS_WakeOriginSignal2 0;
BA_ "GenSigSendType" SG_ 2683306025 IPS_WakeOriginSignal1 1;
BA_ "GatewayedSignals" SG_ 2683306025 IPS_WakeOriginSignal1 0;
BA_ "EventCommandSignal" SG_ 2683306025 IPS_WakeOriginSignal1 0;
BA_ "GenSigSendType" SG_ 2683306025 IPS_OBCV2CSt 1;
BA_ "GatewayedSignals" SG_ 2683306025 IPS_OBCV2CSt 0;
BA_ "EventCommandSignal" SG_ 2683306025 IPS_OBCV2CSt 0;
BA_ "GenSigSendType" SG_ 2683306025 IPS_V2CMicSwitSt 1;
BA_ "GatewayedSignals" SG_ 2683306025 IPS_V2CMicSwitSt 0;
BA_ "EventCommandSignal" SG_ 2683306025 IPS_V2CMicSwitSt 0;
BA_ "GenSigSendType" SG_ 2683306025 Reserved1 1;
BA_ "GatewayedSignals" SG_ 2683306025 Reserved1 0;
BA_ "EventCommandSignal" SG_ 2683306025 Reserved1 0;
BA_ "GenSigSendType" SG_ 2683306025 IPS_1_FreshnessValue 1;
BA_ "GatewayedSignals" SG_ 2683306025 IPS_1_FreshnessValue 0;
BA_ "EventCommandSignal" SG_ 2683306025 IPS_1_FreshnessValue 0;
BA_ "GenSigSendType" SG_ 2683306025 IPS_1_MAC_Check 1;
BA_ "GatewayedSignals" SG_ 2683306025 IPS_1_MAC_Check 0;
BA_ "EventCommandSignal" SG_ 2683306025 IPS_1_MAC_Check 0;
BA_ "GenSigSendType" SG_ 2683306032 IPS_2_CRC 1;
BA_ "GatewayedSignals" SG_ 2683306032 IPS_2_CRC 0;
BA_ "EventCommandSignal" SG_ 2683306032 IPS_2_CRC 0;
BA_ "GenSigSendType" SG_ 2683306032 IPS_2_Counter 1;
BA_ "GatewayedSignals" SG_ 2683306032 IPS_2_Counter 0;
BA_ "EventCommandSignal" SG_ 2683306032 IPS_2_Counter 0;
BA_ "GenSigSendType" SG_ 2683306032 IPS_SwVersion 1;
BA_ "GatewayedSignals" SG_ 2683306032 IPS_SwVersion 0;
BA_ "EventCommandSignal" SG_ 2683306032 IPS_SwVersion 0;
BA_ "GenSigSendType" SG_ 2683306032 IPS_HwSt 1;
BA_ "GatewayedSignals" SG_ 2683306032 IPS_HwSt 0;
BA_ "EventCommandSignal" SG_ 2683306032 IPS_HwSt 0;
BA_ "GenSigSendType" SG_ 2683306032 IPS_RemoteDiagCode 1;
BA_ "GatewayedSignals" SG_ 2683306032 IPS_RemoteDiagCode 0;
BA_ "EventCommandSignal" SG_ 2683306032 IPS_RemoteDiagCode 0;
BA_ "GenSigSendType" SG_ 2683306032 IPS_TEL_DCDCFaultLampInd 1;
BA_ "GatewayedSignals" SG_ 2683306032 IPS_TEL_DCDCFaultLampInd 0;
BA_ "EventCommandSignal" SG_ 2683306032 IPS_TEL_DCDCFaultLampInd 0;
BA_ "GenSigSendType" SG_ 2683306032 IPS_TEL_DCDCTempOvrErr 1;
BA_ "GatewayedSignals" SG_ 2683306032 IPS_TEL_DCDCTempOvrErr 0;
BA_ "EventCommandSignal" SG_ 2683306032 IPS_TEL_DCDCTempOvrErr 0;
BA_ "GenSigSendType" SG_ 2683306032 IPS_TEL_DCDCModeSt 1;
BA_ "GatewayedSignals" SG_ 2683306032 IPS_TEL_DCDCModeSt 0;
BA_ "EventCommandSignal" SG_ 2683306032 IPS_TEL_DCDCModeSt 0;
BA_ "GenSigSendType" SG_ 2683306032 IPS_TempAct 1;
BA_ "GatewayedSignals" SG_ 2683306032 IPS_TempAct 0;
BA_ "EventCommandSignal" SG_ 2683306032 IPS_TempAct 0;
BA_ "GenSigSendType" SG_ 2683306032 IPS_DCDCFaultLampInd 1;
BA_ "GatewayedSignals" SG_ 2683306032 IPS_DCDCFaultLampInd 0;
BA_ "EventCommandSignal" SG_ 2683306032 IPS_DCDCFaultLampInd 0;
BA_ "GenSigSendType" SG_ 2683306032 IPS_DCDCKL30Volt 1;
BA_ "GatewayedSignals" SG_ 2683306032 IPS_DCDCKL30Volt 0;
BA_ "EventCommandSignal" SG_ 2683306032 IPS_DCDCKL30Volt 0;
BA_ "GenSigSendType" SG_ 2683306032 IPS_DCDCFlowReq 1;
BA_ "GatewayedSignals" SG_ 2683306032 IPS_DCDCFlowReq 0;
BA_ "EventCommandSignal" SG_ 2683306032 IPS_DCDCFlowReq 0;
BA_ "GenSigSendType" SG_ 2683306032 IPS_HVDCHVilSt 1;
BA_ "GatewayedSignals" SG_ 2683306032 IPS_HVDCHVilSt 0;
BA_ "EventCommandSignal" SG_ 2683306032 IPS_HVDCHVilSt 0;
BA_ "GenSigSendType" SG_ 2683306032 IPS_OBCChgPwrMax 1;
BA_ "GatewayedSignals" SG_ 2683306032 IPS_OBCChgPwrMax 0;
BA_ "EventCommandSignal" SG_ 2683306032 IPS_OBCChgPwrMax 0;
BA_ "GenSigSendType" SG_ 2683306032 IPS_OBCFlowReq 1;
BA_ "GatewayedSignals" SG_ 2683306032 IPS_OBCFlowReq 0;
BA_ "EventCommandSignal" SG_ 2683306032 IPS_OBCFlowReq 0;
BA_ "GenSigSendType" SG_ 2683306032 IPS_OBCFaultLampInd 1;
BA_ "GatewayedSignals" SG_ 2683306032 IPS_OBCFaultLampInd 0;
BA_ "EventCommandSignal" SG_ 2683306032 IPS_OBCFaultLampInd 0;
BA_ "GenSigSendType" SG_ 2683306032 IPS_ACHvilSt 1;
BA_ "GatewayedSignals" SG_ 2683306032 IPS_ACHvilSt 0;
BA_ "EventCommandSignal" SG_ 2683306032 IPS_ACHvilSt 0;
BA_ "GenSigSendType" SG_ 2683306032 IPS_DCDCState1 1;
BA_ "GatewayedSignals" SG_ 2683306032 IPS_DCDCState1 0;
BA_ "EventCommandSignal" SG_ 2683306032 IPS_DCDCState1 0;
BA_ "GenSigSendType" SG_ 2683306032 IPS_DCDCState2 1;
BA_ "GatewayedSignals" SG_ 2683306032 IPS_DCDCState2 0;
BA_ "EventCommandSignal" SG_ 2683306032 IPS_DCDCState2 0;
BA_ "GenSigSendType" SG_ 2683306032 IPS_DCDCState3 1;
BA_ "GatewayedSignals" SG_ 2683306032 IPS_DCDCState3 0;
BA_ "EventCommandSignal" SG_ 2683306032 IPS_DCDCState3 0;
BA_ "GenSigSendType" SG_ 2683306032 IPS_DCDCState4 1;
BA_ "GatewayedSignals" SG_ 2683306032 IPS_DCDCState4 0;
BA_ "EventCommandSignal" SG_ 2683306032 IPS_DCDCState4 0;
BA_ "GenSigSendType" SG_ 2683306032 IPS_DCDCState5 1;
BA_ "GatewayedSignals" SG_ 2683306032 IPS_DCDCState5 0;
BA_ "EventCommandSignal" SG_ 2683306032 IPS_DCDCState5 0;
BA_ "GenSigSendType" SG_ 2683306032 IPS_DCDCState6 1;
BA_ "GatewayedSignals" SG_ 2683306032 IPS_DCDCState6 0;
BA_ "EventCommandSignal" SG_ 2683306032 IPS_DCDCState6 0;
BA_ "GenSigSendType" SG_ 2683306032 IPS_OBCState1 1;
BA_ "GatewayedSignals" SG_ 2683306032 IPS_OBCState1 0;
BA_ "EventCommandSignal" SG_ 2683306032 IPS_OBCState1 0;
BA_ "GenSigSendType" SG_ 2683306032 IPS_OBCState2 1;
BA_ "GatewayedSignals" SG_ 2683306032 IPS_OBCState2 0;
BA_ "EventCommandSignal" SG_ 2683306032 IPS_OBCState2 0;
BA_ "GenSigSendType" SG_ 2683306032 IPS_OBCState3 1;
BA_ "GatewayedSignals" SG_ 2683306032 IPS_OBCState3 0;
BA_ "EventCommandSignal" SG_ 2683306032 IPS_OBCState3 0;
BA_ "GenSigSendType" SG_ 2683306032 IPS_OBCState4 1;
BA_ "GatewayedSignals" SG_ 2683306032 IPS_OBCState4 0;
BA_ "EventCommandSignal" SG_ 2683306032 IPS_OBCState4 0;
BA_ "GenSigSendType" SG_ 2683306032 IPS_OBCState5 1;
BA_ "GatewayedSignals" SG_ 2683306032 IPS_OBCState5 0;
BA_ "EventCommandSignal" SG_ 2683306032 IPS_OBCState5 0;
BA_ "GenSigSendType" SG_ 2683306032 IPS_ChgCurResp 1;
BA_ "GatewayedSignals" SG_ 2683306032 IPS_ChgCurResp 0;
BA_ "EventCommandSignal" SG_ 2683306032 IPS_ChgCurResp 0;
BA_ "GenSigSendType" SG_ 2683306032 IPS_ChgCurRespAvail 1;
BA_ "GatewayedSignals" SG_ 2683306032 IPS_ChgCurRespAvail 0;
BA_ "EventCommandSignal" SG_ 2683306032 IPS_ChgCurRespAvail 0;
BA_ "GenSigSendType" SG_ 2683306032 IPS_DCDCFaultLampIndOperationFla 1;
BA_ "GatewayedSignals" SG_ 2683306032 IPS_DCDCFaultLampIndOperationFla 0;
BA_ "EventCommandSignal" SG_ 2683306032 IPS_DCDCFaultLampIndOperationFla 0;
BA_ "SystemSignalLongSymbol" SG_ 2683306032 IPS_DCDCFaultLampIndOperationFla "IPS_DCDCFaultLampIndOperationFlag";
BA_ "GenSigSendType" SG_ 2683306032 IPS_DCDCFaultLampIndFlag 1;
BA_ "GatewayedSignals" SG_ 2683306032 IPS_DCDCFaultLampIndFlag 0;
BA_ "EventCommandSignal" SG_ 2683306032 IPS_DCDCFaultLampIndFlag 0;
BA_ "GenSigSendType" SG_ 2683306032 IPS_OBCFaultLampIndOperationFlag 1;
BA_ "GatewayedSignals" SG_ 2683306032 IPS_OBCFaultLampIndOperationFlag 0;
BA_ "EventCommandSignal" SG_ 2683306032 IPS_OBCFaultLampIndOperationFlag 0;
BA_ "GenSigSendType" SG_ 2683306032 IPS_OBCState6 1;
BA_ "GatewayedSignals" SG_ 2683306032 IPS_OBCState6 0;
BA_ "EventCommandSignal" SG_ 2683306032 IPS_OBCState6 0;
BA_ "GenSigSendType" SG_ 2683306032 IPS_OBCState7 1;
BA_ "GatewayedSignals" SG_ 2683306032 IPS_OBCState7 0;
BA_ "EventCommandSignal" SG_ 2683306032 IPS_OBCState7 0;
BA_ "GenSigSendType" SG_ 2683306032 IPS_OBCState8 1;
BA_ "GatewayedSignals" SG_ 2683306032 IPS_OBCState8 0;
BA_ "EventCommandSignal" SG_ 2683306032 IPS_OBCState8 0;
BA_ "GenSigSendType" SG_ 2683306032 IPS_OBCState9 1;
BA_ "GatewayedSignals" SG_ 2683306032 IPS_OBCState9 0;
BA_ "EventCommandSignal" SG_ 2683306032 IPS_OBCState9 0;
BA_ "GenSigSendType" SG_ 2683306032 IPS_OBCState10 1;
BA_ "GatewayedSignals" SG_ 2683306032 IPS_OBCState10 0;
BA_ "EventCommandSignal" SG_ 2683306032 IPS_OBCState10 0;
BA_ "GenSigSendType" SG_ 2683306032 IPS_OBCState11 1;
BA_ "GatewayedSignals" SG_ 2683306032 IPS_OBCState11 0;
BA_ "EventCommandSignal" SG_ 2683306032 IPS_OBCState11 0;
BA_ "GenSigSendType" SG_ 2683306032 IPS_DCDCState7 1;
BA_ "GatewayedSignals" SG_ 2683306032 IPS_DCDCState7 0;
BA_ "EventCommandSignal" SG_ 2683306032 IPS_DCDCState7 0;
BA_ "GenSigSendType" SG_ 2683306032 IPS_DCDCState8 1;
BA_ "GatewayedSignals" SG_ 2683306032 IPS_DCDCState8 0;
BA_ "EventCommandSignal" SG_ 2683306032 IPS_DCDCState8 0;
BA_ "GenSigSendType" SG_ 2683306032 IPS_DCDCState9 1;
BA_ "GatewayedSignals" SG_ 2683306032 IPS_DCDCState9 0;
BA_ "EventCommandSignal" SG_ 2683306032 IPS_DCDCState9 0;
BA_ "GenSigSendType" SG_ 2683306032 IPS_DCDCState10 1;
BA_ "GatewayedSignals" SG_ 2683306032 IPS_DCDCState10 0;
BA_ "EventCommandSignal" SG_ 2683306032 IPS_DCDCState10 0;
BA_ "GenSigStartValue" SG_ 2683306032 IPS_OBCAcIso_Res 63;
BA_ "GenSigSendType" SG_ 2683306032 IPS_OBCAcIso_Res 1;
BA_ "GatewayedSignals" SG_ 2683306032 IPS_OBCAcIso_Res 0;
BA_ "EventCommandSignal" SG_ 2683306032 IPS_OBCAcIso_Res 0;
BA_ "GenSigSendType" SG_ 2683306032 IPS_OBCState12 1;
BA_ "GatewayedSignals" SG_ 2683306032 IPS_OBCState12 0;
BA_ "EventCommandSignal" SG_ 2683306032 IPS_OBCState12 0;
BA_ "GenSigSendType" SG_ 2683306032 IPS_OBCState13 1;
BA_ "GatewayedSignals" SG_ 2683306032 IPS_OBCState13 0;
BA_ "EventCommandSignal" SG_ 2683306032 IPS_OBCState13 0;
BA_ "GenSigSendType" SG_ 2683306032 IPS_OBCState14 1;
BA_ "GatewayedSignals" SG_ 2683306032 IPS_OBCState14 0;
BA_ "EventCommandSignal" SG_ 2683306032 IPS_OBCState14 0;
BA_ "GenSigSendType" SG_ 2683306032 IPS_DCDCState11 1;
BA_ "GatewayedSignals" SG_ 2683306032 IPS_DCDCState11 0;
BA_ "EventCommandSignal" SG_ 2683306032 IPS_DCDCState11 0;
BA_ "GenSigSendType" SG_ 2683306032 IPS_DCDCState12 1;
BA_ "GatewayedSignals" SG_ 2683306032 IPS_DCDCState12 0;
BA_ "EventCommandSignal" SG_ 2683306032 IPS_DCDCState12 0;
BA_ "GenSigSendType" SG_ 2683306032 IPS_DCDCState13 1;
BA_ "GatewayedSignals" SG_ 2683306032 IPS_DCDCState13 0;
BA_ "EventCommandSignal" SG_ 2683306032 IPS_DCDCState13 0;
BA_ "GenSigSendType" SG_ 2683306032 IPS_OBCV2CRlySt 1;
BA_ "GatewayedSignals" SG_ 2683306032 IPS_OBCV2CRlySt 0;
BA_ "EventCommandSignal" SG_ 2683306032 IPS_OBCV2CRlySt 0;
BA_ "GenSigSendType" SG_ 2683306032 IPS_OBCV2CCurr 1;
BA_ "GatewayedSignals" SG_ 2683306032 IPS_OBCV2CCurr 0;
BA_ "EventCommandSignal" SG_ 2683306032 IPS_OBCV2CCurr 0;
BA_ "GenSigSendType" SG_ 2683306032 IPS_OBCV2LRlySt 1;
BA_ "GatewayedSignals" SG_ 2683306032 IPS_OBCV2LRlySt 0;
BA_ "EventCommandSignal" SG_ 2683306032 IPS_OBCV2LRlySt 0;
BA_ "GenSigSendType" SG_ 2683306032 IPS_2_FreshnessValue 1;
BA_ "GatewayedSignals" SG_ 2683306032 IPS_2_FreshnessValue 0;
BA_ "EventCommandSignal" SG_ 2683306032 IPS_2_FreshnessValue 0;
BA_ "GenSigSendType" SG_ 2683306032 IPS_2_MAC_Check 1;
BA_ "GatewayedSignals" SG_ 2683306032 IPS_2_MAC_Check 0;
BA_ "EventCommandSignal" SG_ 2683306032 IPS_2_MAC_Check 0;
BA_ "sigSecLevel" SG_ 1037 VCUFlNodeId "";
BA_ "sigSecLevel" SG_ 1037 VCUFlPni "";
BA_ "GenSigStartValue" SG_ 1037 VCUFlPni 1;
BA_ "sigSecLevel" SG_ 1037 VCUFlAwb "";
BA_ "sigSecLevel" SG_ 1037 VCUFlRmr "";
BA_ "sigSecLevel" SG_ 1037 VCUFlWus "";
BA_ "sigSecLevel" SG_ 1037 VCUFlNmSts "";
BA_ "sigSecLevel" SG_ 297 EpsFltSts "";
BA_ "sigDespEng" SG_ 297 EpsFltSts "EPS fault status.";
BA_ "sigSecLevel" SG_ 297 EPSSteerWhlBackStsFb "";
BA_ "sigSecLevel" SG_ 390 AbsFltLamp "";
BA_ "sigDespEng" SG_ 390 AbsFltLamp "ABS fault lamp. Signal indicates to light up ABS fault lamp.Anti-lock Braking System。";
BA_ "sigSecLevel" SG_ 390 EspTcsVdcFltLamp "";
BA_ "sigDespEng" SG_ 390 EspTcsVdcFltLamp "ESP TCS/VDC fault lamp. Signal indicates failure monitoring of TCS or VDC function. Not used for ABS. Traction Control System、Vehicle Dynamic Control。";
BA_ "sigSecLevel" SG_ 390 EspTcsVdcActvLamp "";
BA_ "sigDespEng" SG_ 390 EspTcsVdcActvLamp "ESP TCS/VDC active lamp. VDC or TCS active.Traction Control System、Vehicle Dynamic Control。";
BA_ "sigSecLevel" SG_ 390 HhcAvl "";
BA_ "sigDespEng" SG_ 390 HhcAvl "HHC available. Indicating HHC is available or not. ";
BA_ "sigSecLevel" SG_ 390 VdcActv "";
BA_ "sigDespEng" SG_ 390 VdcActv "VDC active. VDC operating or ESP operatingWhen ESP is active shall the system send out a bus signal.Not used for ABS.Vehicle Dynamic Control.";
BA_ "sigSecLevel" SG_ 390 TcsActv "";
BA_ "sigDespEng" SG_ 390 TcsActv "TCS active. TCS operating.When TCS is active shall the system send out a bus signal.Not used for ABS.";
BA_ "sigSecLevel" SG_ 390 AbsActv "";
BA_ "sigDespEng" SG_ 390 AbsActv "ABS active. ABS operationg When ABS is active shall the system send out a bus signal";
BA_ "sigSecLevel" SG_ 390 PBM_Fault_IND "";
BA_ "sigSecLevel" SG_ 390 EztAvl "";
BA_ "sigDespEng" SG_ 390 EztAvl "EZT available. Indicating EZT is available or not. ";
BA_ "sigSecLevel" SG_ 390 EztStb "";
BA_ "sigDespEng" SG_ 390 EztStb "EZT standy.EZT in standby mode or not.";
BA_ "sigSecLevel" SG_ 390 EztActv "";
BA_ "sigDespEng" SG_ 390 EztActv "EZT active. Indicates EZT in active or not.";
BA_ "sigSecLevel" SG_ 405 ApaSts "";
BA_ "sigDespEng" SG_ 405 ApaSts "APA function status.";
BA_ "sigSecLevel" SG_ 405 RpaSts "";
BA_ "sigDespEng" SG_ 405 RpaSts "RPA status";
BA_ "sigSecLevel" SG_ 422 PbmBrakePedalApplid "";
BA_ "sigDespEng" SG_ 422 PbmBrakePedalApplid "Indicates the brake pedaln switch position.";
BA_ "sigSecLevel" SG_ 422 PbmBrakePedalApplidVld "";
BA_ "sigDespEng" SG_ 422 PbmBrakePedalApplidVld "Validity of signal brake pedal position.";
BA_ "GenSigStartValue" SG_ 422 PbmBrakePedalApplidVld 1;
BA_ "sigSecLevel" SG_ 422 WhlBrkTotTorq "";
BA_ "sigDespEng" SG_ 422 WhlBrkTotTorq "Wheel brake total torque. This signal is the total hydraulic brake torque on 4 weels(except EPB etc.). If current brake torque is over 8188Nm, it will always send the max value 8188Nm.";
BA_ "sigSecLevel" SG_ 422 VALID_BOOSTER_CYLINDER_PRESSURE "";
BA_ "sigDespEng" SG_ 422 VALID_BOOSTER_CYLINDER_PRESSURE "Valid Information of the signal 'BOOSTER_CYLINDER_PRESSURE'";
BA_ "sigSecLevel" SG_ 422 PBM_MASTER_CYLINDER_PRESSURE "";
BA_ "sigDespEng" SG_ 422 PBM_MASTER_CYLINDER_PRESSURE "The PBM master pressure(offset is included).";
BA_ "sigSecLevel" SG_ 422 BOOSTER_CYLINDER_PRESSURE "";
BA_ "sigDespEng" SG_ 422 BOOSTER_CYLINDER_PRESSURE "The booster cylinder modified pressure(offset  is included).";
BA_ "sigSecLevel" SG_ 422 PBM_OUTPUT_ROD_DRIVER "";
BA_ "sigSecLevel" SG_ 422 PBM_OUTPUT_ROD_DRIVER_STATE "";
BA_ "sigSecLevel" SG_ 444 EPS_CrtSts "";
BA_ "sigDespEng" SG_ 444 EPS_CrtSts "EPS Current States";
BA_ "sigSecLevel" SG_ 523 NBS_20B_CheckSum "";
BA_ "sigDespEng" SG_ 523 NBS_20B_CheckSum "CRC checksum. DataID and the following 7 bytes are included in CRC checksum calculation. Refer to E2E Spec.（Profile：1ADataID 0x005F）";
BA_ "sigSecLevel" SG_ 523 NBS_20B_AliveCounter "";
BA_ "sigDespEng" SG_ 523 NBS_20B_AliveCounter "Rolling counter. Refer to E2E Spec.";
BA_ "sigSecLevel" SG_ 523 NBS_EBR_AVL_FLG "";
BA_ "sigSecLevel" SG_ 523 NBS_EBR_ACT_FLG "";
BA_ "sigSecLevel" SG_ 523 PBMLfcState "";
BA_ "sigSecLevel" SG_ 523 NBS_EBR_Tor_ACT "";
BA_ "sigSecLevel" SG_ 523 PBMRemDriEnaFlg "";
BA_ "sigSecLevel" SG_ 605 McuBrakeTorMax "";
BA_ "sigDespEng" SG_ 605 McuBrakeTorMax "A0项目中MCU接收此信号";
BA_ "sigSecLevel" SG_ 605 McuDriveTorMax "";
BA_ "sigDespEng" SG_ 605 McuDriveTorMax "A0项目中MCU接收此信号";
BA_ "sigSecLevel" SG_ 607 McuAntislipEnaCmd "";
BA_ "sigDespEng" SG_ 607 McuAntislipEnaCmd "A0项目中MCU接收此信号混动PDCU不发送";
BA_ "sigSecLevel" SG_ 607 McuDriStyleFactor "";
BA_ "sigDespEng" SG_ 607 McuDriStyleFactor "A0项目中MCU接收此信号混动PDCU不发送";
BA_ "sigSecLevel" SG_ 607 McuLpEnterAntislipEnaCmd "";
BA_ "sigDespEng" SG_ 607 McuLpEnterAntislipEnaCmd "A0项目中MCU接收此信号混动PDCU不发送";
BA_ "sigSecLevel" SG_ 607 MotorType "";
BA_ "sigSecLevel" SG_ 1532 WCBStcsVariant "";
BA_ "sigSecLevel" SG_ 892 BDCU_KeyPressSts "";
BA_ "sigDespEng" SG_ 892 BDCU_KeyPressSts "bdcu_keyor keypress presssts S";
BA_ "sigSecLevel" SG_ 915 ApaPasRdrDstFrntLe "";
BA_ "sigDespEng" SG_ 915 ApaPasRdrDstFrntLe "obstacle detection Distance by front left radar (long distance).";
BA_ "GenSigStartValue" SG_ 915 ApaPasRdrDstFrntLe 254;
BA_ "sigSecLevel" SG_ 915 ApaPasRdrDstFrntLeMin "";
BA_ "sigDespEng" SG_ 915 ApaPasRdrDstFrntLeMin "obstacle detection Distance by front left middle radar (long distance).";
BA_ "GenSigStartValue" SG_ 915 ApaPasRdrDstFrntLeMin 254;
BA_ "sigSecLevel" SG_ 915 ApaPasRdrDstFrntRiMin "";
BA_ "sigDespEng" SG_ 915 ApaPasRdrDstFrntRiMin "obstacle detection Distance by front right middle radar (long distance).";
BA_ "GenSigStartValue" SG_ 915 ApaPasRdrDstFrntRiMin 254;
BA_ "sigSecLevel" SG_ 915 ApaPasRdrDstFrntRi "";
BA_ "sigDespEng" SG_ 915 ApaPasRdrDstFrntRi "obstacle detection Distance by front right radar (long distance).";
BA_ "GenSigStartValue" SG_ 915 ApaPasRdrDstFrntRi 254;
BA_ "sigSecLevel" SG_ 915 ApaPasRdrDstReLe "";
BA_ "sigDespEng" SG_ 915 ApaPasRdrDstReLe "obstacle detection Distance by rear left radar (long distance).";
BA_ "GenSigStartValue" SG_ 915 ApaPasRdrDstReLe 254;
BA_ "sigSecLevel" SG_ 915 ApaPasRdrDstReLeMin "";
BA_ "sigDespEng" SG_ 915 ApaPasRdrDstReLeMin "obstacle detection Distance by rear left middle radar (long distance).";
BA_ "GenSigStartValue" SG_ 915 ApaPasRdrDstReLeMin 254;
BA_ "sigSecLevel" SG_ 915 ApaPasRdrDstrReRiMin "";
BA_ "sigDespEng" SG_ 915 ApaPasRdrDstrReRiMin "obstacle detection Distance by rear right middle radar (long distance).";
BA_ "GenSigStartValue" SG_ 915 ApaPasRdrDstrReRiMin 254;
BA_ "sigSecLevel" SG_ 915 ApaPasRdrDstrReRi "";
BA_ "sigDespEng" SG_ 915 ApaPasRdrDstrReRi "obstacle detection Distance by rear right radar (long distance).";
BA_ "GenSigStartValue" SG_ 915 ApaPasRdrDstrReRi 254;
BA_ "sigSecLevel" SG_ 915 ApaPasRdrDstrLeFrnt "";
BA_ "sigDespEng" SG_ 915 ApaPasRdrDstrLeFrnt "obstacle detection Distance by Left front radar (long distance).";
BA_ "GenSigStartValue" SG_ 915 ApaPasRdrDstrLeFrnt 254;
BA_ "sigSecLevel" SG_ 915 ApaPasRdrDstrLeRe "";
BA_ "sigDespEng" SG_ 915 ApaPasRdrDstrLeRe "obstacle detection Distance by Left rear radar (long distance).";
BA_ "GenSigStartValue" SG_ 915 ApaPasRdrDstrLeRe 254;
BA_ "sigSecLevel" SG_ 915 ApaPasRdrDstrRiFrnt "";
BA_ "sigDespEng" SG_ 915 ApaPasRdrDstrRiFrnt "obstacle detection Distance by Right front radar (long distance).";
BA_ "GenSigStartValue" SG_ 915 ApaPasRdrDstrRiFrnt 254;
BA_ "sigSecLevel" SG_ 915 ApaPasRdrDstRiRe "";
BA_ "sigDespEng" SG_ 915 ApaPasRdrDstRiRe "obstacle detection Distance by Right rear radar (long distance).";
BA_ "GenSigStartValue" SG_ 915 ApaPasRdrDstRiRe 254;
BA_ "sigSecLevel" SG_ 916 PasSysSts "";
BA_ "sigDespEng" SG_ 916 PasSysSts "Parking Assistantce  System Status包含主控制器，前雷达传感器，后雷达传感器，若存在主控制器与传感器同时故障的情况，均发0x2：Pas System Error";
BA_ "sigSecLevel" SG_ 504 PKC_RemDrvgReq "";
BA_ "sigSecLevel" SG_ 653 FRS_ObjFront1_HeadingAg "";
BA_ "GenSigStartValue" SG_ 653 FRS_ObjFront1_HeadingAg 180;
BA_ "sigSecLevel" SG_ 653 FRS_ObjFront2_HeadingAg "";
BA_ "GenSigStartValue" SG_ 653 FRS_ObjFront2_HeadingAg 180;
BA_ "sigSecLevel" SG_ 653 MPCObj1VX "";
BA_ "sigSecLevel" SG_ 653 FRS_ObjFront3_HeadingAg "";
BA_ "GenSigStartValue" SG_ 653 FRS_ObjFront3_HeadingAg 180;
BA_ "sigSecLevel" SG_ 653 FRS_ObjFront4_HeadingAg "";
BA_ "GenSigStartValue" SG_ 653 FRS_ObjFront4_HeadingAg 180;
BA_ "sigSecLevel" SG_ 653 FRS_ObjFront5_HeadingAg "";
BA_ "GenSigStartValue" SG_ 653 FRS_ObjFront5_HeadingAg 180;
BA_ "sigSecLevel" SG_ 653 FRS_ObjFront1_Dx "";
BA_ "sigDespEng" SG_ 653 FRS_ObjFront1_Dx "ThexdistancebetweentheegovehicleandthefrontACCobjectorAEBobject";
BA_ "sigSecLevel" SG_ 653 FRS_ObjFront1_Dy "";
BA_ "sigDespEng" SG_ 653 FRS_ObjFront1_Dy "TheydistancebetweentheegovehicleandthefrontACCobjectorAEBobject";
BA_ "sigSecLevel" SG_ 653 FRS_ObjFront1_Type "";
BA_ "sigDespEng" SG_ 653 FRS_ObjFront1_Type "Indicatethetypeofthethefrontobjectahead";
BA_ "sigSecLevel" SG_ 653 FRS_ObjFront1_Color "";
BA_ "sigDespEng" SG_ 653 FRS_ObjFront1_Color "Indicatethecar‘scolorfordisplay，ifthesituationischanged,theobject'scolorwillchange";
BA_ "sigSecLevel" SG_ 653 FRS_ObjFront2_Dx "";
BA_ "sigDespEng" SG_ 653 FRS_ObjFront2_Dx "ThexdistancebetweentheegovehicleandthefrontACCobjectorAEBobject";
BA_ "sigSecLevel" SG_ 653 FRS_ObjFront2_Dy "";
BA_ "sigDespEng" SG_ 653 FRS_ObjFront2_Dy "TheydistancebetweentheegovehicleandthefrontACCobjectorAEBobject";
BA_ "sigSecLevel" SG_ 653 FRS_ObjFront2_Type "";
BA_ "sigDespEng" SG_ 653 FRS_ObjFront2_Type "Indicatethetypeofthethefrontobjectahead";
BA_ "sigSecLevel" SG_ 653 FRS_ObjFront2_Color "";
BA_ "sigDespEng" SG_ 653 FRS_ObjFront2_Color "Indicatethecar‘scolorfordisplay，ifthesituationischanged,theobject'scolorwillchange";
BA_ "sigSecLevel" SG_ 653 MPCObj2VX "";
BA_ "sigSecLevel" SG_ 653 FRS_ObjFront3_Dx "";
BA_ "sigDespEng" SG_ 653 FRS_ObjFront3_Dx "ThexdistancebetweentheegovehicleandthefrontACCobjectorAEBobject";
BA_ "sigSecLevel" SG_ 653 FRS_ObjFront3_Dy "";
BA_ "sigDespEng" SG_ 653 FRS_ObjFront3_Dy "TheydistancebetweentheegovehicleandthefrontACCobjectorAEBobject";
BA_ "sigSecLevel" SG_ 653 FRS_ObjFront3_Type "";
BA_ "sigDespEng" SG_ 653 FRS_ObjFront3_Type "Indicatethetypeofthethefrontobjectahead";
BA_ "sigSecLevel" SG_ 653 FRS_ObjFront3_Color "";
BA_ "sigDespEng" SG_ 653 FRS_ObjFront3_Color "Indicatethecar‘scolorfordisplay，ifthesituationischanged,theobject'scolorwillchange";
BA_ "sigSecLevel" SG_ 653 FRS_ObjFront6_HeadingAg "";
BA_ "GenSigStartValue" SG_ 653 FRS_ObjFront6_HeadingAg 180;
BA_ "sigSecLevel" SG_ 653 MPCObj3VX "";
BA_ "sigSecLevel" SG_ 653 FRS_ObjFront4_Dx "";
BA_ "sigDespEng" SG_ 653 FRS_ObjFront4_Dx "ThexdistancebetweentheegovehicleandthefrontACCobjectorAEBobject";
BA_ "sigSecLevel" SG_ 653 FRS_ObjFront4_Dy "";
BA_ "sigDespEng" SG_ 653 FRS_ObjFront4_Dy "TheydistancebetweentheegovehicleandthefrontACCobjectorAEBobject";
BA_ "sigSecLevel" SG_ 653 FRS_ObjFront4_Type "";
BA_ "sigDespEng" SG_ 653 FRS_ObjFront4_Type "Indicatethetypeofthethefrontobjectahead";
BA_ "sigSecLevel" SG_ 653 FRS_ObjFront4_Color "";
BA_ "sigDespEng" SG_ 653 FRS_ObjFront4_Color "Indicatethecar‘scolorfordisplay，ifthesituationischanged,theobject'scolorwillchange";
BA_ "sigSecLevel" SG_ 653 MPCObj4VX "";
BA_ "sigSecLevel" SG_ 653 FRS_ObjFront5_Dx "";
BA_ "sigDespEng" SG_ 653 FRS_ObjFront5_Dx "ThexdistancebetweentheegovehicleandthefrontACCobjectorAEBobject";
BA_ "sigSecLevel" SG_ 653 FRS_ObjFront5_Dy "";
BA_ "sigDespEng" SG_ 653 FRS_ObjFront5_Dy "TheydistancebetweentheegovehicleandthefrontACCobjectorAEBobject";
BA_ "sigSecLevel" SG_ 653 FRS_ObjFront5_Type "";
BA_ "sigDespEng" SG_ 653 FRS_ObjFront5_Type "Indicatethetypeofthethefrontobjectahead";
BA_ "sigSecLevel" SG_ 653 FRS_ObjFront5_Color "";
BA_ "sigDespEng" SG_ 653 FRS_ObjFront5_Color "Indicatethecar‘scolorfordisplay，ifthesituationischanged,theobject'scolorwillchange";
BA_ "sigSecLevel" SG_ 653 MPCOb5VX "";
BA_ "sigSecLevel" SG_ 653 FRS_ObjFront6_Dx "";
BA_ "sigDespEng" SG_ 653 FRS_ObjFront6_Dx "ThexdistancebetweentheegovehicleandthefrontACCobjectorAEBobject";
BA_ "sigSecLevel" SG_ 653 FRS_ObjFront6_Dy "";
BA_ "sigDespEng" SG_ 653 FRS_ObjFront6_Dy "TheydistancebetweentheegovehicleandthefrontACCobjectorAEBobject";
BA_ "sigSecLevel" SG_ 653 FRS_ObjFront6_Type "";
BA_ "sigDespEng" SG_ 653 FRS_ObjFront6_Type "Indicatethetypeofthethefrontobjectahead";
BA_ "sigSecLevel" SG_ 653 FRS_ObjFront6_Color "";
BA_ "sigDespEng" SG_ 653 FRS_ObjFront6_Color "Indicatethecar‘scolorfordisplay，ifthesituationischanged,theobject'scolorwillchange";
BA_ "sigSecLevel" SG_ 653 MPCAccFobjDrvAwayInfo "";
BA_ "sigSecLevel" SG_ 653 MPCObj6VX "";
BA_ "sigSecLevel" SG_ 336 SteerWhlAg "";
BA_ "sigDespEng" SG_ 336 SteerWhlAg "Steering wheel angle, left is positive, right is negative.";
BA_ "GenSigStartValue" SG_ 336 SteerWhlAg 7800;
BA_ "sigSecLevel" SG_ 336 SteerWhlAgVld "";
BA_ "sigDespEng" SG_ 336 SteerWhlAgVld "Indicate Steer Wheel Angle signal valid or not.";
BA_ "sigSecLevel" SG_ 336 EPS_SteerWhlRotSpdDir "";
BA_ "sigDespEng" SG_ 336 EPS_SteerWhlRotSpdDir "Rotationspeeddirectionofthesteeringwheel.";
BA_ "sigSecLevel" SG_ 293 TcsRednEngTqFlg_F "";
BA_ "sigDespEng" SG_ 293 TcsRednEngTqFlg_F "TCS reduction engine torque flag. TCS engine torque reduction flag,Not used for ABS.";
BA_ "sigSecLevel" SG_ 293 TcsRednEngTqFlg_R "";
BA_ "sigDespEng" SG_ 293 TcsRednEngTqFlg_R "TCS reduction engine torque flag. TCS engine torque reduction flag,Not used for ABS.";
BA_ "sigSecLevel" SG_ 293 EV_F_RegenTarTrqFlg "";
BA_ "sigSecLevel" SG_ 293 EV_R_RegenTarTrqFlg "";
BA_ "sigDespEng" SG_ 293 EV_R_RegenTarTrqFlg "预留";
BA_ "sigSecLevel" SG_ 293 DtcIncEngTqFlg_F "";
BA_ "sigDespEng" SG_ 293 DtcIncEngTqFlg_F "DTC increase engine torque flag, also indicates DTC  active.";
BA_ "sigSecLevel" SG_ 293 DtcIncEngTqFlg_R "";
BA_ "sigDespEng" SG_ 293 DtcIncEngTqFlg_R "四驱车型预留";
BA_ "sigSecLevel" SG_ 293 EV_F_RegenTarTrq "";
BA_ "sigSecLevel" SG_ 293 EV_F_RegenTarTrqValid "";
BA_ "sigSecLevel" SG_ 293 EV_R_RegenTarTrq "";
BA_ "sigDespEng" SG_ 293 EV_R_RegenTarTrq "预留";
BA_ "sigSecLevel" SG_ 293 VlcApaIncTqReq "";
BA_ "sigSecLevel" SG_ 293 EspCtrl3Chks "";
BA_ "sigDespEng" SG_ 293 EspCtrl3Chks "CRC checksum. DataID and the following 7 bytes are included in CRC checksum calculation. Refer to E2E Spec.(Profile:1A;DataID:0x000C)";
BA_ "sigSecLevel" SG_ 293 EspCtrl3Cntr "";
BA_ "sigDespEng" SG_ 293 EspCtrl3Cntr "Rolling counter. Refer to E2E Spec.";
BA_ "sigSecLevel" SG_ 293 FrtMotMaxTarSpd "";
BA_ "sigSecLevel" SG_ 293 FrtdTCSCtrlModeReq "";
BA_ "sigSecLevel" SG_ 293 GearShiftInhb "";
BA_ "sigDespEng" SG_ 293 GearShiftInhb "Gear shift inhibit. Only for ESP.Used to inhibit the TCU shift. （电车若不用，预留）";
BA_ "sigSecLevel" SG_ 293 WhTorqueEst_FL "";
BA_ "sigSecLevel" SG_ 293 N_FrntAxleDTCTrqReq "";
BA_ "sigSecLevel" SG_ 293 N_ReAxleFastReductionTrqReq "";
BA_ "sigDespEng" SG_ 293 N_ReAxleFastReductionTrqReq "四驱车型预留";
BA_ "sigSecLevel" SG_ 293 N_ReAxleSlowReductionTrqReq "";
BA_ "sigDespEng" SG_ 293 N_ReAxleSlowReductionTrqReq "电车快慢扭发一样的值；四驱车型预留";
BA_ "sigSecLevel" SG_ 293 N_ReAxleDTCTrqReq "";
BA_ "sigDespEng" SG_ 293 N_ReAxleDTCTrqReq "四驱车型预留";
BA_ "sigSecLevel" SG_ 293 Esp125FV "";
BA_ "sigDespEng" SG_ 293 Esp125FV "Esp125FV, SecOC. Reserved.";
BA_ "sigSecLevel" SG_ 293 Esp125MAC "";
BA_ "sigDespEng" SG_ 293 Esp125MAC "Esp125MAC, SecOC. Reserved.";
BA_ "sigSecLevel" SG_ 293 WhTorqueEst_FR "";
BA_ "sigSecLevel" SG_ 293 WhTorqueEst_LR "";
VAL_ 2683306023 DCU_CCUEOPPowerSup 0 "Reserved" 1 "No active" 2 "Active" 3 "Reserved" ;
VAL_ 2683306023 DCU_ModeSt 15 "Emer_Discharge;" 14 "CapDischarge;" 13 "BuckDischarge;" 12 "Boost Charge;" 11 "CapPrecharge;" 10 "Power off;" 9 "Offsetcal;" 8 "Failure;" 7 "Afterrun;" 6 "Discharge;" 5 "HillholdCtrl;" 4 "TrqCtrl;" 3 "Ready;" 2 "Standby;" 1 "Init;" 0 "Reserved;" ;
VAL_ 2683306023 DCU_DstActive 1 "Active;" 0 "No Active;" ;
VAL_ 2683306023 DCU_GateDrvSt 3 "ShortCircuit;" 2 "Discharge;" 1 "PWMrun;" 0 "FreeWheel;" ;
VAL_ 2683306023 DCU_DMCInternalInit 1 "Initilize OK;" 0 "Initilize NOK;" ;
VAL_ 2683306023 DCU_DMCInternalInputQF 1 "Ture" 0 "False" ;
VAL_ 2683306023 DCU_DMCOperationStToBCS 3 "DMC Fault" 2 "DMC Off" 1 "DMC On" 0 "DMC Init" ;
VAL_ 2683306023 DCU_EOP_SpdSet 0 "Init" 4095 "Error" ;
VAL_ 2683306023 DCU_TrefFinal 0 "Init" 4095 "Error" ;
VAL_ 2683306023 DCU_Iq 0 "Init" 4095 "Error" ;
VAL_ 2683306023 DCU_Id 0 "Init" 4095 "Error" ;
VAL_ 2683306023 DCU_iCurqRef 0 "Init" 4095 "Error" ;
VAL_ 2683306023 DCU_iCurdRef 0 "Init" 4095 "Error" ;
VAL_ 408 BMC_DCUBattSt 1 "HVBattCntctr_Closed;" 0 "HVBattCntctr_Open;" ;
VAL_ 408 BMC_PwrDwnReq 1 "Request;" 0 "NotRequest;" ;
VAL_ 408 BMC_BoostChgModeReq 3 "Reserved" 2 "CapPrecharge complete" 1 "Request;" 0 "NotRequest;" ;
VAL_ 1037 VCUFlPni 1 "NM PDU contains PNI request" 0 "NM PDU contains no PNI request" ;
VAL_ 1037 VCUFlAwb 1 "Active Wakeup" 0 "Passive Wakeup" ;
VAL_ 1037 VCUFlRmr 1 "RMS requested" 0 "RMS not requested" ;
VAL_ 1037 VCUFlWus 255 "Reserved" 254 "Reserved" 253 "Reserved" 252 "Reserved" 251 "Reserved" 250 "Reserved" 249 "Reserved" 248 "Reserved" 247 "Reserved" 246 "Reserved" 245 "Reserved" 244 "Reserved" 243 "Reserved" 242 "Reserved" 241 "Reserved" 240 "Reserved" 239 "Reserved" 238 "Reserved" 237 "Reserved" 236 "Reserved" 235 "Reserved" 234 "Reserved" 233 "Reserved" 232 "Reserved" 231 "Reserved" 230 "Reserved" 229 "Reserved" 228 "Reserved" 227 "Reserved" 226 "Reserved" 225 "Reserved" 224 "Reserved" 223 "Reserved" 222 "Reserved" 221 "Reserved" 220 "Reserved" 219 "Reserved" 218 "Reserved" 217 "Reserved" 216 "Reserved" 215 "Reserved" 214 "Reserved" 213 "Reserved" 212 "Reserved" 211 "Reserved" 210 "Reserved" 209 "Reserved" 208 "Reserved" 207 "Reserved" 206 "Reserved" 205 "Reserved" 204 "Reserved" 203 "Reserved" 202 "Reserved" 201 "Reserved" 200 "Reserved" 199 "Reserved" 198 "Reserved" 197 "Reserved" 196 "Reserved" 195 "Reserved" 194 "Reserved" 193 "Reserved" 192 "Reserved" 191 "Reserved" 190 "Reserved" 189 "Reserved" 188 "Reserved" 187 "Reserved" 186 "Reserved" 185 "Reserved" 184 "Reserved" 183 "Reserved" 182 "Reserved" 181 "Reserved" 180 "Reserved" 179 "Reserved" 178 "Reserved" 177 "Reserved" 176 "Reserved" 175 "Reserved" 174 "Reserved" 173 "Reserved" 172 "Reserved" 171 "Reserved" 170 "Reserved" 169 "Reserved" 168 "Reserved" 167 "Reserved" 166 "Reserved" 165 "Reserved" 164 "Reserved" 163 "Reserved" 162 "Reserved" 161 "Reserved" 160 "Reserved" 159 "Reserved" 158 "Reserved" 157 "Reserved" 156 "Reserved" 155 "Reserved" 154 "Reserved" 153 "Reserved" 152 "Reserved" 151 "Reserved" 150 "Reserved" 149 "Reserved" 148 "Reserved" 147 "Reserved" 146 "Reserved" 145 "Reserved" 144 "Reserved" 143 "Reserved" 142 "Reserved" 141 "Reserved" 140 "Reserved" 139 "Reserved" 138 "Reserved" 137 "Reserved" 136 "Reserved" 135 "Reserved" 134 "Reserved" 133 "Reserved" 132 "Reserved" 131 "Reserved" 130 "Reserved" 129 "Reserved" 128 "Reserved" 127 "Reserved" 126 "Reserved" 125 "Reserved" 124 "Reserved" 123 "Reserved" 122 "Reserved" 121 "Reserved" 120 "Reserved" 119 "Reserved" 118 "Reserved" 117 "Reserved" 116 "Reserved" 115 "Reserved" 114 "Reserved" 113 "Reserved" 112 "Reserved" 111 "Reserved" 110 "Reserved" 109 "Reserved" 108 "Reserved" 107 "Reserved" 106 "Reserved" 105 "Reserved" 104 "Reserved" 103 "Reserved" 102 "Reserved" 101 "Reserved" 100 "Reserved" 99 "Reserved" 98 "Reserved" 97 "Reserved" 96 "Reserved" 95 "Reserved" 94 "Reserved" 93 "Reserved" 92 "Reserved" 91 "Reserved" 90 "Reserved" 89 "Reserved" 88 "Reserved" 87 "Reserved" 86 "Reserved" 85 "Reserved" 84 "Reserved" 83 "Reserved" 82 "Reserved" 81 "Reserved" 80 "Reserved" 79 "Reserved" 78 "Reserved" 77 "Reserved" 76 "Reserved" 75 "Reserved" 74 "Reserved" 73 "Reserved" 72 "Reserved" 71 "Reserved" 70 "Reserved" 69 "Reserved" 68 "Reserved" 67 "Reserved" 66 "Reserved" 65 "Reserved" 64 "Reserved" 63 "Reserved" 62 "Reserved" 61 "Reserved" 60 "Reserved" 59 "Reserved" 58 "Reserved" 57 "Reserved" 56 "Reserved" 55 "Reserved" 54 "Reserved" 53 "Reserved" 52 "Reserved" 51 "Reserved" 50 "Reserved" 49 "Reserved" 48 "Reserved" 47 "Reserved" 46 "Reserved" 45 "Reserved" 44 "Reserved" 43 "Reserved" 42 "Reserved" 41 "Reserved" 40 "Reserved" 39 "Reserved" 38 "Reserved" 37 "Reserved" 36 "Reserved" 35 "Reserved" 34 "Reserved" 33 "Reserved" 32 "Reserved" 31 "Reserved" 30 "Reserved" 29 "Reserved" 28 "Reserved" 27 "Reserved" 26 "Reserved" 25 "Reserved" 24 "Reserved" 23 "Reserved" 22 "Reserved" 21 "Reserved" 20 "Reserved" 19 "Reserved" 18 "Reserved" 17 "Reserved" 16 "Reserved" 15 "Reserved" 14 "Reserved" 13 "Reserved" 12 "Reserved" 11 "Reserved" 10 "Reserved" 9 "Reserved" 8 "Reserved" 7 "Reserved" 6 "Reserved" 5 "网络唤醒" 4 "CC2唤醒" 3 "CP唤醒" 2 "CC唤醒" 1 "KL15唤醒" 0 "NoWakeUpSource" ;
VAL_ 1037 VCUFlNmSts 1 "NotInRepMsgSt" 0 "InRepMsgSt" ;
VAL_ 297 EpsFltSts 3 "WarnLamp on（red）" 2 "WarnLamp on（yellow）" 1 "WarnLamp flash(reserved)" 0 "WarnLamp off" ;
VAL_ 297 EPSSteerWhlBackStsFb 3 "Reserved" 2 "已完成" 1 "未完成" 0 "待机" ;
VAL_ 390 AbsFltLamp 1 "Telltale Request" 0 "No Telltale Request" ;
VAL_ 390 EspTcsVdcFltLamp 1 "Telltale Request" 0 "No Telltale Request" ;
VAL_ 390 EspTcsVdcActvLamp 1 "Telltale Request" 0 "No Telltale Request" ;
VAL_ 390 HhcAvl 1 "Not available" 0 "Available" ;
VAL_ 390 VdcActv 1 "Active" 0 "Not active" ;
VAL_ 390 TcsActv 1 "Active" 0 "Not active" ;
VAL_ 390 AbsActv 1 "Active" 0 "Not active" ;
VAL_ 390 PBM_Fault_IND 3 "reserved" 2 "点亮仪表制动系统红灯（故障等级2）" 1 "点亮仪表制动系统黄灯（故障等級1）" 0 "无故障" ;
VAL_ 390 EztAvl 1 "Not available" 0 "Available" ;
VAL_ 390 EztStb 1 "Standby" 0 "Not standby" ;
VAL_ 390 EztActv 1 "Active" 0 "Not active" ;
VAL_ 405 ApaSts 15 "APA condition not meet" 14 "Reserved" 13 "Reserved" 12 "Reserved" 11 "Reserved" 10 "Reserved" 9 "APA selectable park in" 8 "APA Searching out" 7 "APA system fault" 6 "APA Suspend" 5 "APA Abort" 4 "APA Completed Successfully" 3 "APA Guidance active" 2 "APA Searching in" 1 "APA Standby" 0 "Off" ;
VAL_ 405 RpaSts 15 "invalid" 14 "RPA Not Available" 13 "RPA Out Abort" 12 "RPA Out Suspend" 11 "RPA Out Operating" 10 "RPA Out Ready" 9 "RPA System Fault" 8 "RPA Out Success" 7 "RPA In Success" 6 "RPA In Abort" 5 "RPA In Suspend" 4 "RPA In Operating" 3 "RPA In Ready" 2 "RPA Parking Out Standby" 1 "RPA Parking In Standby" 0 "RPA Off" ;
VAL_ 422 PbmBrakePedalApplid 1 "Brake pedal pressed" 0 "Brake pedal not pressed" ;
VAL_ 422 PbmBrakePedalApplidVld 3 "Reserved" 2 "Invalid" 1 "Valid" 0 "Reserved" ;
VAL_ 422 WhlBrkTotTorq 4095 "Invalid" ;
VAL_ 422 VALID_BOOSTER_CYLINDER_PRESSURE 3 "Reserved" 2 "Invalid" 1 "Valid" 0 "Initializing" ;
VAL_ 422 PBM_MASTER_CYLINDER_PRESSURE 4095 "Invalid" ;
VAL_ 422 BOOSTER_CYLINDER_PRESSURE 4095 "Invalid" ;
VAL_ 422 PBM_OUTPUT_ROD_DRIVER 4095 "Invalid" ;
VAL_ 422 PBM_OUTPUT_ROD_DRIVER_STATE 3 "Reserved" 2 "Faulty" 1 "Normal" 0 "Initialized" ;
VAL_ 444 EPS_CrtSts 1 "故障状态；" 0 "正常工作状态；" ;
VAL_ 523 NBS_EBR_AVL_FLG 3 "Reserved" 2 "Unavailable" 1 "Available" 0 "void" ;
VAL_ 523 NBS_EBR_ACT_FLG 3 "Reserved" 2 "Inactive" 1 "Active" 0 "void" ;
VAL_ 523 PBMLfcState 3 "Reserved" 2 "LFC_Standstill" 1 "LFC_FxControl" 0 "LFC_Standby" ;
VAL_ 523 NBS_EBR_Tor_ACT 65535 "Invalid" ;
VAL_ 523 PBMRemDriEnaFlg 1 "Active 使能" 0 "Inactive 未使能" ;
VAL_ 607 McuAntislipEnaCmd 1 "Enable" 0 "Disable" ;
VAL_ 607 McuLpEnterAntislipEnaCmd 1 "Enable" 0 "Disable" ;
VAL_ 607 MotorType 7 "预留" 6 "预留" 5 "海纳川电机（小）" 4 "菲仕电机（小）" 3 "中车电机" 2 "海纳川电机" 1 "菲仕电机" 0 "预留" ;
VAL_ 892 BDCU_KeyPressSts 1 "Active" 0 "Inactive" ;
VAL_ 915 ApaPasRdrDstFrntLe 255 "Invalid" 254 "no object was detected" 253 "Reserved" 252 "Reserved" 251 "Reserved" ;
VAL_ 915 ApaPasRdrDstFrntLeMin 255 "Invalid" 254 "no object was detected" 253 "Reserved" 252 "Reserved" 251 "Reserved" ;
VAL_ 915 ApaPasRdrDstFrntRiMin 255 "Invalid" 254 "no object was detected" 253 "Reserved" 252 "Reserved" 251 "Reserved" ;
VAL_ 915 ApaPasRdrDstFrntRi 255 "Invalid" 254 "no object was detected" 253 "Reserved" 252 "Reserved" 251 "Reserved" ;
VAL_ 915 ApaPasRdrDstReLe 255 "Invalid" 254 "no object was detected" 253 "Reserved" 252 "Reserved" 251 "Reserved" ;
VAL_ 915 ApaPasRdrDstReLeMin 255 "Invalid" 254 "no object was detected" 253 "Reserved" 252 "Reserved" 251 "Reserved" ;
VAL_ 915 ApaPasRdrDstrReRiMin 255 "Invalid" 254 "no object was detected" 253 "Reserved" 252 "Reserved" 251 "Reserved" ;
VAL_ 915 ApaPasRdrDstrReRi 255 "Invalid" 254 "no object was detected" 253 "Reserved" 252 "Reserved" 251 "Reserved" ;
VAL_ 915 ApaPasRdrDstrLeFrnt 255 "Invalid" 254 "no object was detected" 253 "Reserved" 252 "Reserved" 251 "Reserved" ;
VAL_ 915 ApaPasRdrDstrLeRe 255 "Invalid" 254 "no object was detected" 253 "Reserved" 252 "Reserved" 251 "Reserved" ;
VAL_ 915 ApaPasRdrDstrRiFrnt 255 "Invalid" 254 "no object was detected" 253 "Reserved" 252 "Reserved" 251 "Reserved" ;
VAL_ 915 ApaPasRdrDstRiRe 255 "Invalid" 254 "no object was detected" 253 "Reserved" 252 "Reserved" 251 "Reserved" ;
VAL_ 916 PasSysSts 15 "Invalid" 14 "Reserved" 13 "Reserved" 12 "Reserved" 11 "Reserved" 10 "Reserved" 9 "Reserved" 8 "Pas Side RR sensor Error" 7 "Pas Side RF sensor Error" 6 "Pas Side LR sensor Error" 5 "Pas Side LF sensor Error" 4 "Pas Rear Sensor Error" 3 "Pas Front Sensor Error" 2 "Pas System Error" 1 "active" 0 "Off" ;
VAL_ 504 PKC_RemDrvgReq 15 "Reserved" 14 "Reserved" 13 "遥控右转圈" 12 "遥控左转圈" 11 "开启碰撞检测" 10 "关闭碰撞检测" 9 "转向回正" 8 "后退右转" 7 "后退左转" 6 "前进右转" 5 "前进左转" 4 "右转" 3 "左转" 2 "后退" 1 "前进" 0 "待机" ;
VAL_ 653 FRS_ObjFront1_Type 7 "uncertain；" 6 "three-wheeler 三轮车" 5 "bus 公共汽车" 4 "pedestrian 行人" 3 "motorbike/Bicycle 二轮车" 2 "truck 卡车" 1 "passenger car 小轿车" 0 "Not Detected；" ;
VAL_ 653 FRS_ObjFront1_Color 7 "Reserved" 6 "Reserved" 5 "Orange  (Reserved)" 4 "White (Reserved)" 3 "Red" 2 "Yellow" 1 "Blue" 0 "Grey" ;
VAL_ 653 FRS_ObjFront2_Type 7 "uncertain；" 6 "three-wheeler 三轮车" 5 "bus 公共汽车" 4 "pedestrian 行人" 3 "motorbike/Bicycle 二轮车" 2 "truck 卡车" 1 "passenger car 小轿车" 0 "Not Detected；" ;
VAL_ 653 FRS_ObjFront2_Color 7 "Reserved" 6 "Reserved" 5 "Orange  (Reserved)" 4 "White (Reserved)" 3 "Red" 2 "Yellow" 1 "Blue" 0 "Grey" ;
VAL_ 653 FRS_ObjFront3_Type 7 "uncertain；" 6 "three-wheeler 三轮车" 5 "bus 公共汽车" 4 "pedestrian 行人" 3 "motorbike/Bicycle 二轮车" 2 "truck 卡车" 1 "passenger car 小轿车" 0 "Not Detected；" ;
VAL_ 653 FRS_ObjFront3_Color 7 "Reserved" 6 "Reserved" 5 "Orange  (Reserved)" 4 "White (Reserved)" 3 "Red" 2 "Yellow" 1 "Blue" 0 "Grey" ;
VAL_ 653 FRS_ObjFront4_Type 7 "uncertain；" 6 "three-wheeler 三轮车" 5 "bus 公共汽车" 4 "pedestrian 行人" 3 "motorbike/Bicycle 二轮车" 2 "truck 卡车" 1 "passenger car 小轿车" 0 "Not Detected；" ;
VAL_ 653 FRS_ObjFront4_Color 7 "Reserved" 6 "Reserved" 5 "Orange  (Reserved)" 4 "White (Reserved)" 3 "Red" 2 "Yellow" 1 "Blue" 0 "Grey" ;
VAL_ 653 FRS_ObjFront5_Type 7 "uncertain；" 6 "three-wheeler 三轮车" 5 "bus 公共汽车" 4 "pedestrian 行人" 3 "motorbike/Bicycle 二轮车" 2 "truck 卡车" 1 "passenger car 小轿车" 0 "Not Detected；" ;
VAL_ 653 FRS_ObjFront5_Color 7 "Reserved" 6 "Reserved" 5 "Orange  (Reserved)" 4 "White (Reserved)" 3 "Red" 2 "Yellow" 1 "Blue" 0 "Grey" ;
VAL_ 653 FRS_ObjFront6_Type 7 "uncertain；" 6 "three-wheeler 三轮车" 5 "bus 公共汽车" 4 "pedestrian 行人" 3 "motorbike/Bicycle 二轮车" 2 "truck 卡车" 1 "passenger car 小轿车" 0 "Not Detected；" ;
VAL_ 653 FRS_ObjFront6_Color 7 "Reserved" 6 "Reserved" 5 "Orange  (Reserved)" 4 "White (Reserved)" 3 "Red" 2 "Yellow" 1 "Blue" 0 "Grey" ;
VAL_ 653 MPCAccFobjDrvAwayInfo 1 "Active" 0 "Inactive" ;
VAL_ 336 SteerWhlAg 65535 "Invalid" ;
VAL_ 336 SteerWhlAgVld 3 "Reserved" 2 "Invalid" 1 "Valid" 0 "Initializing" ;
VAL_ 336 EPS_SteerWhlRotSpdDir 3 "Reserved" 2 "no ratation" 1 "negtive" 0 "positive" ;
VAL_ 293 TcsRednEngTqFlg_F 1 "Intervention" 0 "No intervention" ;
VAL_ 293 TcsRednEngTqFlg_R 1 "Intervention" 0 "No intervention" ;
VAL_ 293 EV_F_RegenTarTrqFlg 1 "Intervention" 0 "No intervention" ;
VAL_ 293 EV_R_RegenTarTrqFlg 1 "Intervention" 0 "No intervention" ;
VAL_ 293 DtcIncEngTqFlg_F 1 "Intervention" 0 "No intervention" ;
VAL_ 293 DtcIncEngTqFlg_R 1 "Intervention" 0 "No intervention" ;
VAL_ 293 EV_F_RegenTarTrq 65535 "Invalid" ;
VAL_ 293 EV_F_RegenTarTrqValid 3 "Reserved" 2 "Invalid" 1 "Valid" 0 "Initializing" ;
VAL_ 293 EV_R_RegenTarTrq 16383 "Invalid" ;
VAL_ 293 VlcApaIncTqReq 16383 "Invalid" ;
VAL_ 293 FrtdTCSCtrlModeReq 7 "Reserved" 6 "Reserved" 5 "Reserved" 4 "Reserved" 3 "CM_DMC_MAX" 2 "CM_DMC_TRQ" 1 "CM_DMC_RPM" 0 "CM_DMC_OFF" ;
VAL_ 293 GearShiftInhb 1 "Prevent gear shift" 0 "Use normal shift pattern" ;
VAL_ 293 N_FrntAxleDTCTrqReq 16383 "Invalid" ;
VAL_ 293 N_ReAxleFastReductionTrqReq 16383 "Invalid" ;
VAL_ 293 N_ReAxleSlowReductionTrqReq 16383 "Invalid" ;
VAL_ 293 N_ReAxleDTCTrqReq 16383 "Invalid" ;
